VERSION ""

NS_ :

BS_:

BU_: MXC CGW

BO_ 3221225472 VECTOR__INDEPENDENT_SIG_MSG: 0 Vector__XXX
 SG_ ESC_Logger17_Byte3 : 0|8@1+ (1,0) [0|0] "" Vector__XXX
 SG_ ESC_Logger17_Byte4 : 0|8@1+ (1,0) [0|0] "" Vector__XXX
 SG_ ESC_Logger17_Byte5 : 0|8@1+ (1,0) [0|0] "" Vector__XXX
 SG_ ESC_Logger17_Byte6 : 0|8@1+ (1,0) [0|0] "" Vector__XXX
 SG_ ESC_Logger17_Byte7 : 0|8@1+ (1,0) [0|0] "" Vector__XXX
 SG_ ESC_Logger17_Byte1 : 0|8@1+ (1,0) [0|0] "" Vector__XXX
 SG_ ESC_Logger18_Byte0 : 0|8@1+ (1,0) [0|0] "" Vector__XXX
 SG_ ESC_Logger18_Byte2 : 0|8@1+ (1,0) [0|0] "" Vector__XXX
 SG_ ESC_Logger18_Byte3 : 0|8@1+ (1,0) [0|0] "" Vector__XXX
 SG_ ESC_Logger18_Byte4 : 0|8@1+ (1,0) [0|0] "" Vector__XXX
 SG_ ESC_Logger18_Byte5 : 0|8@1+ (1,0) [0|0] "" Vector__XXX
 SG_ ESC_Logger18_Byte6 : 0|8@1+ (1,0) [0|0] "" Vector__XXX
 SG_ ESC_Logger18_Byte7 : 0|8@1+ (1,0) [0|0] "" Vector__XXX
 SG_ ESC_Logger18_Byte1 : 0|8@1+ (1,0) [0|0] "" Vector__XXX
 SG_ ESC_Logger19_Byte0 : 0|8@1+ (1,0) [0|0] "" Vector__XXX
 SG_ ESC_Logger19_Byte2 : 0|8@1+ (1,0) [0|0] "" Vector__XXX
 SG_ ESC_Logger19_Byte3 : 0|8@1+ (1,0) [0|0] "" Vector__XXX
 SG_ ESC_Logger19_Byte4 : 0|8@1+ (1,0) [0|0] "" Vector__XXX
 SG_ ESC_Logger19_Byte5 : 0|8@1+ (1,0) [0|0] "" Vector__XXX
 SG_ ESC_Logger19_Byte6 : 0|8@1+ (1,0) [0|0] "" Vector__XXX
 SG_ ESC_Logger19_Byte7 : 0|8@1+ (1,0) [0|0] "" Vector__XXX
 SG_ ESC_Logger19_Byte1 : 0|8@1+ (1,0) [0|0] "" Vector__XXX
 SG_ WAKEUP_Crc1Val : 0|8@1+ (1,0) [0|0] "" Vector__XXX
 SG_ WakeUp_DoorLock_DrvDrUnLkSta : 0|2@1+ (1,0) [0|0] "" Vector__XXX
 SG_ WAKEUP_AlvCnt1Val : 0|4@1+ (1,0) [0|0] "" Vector__XXX
 SG_ WakeUp_BCM_Ign1InSta : 0|2@1+ (1,0) [0|0] "" Vector__XXX
 SG_ WakeUp_RKE_BtnReq : 0|4@1+ (1,0) [0|0] "" Vector__XXX
 SG_ WakeUp_Lamp_SmrtWlcmLtOnReq : 0|2@1+ (1,0) [0|0] "" Vector__XXX
 SG_ WakeUp_DoorLock_AsstDrUnLkSta : 0|2@1+ (1,0) [0|0] "" Vector__XXX
 SG_ WakeUp_DoorLock_RrLftDrUnLkSta : 0|2@1+ (1,0) [0|0] "" Vector__XXX
 SG_ WakeUp_DoorLock_RrRtDrUnLkSta : 0|2@1+ (1,0) [0|0] "" Vector__XXX
 SG_ WakeUp_Warn_AsstDrSwSta : 0|2@1+ (1,0) [0|0] "" Vector__XXX
 SG_ WakeUp_Warn_RrLftDrSwSta : 0|2@1+ (1,0) [0|0] "" Vector__XXX
 SG_ WakeUp_Warn_RrRtDrSwSta : 0|2@1+ (1,0) [0|0] "" Vector__XXX
 SG_ WakeUp_Trunk_TrnkTlgtSwSta : 0|2@1+ (1,0) [0|0] "" Vector__XXX
 SG_ WakeUp_Warn_DrvDrSwSta : 0|2@1+ (1,0) [0|0] "" Vector__XXX
 SG_ ODS_Crc1Val : 0|16@1+ (1,0) [0|0] "" Vector__XXX
 SG_ ODS_AlvCnt1Val : 0|8@1+ (1,0) [0|0] "" Vector__XXX
 SG_ ODS_IdVal : 0|8@1+ (1,0) [0|0] "" Vector__XXX
 SG_ ODS_OccClassSta : 0|8@1+ (1,0) [0|0] "" Vector__XXX
 SG_ ODS_DiagSta : 0|8@1+ (1,0) [0|0] "" Vector__XXX
 SG_ ODS_SBRClassSta : 0|8@1+ (1,0) [0|0] "" Vector__XXX
 SG_ ICU_Crc11Val : 0|8@1+ (1,0) [0|0] "" Vector__XXX
 SG_ Bat_dischrg : 0|2@1+ (1,0) [0|0] "" Vector__XXX
 SG_ ICU_AlvCnt11Val : 0|4@1+ (1,0) [0|0] "" Vector__XXX
 SG_ Batt_SoCWarningValue : 0|8@1+ (1,0) [0|0] "%" Vector__XXX
 SG_ Batt_SoCAlertValue : 0|8@1+ (1,0) [0|0] "%" Vector__XXX
 SG_ C_StrgWhlHeatingOpt : 0|2@1+ (1,0) [0|0] "" Vector__XXX
 SG_ BCM_Crc2Val : 0|8@1+ (1,0) [0|0] "" Vector__XXX
 SG_ BCM_AlvCnt2Val : 0|4@1+ (1,0) [0|0] "" Vector__XXX
 SG_ BAlarm_BglrAlrmCurrentSta : 0|4@1+ (1,0) [0|0] "" Vector__XXX
 SG_ BAlarm_BglrAlrmSta : 0|2@1+ (1,0) [0|0] "" Vector__XXX
 SG_ BAlarm_PncAlrmSta : 0|2@1+ (1,0) [0|0] "" Vector__XXX
 SG_ BAlarm_BrglrHrnRlySta : 0|2@1+ (1,0) [0|0] "" Vector__XXX
 SG_ BCM_AccInSta : 0|2@1+ (1,0) [0|0] "" Vector__XXX
 SG_ BCM_Ign1InSta : 0|2@1+ (1,0) [0|0] "" Vector__XXX
 SG_ BCM_Ign2InSta : 0|2@1+ (1,0) [0|0] "" Vector__XXX
 SG_ BCM_IgnSwSta : 0|3@1+ (1,0) [0|0] "" Vector__XXX
 SG_ CCP_MDPS_RESP1_Byte0 : 0|8@1+ (1,0) [0|0] "" Vector__XXX
 SG_ CCP_MDPS_RESP1_Byte2 : 0|8@1+ (1,0) [0|0] "" Vector__XXX
 SG_ CCP_MDPS_RESP1_Byte3 : 0|8@1+ (1,0) [0|0] "" Vector__XXX
 SG_ CCP_MDPS_RESP1_Byte4 : 0|8@1+ (1,0) [0|0] "" Vector__XXX
 SG_ CCP_MDPS_RESP1_Byte5 : 0|8@1+ (1,0) [0|0] "" Vector__XXX
 SG_ CCP_MDPS_RESP1_Byte6 : 0|8@1+ (1,0) [0|0] "" Vector__XXX
 SG_ CCP_MDPS_RESP1_Byte7 : 0|8@1+ (1,0) [0|0] "" Vector__XXX
 SG_ CCP_MDPS_RESP1_Byte1 : 0|8@1+ (1,0) [0|0] "" Vector__XXX
 SG_ CCP_MDPS_REQ5_Byte0 : 0|8@1+ (1,0) [0|0] "" Vector__XXX
 SG_ CCP_MDPS_REQ5_Byte2 : 0|8@1+ (1,0) [0|0] "" Vector__XXX
 SG_ CCP_MDPS_REQ5_Byte3 : 0|8@1+ (1,0) [0|0] "" Vector__XXX
 SG_ CCP_MDPS_REQ5_Byte4 : 0|8@1+ (1,0) [0|0] "" Vector__XXX
 SG_ CCP_MDPS_REQ5_Byte5 : 0|8@1+ (1,0) [0|0] "" Vector__XXX
 SG_ CCP_MDPS_REQ5_Byte6 : 0|8@1+ (1,0) [0|0] "" Vector__XXX
 SG_ CCP_MDPS_REQ5_Byte7 : 0|8@1+ (1,0) [0|0] "" Vector__XXX
 SG_ CCP_MDPS_REQ5_Byte1 : 0|8@1+ (1,0) [0|0] "" Vector__XXX
 SG_ CCP_MDPS_RESP3_Byte0 : 0|8@1+ (1,0) [0|0] "" Vector__XXX
 SG_ CCP_MDPS_RESP3_Byte2 : 0|8@1+ (1,0) [0|0] "" Vector__XXX
 SG_ CCP_MDPS_RESP3_Byte3 : 0|8@1+ (1,0) [0|0] "" Vector__XXX
 SG_ CCP_MDPS_RESP3_Byte4 : 0|8@1+ (1,0) [0|0] "" Vector__XXX
 SG_ CCP_MDPS_RESP3_Byte5 : 0|8@1+ (1,0) [0|0] "" Vector__XXX
 SG_ CCP_MDPS_RESP3_Byte6 : 0|8@1+ (1,0) [0|0] "" Vector__XXX
 SG_ CCP_MDPS_RESP3_Byte7 : 0|8@1+ (1,0) [0|0] "" Vector__XXX
 SG_ CCP_MDPS_RESP3_Byte1 : 0|8@1+ (1,0) [0|0] "" Vector__XXX
 SG_ CCP_MDPS_RESP2_Byte0 : 0|8@1+ (1,0) [0|0] "" Vector__XXX
 SG_ CCP_MDPS_RESP2_Byte2 : 0|8@1+ (1,0) [0|0] "" Vector__XXX
 SG_ CCP_MDPS_RESP2_Byte3 : 0|8@1+ (1,0) [0|0] "" Vector__XXX
 SG_ CCP_MDPS_RESP2_Byte4 : 0|8@1+ (1,0) [0|0] "" Vector__XXX
 SG_ CCP_MDPS_RESP2_Byte5 : 0|8@1+ (1,0) [0|0] "" Vector__XXX
 SG_ CCP_MDPS_RESP2_Byte6 : 0|8@1+ (1,0) [0|0] "" Vector__XXX
 SG_ CCP_MDPS_RESP2_Byte7 : 0|8@1+ (1,0) [0|0] "" Vector__XXX
 SG_ CCP_MDPS_RESP2_Byte1 : 0|8@1+ (1,0) [0|0] "" Vector__XXX
 SG_ CCP_MDPS_REQ2_Byte0 : 0|8@1+ (1,0) [0|0] "" Vector__XXX
 SG_ CCP_MDPS_REQ2_Byte2 : 0|8@1+ (1,0) [0|0] "" Vector__XXX
 SG_ CCP_MDPS_REQ2_Byte3 : 0|8@1+ (1,0) [0|0] "" Vector__XXX
 SG_ CCP_MDPS_REQ2_Byte4 : 0|8@1+ (1,0) [0|0] "" Vector__XXX
 SG_ CCP_MDPS_REQ2_Byte5 : 0|8@1+ (1,0) [0|0] "" Vector__XXX
 SG_ CCP_MDPS_REQ2_Byte6 : 0|8@1+ (1,0) [0|0] "" Vector__XXX
 SG_ CCP_MDPS_REQ2_Byte7 : 0|8@1+ (1,0) [0|0] "" Vector__XXX
 SG_ CCP_MDPS_REQ2_Byte1 : 0|8@1+ (1,0) [0|0] "" Vector__XXX
 SG_ CCP_MDPS_REQ1_Byte0 : 0|8@1+ (1,0) [0|0] "" Vector__XXX
 SG_ CCP_MDPS_REQ1_Byte2 : 0|8@1+ (1,0) [0|0] "" Vector__XXX
 SG_ CCP_MDPS_REQ1_Byte3 : 0|8@1+ (1,0) [0|0] "" Vector__XXX
 SG_ CCP_MDPS_REQ1_Byte4 : 0|8@1+ (1,0) [0|0] "" Vector__XXX
 SG_ CCP_MDPS_REQ1_Byte5 : 0|8@1+ (1,0) [0|0] "" Vector__XXX
 SG_ CCP_MDPS_REQ1_Byte6 : 0|8@1+ (1,0) [0|0] "" Vector__XXX
 SG_ CCP_MDPS_REQ1_Byte7 : 0|8@1+ (1,0) [0|0] "" Vector__XXX
 SG_ CCP_MDPS_REQ1_Byte1 : 0|8@1+ (1,0) [0|0] "" Vector__XXX
 SG_ CCP_MDPS_REQ4_Byte0 : 0|8@1+ (1,0) [0|0] "" Vector__XXX
 SG_ CCP_MDPS_REQ4_Byte2 : 0|8@1+ (1,0) [0|0] "" Vector__XXX
 SG_ CCP_MDPS_REQ4_Byte3 : 0|8@1+ (1,0) [0|0] "" Vector__XXX
 SG_ CCP_MDPS_REQ4_Byte4 : 0|8@1+ (1,0) [0|0] "" Vector__XXX
 SG_ CCP_MDPS_REQ4_Byte5 : 0|8@1+ (1,0) [0|0] "" Vector__XXX
 SG_ CCP_MDPS_REQ4_Byte6 : 0|8@1+ (1,0) [0|0] "" Vector__XXX
 SG_ CCP_MDPS_REQ4_Byte7 : 0|8@1+ (1,0) [0|0] "" Vector__XXX
 SG_ CCP_MDPS_REQ4_Byte1 : 0|8@1+ (1,0) [0|0] "" Vector__XXX
 SG_ CCP_MDPS_REQ3_Byte0 : 0|8@1+ (1,0) [0|0] "" Vector__XXX
 SG_ CCP_MDPS_REQ3_Byte2 : 0|8@1+ (1,0) [0|0] "" Vector__XXX
 SG_ CCP_MDPS_REQ3_Byte3 : 0|8@1+ (1,0) [0|0] "" Vector__XXX
 SG_ CCP_MDPS_REQ3_Byte4 : 0|8@1+ (1,0) [0|0] "" Vector__XXX
 SG_ CCP_MDPS_REQ3_Byte5 : 0|8@1+ (1,0) [0|0] "" Vector__XXX
 SG_ CCP_MDPS_REQ3_Byte6 : 0|8@1+ (1,0) [0|0] "" Vector__XXX
 SG_ CCP_MDPS_REQ3_Byte7 : 0|8@1+ (1,0) [0|0] "" Vector__XXX
 SG_ CCP_MDPS_REQ3_Byte1 : 0|8@1+ (1,0) [0|0] "" Vector__XXX
 SG_ CF_AVN_CluWelcomeSnd : 0|2@1+ (1,0) [0|0] "" Vector__XXX
 SG_ CF_AVN_CluTransmissionDisp : 0|2@1+ (1,0) [0|0] "" Vector__XXX
 SG_ CF_AVN_CluWiperLight : 0|2@1+ (1,0) [0|0] "" Vector__XXX
 SG_ CF_AVN_CluRoadInfoGuide : 0|2@1+ (1,0) [0|0] "" Vector__XXX
 SG_ CF_AVN_CluUserSettingPeriod : 0|7@1+ (1,0) [0|0] "" Vector__XXX
 SG_ CF_AVN_CluAutoInitFuelEconomy : 0|3@1+ (1,0) [0|0] "" Vector__XXX
 SG_ CF_AVN_CluSubspeedOdometerDisp : 0|2@1+ (1,0) [0|0] "" Vector__XXX
 SG_ CF_AVN_CluFuelEconUnit_mi : 0|2@1+ (1,0) [0|0] "" Vector__XXX
 SG_ CF_AVN_CluFuelEconUnit_km : 0|2@1+ (1,0) [0|0] "" Vector__XXX
 SG_ CF_AVN_CluUserSettingDistance : 0|17@1+ (1,0) [0|0] "" Vector__XXX
 SG_ CF_AVN_CluVoiceVolume : 0|3@1+ (1,0) [0|0] "" Vector__XXX
 SG_ CF_AVN_EVReset : 0|2@1+ (1,0) [0|0] "" Vector__XXX
 SG_ CF_AVN_UnitReset : 0|2@1+ (1,0) [0|0] "" Vector__XXX
 SG_ CF_AVN_IcyRoadWarn : 0|2@1+ (1,0) [0|0] "" Vector__XXX
 SG_ CF_AVN_CluServiceReminderReset : 0|2@1+ (1,0) [0|0] "" Vector__XXX
 SG_ CF_AVN_CluUSMReset : 0|2@1+ (1,0) [0|0] "" Vector__XXX
 SG_ CF_AVN_CluServiceReminderSet : 0|2@1+ (1,0) [0|0] "" Vector__XXX
 SG_ EPB_Crc1Val : 0|16@1+ (1,0) [0|0] "" Vector__XXX
 SG_ EPB_AlvCnt1Val : 0|8@1+ (1,0) [0|0] "" Vector__XXX
 SG_ EPB_LmpStaDis : 0|4@1+ (1,0) [0|0] "" Vector__XXX
 SG_ EPB_FlrLmpStaDis : 0|4@1+ (1,0) [0|0] "" Vector__XXX
 SG_ EPB_OutDataDis : 0|8@1+ (1,0) [0|0] "" Vector__XXX
 SG_ EPB_AlrmReq : 0|2@1+ (1,0) [0|0] "" Vector__XXX
 SG_ EPB_SwPosSta : 0|2@1+ (1,0) [0|0] "" Vector__XXX
 SG_ EPB_RrBrkLtActvReq : 0|2@1+ (1,0) [0|0] "" Vector__XXX
 SG_ EPB_FrcErrSta : 0|2@1+ (1,0) [0|0] "" Vector__XXX
 SG_ EPB_DynmBrkFrcReqSigSta : 0|2@1+ (1,0) [0|0] "" Vector__XXX
 SG_ EPB_FrcSta : 0|3@1+ (1,0) [0|0] "" Vector__XXX
 SG_ EPB_FlSta : 0|3@1+ (1,0) [0|0] "" Vector__XXX
 SG_ EPB_EscReqAckSta : 0|2@1+ (1,0) [0|0] "" Vector__XXX
 SG_ EPB_DynmBrkFrcReq : 0|2@1+ (1,0) [0|0] "" Vector__XXX
 SG_ EPB_ActlFrcVal : 0|12@1+ (1,-1000) [0|0] "" Vector__XXX
 SG_ EPB_DynmBrkFrcDclReq : 0|8@1+ (0.01,0) [0|0] "g" Vector__XXX
 SG_ CCP_MDPS_RESP5_Byte0 : 0|8@1+ (1,0) [0|0] "" Vector__XXX
 SG_ CCP_MDPS_RESP5_Byte2 : 0|8@1+ (1,0) [0|0] "" Vector__XXX
 SG_ CCP_MDPS_RESP5_Byte3 : 0|8@1+ (1,0) [0|0] "" Vector__XXX
 SG_ CCP_MDPS_RESP5_Byte4 : 0|8@1+ (1,0) [0|0] "" Vector__XXX
 SG_ CCP_MDPS_RESP5_Byte5 : 0|8@1+ (1,0) [0|0] "" Vector__XXX
 SG_ CCP_MDPS_RESP5_Byte6 : 0|8@1+ (1,0) [0|0] "" Vector__XXX
 SG_ CCP_MDPS_RESP5_Byte7 : 0|8@1+ (1,0) [0|0] "" Vector__XXX
 SG_ CCP_MDPS_RESP5_Byte1 : 0|8@1+ (1,0) [0|0] "" Vector__XXX
 SG_ CCP_MDPS_RESP4_Byte0 : 0|8@1+ (1,0) [0|0] "" Vector__XXX
 SG_ CCP_MDPS_RESP4_Byte2 : 0|8@1+ (1,0) [0|0] "" Vector__XXX
 SG_ CCP_MDPS_RESP4_Byte3 : 0|8@1+ (1,0) [0|0] "" Vector__XXX
 SG_ CCP_MDPS_RESP4_Byte4 : 0|8@1+ (1,0) [0|0] "" Vector__XXX
 SG_ CCP_MDPS_RESP4_Byte5 : 0|8@1+ (1,0) [0|0] "" Vector__XXX
 SG_ CCP_MDPS_RESP4_Byte6 : 0|8@1+ (1,0) [0|0] "" Vector__XXX
 SG_ CCP_MDPS_RESP4_Byte7 : 0|8@1+ (1,0) [0|0] "" Vector__XXX
 SG_ CCP_MDPS_RESP4_Byte1 : 0|8@1+ (1,0) [0|0] "" Vector__XXX
 SG_ ICU_Crc1Val : 0|8@1+ (1,0) [0|0] "" Vector__XXX
 SG_ ICU_AlvCnt1Val : 0|4@1+ (1,0) [0|0] "" Vector__XXX
 SG_ DoorLock_DrvrDrUnLkPsvAcsReq : 0|2@1+ (1,0) [0|0] "" Vector__XXX
 SG_ DoorLock_RmtKeyDrvrDrUnLkReq : 0|2@1+ (1,0) [0|0] "" Vector__XXX
 SG_ SEG_V2_Offset : 0|13@1+ (1,0) [0|0] "m" Vector__XXX
 SG_ SEG_V2_PathIndex : 0|6@1+ (1,0) [0|0] "" Vector__XXX
 SG_ SEG_V2_CyclicCounter : 0|2@1+ (1,0) [0|0] "" Vector__XXX
 SG_ SEG_V2_Retransmission : 0|1@1+ (1,0) [0|0] "" Vector__XXX
 SG_ SEG_V2_CalculatedRoute : 0|2@1+ (1,0) [0|0] "" Vector__XXX
 SG_ SEG_V2_FuncRoadClass : 0|3@1+ (1,0) [0|0] "" Vector__XXX
 SG_ SEG_V2_SpeedLimit : 0|5@1+ (1,0) [0|0] "" Vector__XXX
 SG_ SEG_V2_FormOfWay : 0|4@1+ (1,0) [0|0] "" Vector__XXX
 SG_ SEG_V2_DirectionLanes : 0|4@1+ (1,0) [0|0] "" Vector__XXX
 SG_ SEG_V2_SpeedLimitUnder5 : 0|3@1+ (1,0) [0|0] "" Vector__XXX
 SG_ RR_C_RDR_Crc1Val : 0|16@1+ (1,0) [0|0] "" Vector__XXX
 SG_ FR_C_RDR_RR_C_RDR_FCA_Plus_Sta : 0|2@1+ (1,0) [0|0] "" Vector__XXX
 SG_ RR_C_RDR_AlvCnt1Val : 0|8@1+ (1,0) [0|0] "" Vector__XXX
 SG_ RCCW_Sta : 0|4@1+ (1,0) [0|0] "" Vector__XXX
 SG_ RCCW_OnOffEquipSt : 0|2@1+ (1,0) [0|0] "" Vector__XXX
 SG_ RCCW_LftIndSta : 0|2@1+ (1,0) [0|0] "" Vector__XXX
 SG_ RCCW_RtIndSta : 0|2@1+ (1,0) [0|0] "" Vector__XXX
 SG_ RCCW_LftSndWrngSta : 0|2@1+ (1,0) [0|0] "" Vector__XXX
 SG_ RCCW_RtSndWrngSta : 0|2@1+ (1,0) [0|0] "" Vector__XXX
 SG_ RCCW_LftWrngIndBriLvlVal : 0|8@1+ (1,0) [0|0] "" Vector__XXX
 SG_ RCCW_RtWrngIndBriLvlVal : 0|8@1+ (1,0) [0|0] "" Vector__XXX
 SG_ RCCA_Deccel_Req : 0|4@1+ (0.04,0) [0|0] "g" Vector__XXX
 SG_ RCCA_BrkCmdSta : 0|2@1+ (1,0) [0|0] "" Vector__XXX
 SG_ RCCA_LftWrngSta : 0|2@1+ (1,0) [0|0] "" Vector__XXX
 SG_ RCCA_RtWrngSta : 0|2@1+ (1,0) [0|0] "" Vector__XXX
 SG_ RCCA_FuncStat : 0|2@1+ (1,0) [0|0] "" Vector__XXX
 SG_ RCCA_Sta : 0|4@1+ (1,0) [0|0] "" Vector__XXX
 SG_ RCCA_OnOffEquipSt : 0|2@1+ (1,0) [0|0] "" Vector__XXX
 SG_ SEA_Sta : 0|4@1+ (1,0) [0|0] "" Vector__XXX
 SG_ SEA_OnOffEquipSta : 0|2@1+ (1,0) [0|0] "" Vector__XXX
 SG_ SEA_LftWrngSta : 0|2@1+ (1,0) [0|0] "" Vector__XXX
 SG_ SEA_RtWrngSta : 0|2@1+ (1,0) [0|0] "" Vector__XXX
 SG_ MFSW_Crc2Val : 0|8@1+ (1,0) [0|0] "" Vector__XXX
 SG_ MFSW_AlvCnt2Val : 0|4@1+ (1,0) [0|0] "" Vector__XXX
 SG_ Wiper_FrWiperSwSta : 0|3@1+ (1,0) [0|0] "" Vector__XXX
 SG_ Wiper_IntStepSta : 0|3@1+ (1,0) [0|0] "" Vector__XXX
 SG_ Wiper_MstSwSta : 0|2@1+ (1,0) [0|0] "" Vector__XXX
 SG_ Wiper_FrWiperWshSwSta : 0|2@1+ (1,0) [0|0] "" Vector__XXX
 SG_ MFSW_Info : 0|2@1+ (1,0) [0|0] "" Vector__XXX
 SG_ PROLONG_V2_Value : 0|32@1+ (1,0) [0|0] "" Vector__XXX
 SG_ PROLONG_V2_Offset : 0|13@1+ (1,0) [0|0] "m" Vector__XXX
 SG_ PROLONG_V2_CyclicCounter : 0|2@1+ (1,0) [0|0] "" Vector__XXX
 SG_ PROLONG_V2_Update : 0|1@1+ (1,0) [0|0] "" Vector__XXX
 SG_ PROLONG_V2_PathIndex : 0|6@1+ (1,0) [0|0] "" Vector__XXX
 SG_ PROLONG_V2_ProfileType : 0|5@1+ (1,0) [0|0] "" Vector__XXX
 SG_ VCU_Crc2Val : 0|16@1+ (1,0) [0|0] "" Vector__XXX
 SG_ VCU_MaxRgnWhlTqRearVal : 0|16@1+ (1,0) [0|65535] "Nm" Vector__XXX
 SG_ VCU_CrpWhlTqFrntVal : 0|16@1- (1,0) [-32768|32767] "Nm" Vector__XXX
 SG_ VCU_CrpWhlTqRearVal : 0|16@1- (1,0) [-32768|32767] "Nm" Vector__XXX
 SG_ VCU_AlvCnt2Val : 0|8@1+ (1,0) [0|0] "" Vector__XXX
 SG_ VCU_RegenBrkWhlTqFrntVal : 0|16@1+ (1,0) [0|65535] "Nm" Vector__XXX
 SG_ VCU_RegenBrkWhlTqRearVal : 0|16@1+ (1,0) [0|65535] "Nm" Vector__XXX
 SG_ VCU_RspaOpSta : 0|4@1+ (1,0) [0|8] "" Vector__XXX
 SG_ VCU_RspaCanFailSta : 0|2@1+ (1,0) [0|3] "" Vector__XXX
 SG_ VCU_BrkLampOnReq : 0|2@1+ (1,0) [0|0] "" Vector__XXX
 SG_ VCU_StdMotTqFrntVal : 0|8@1+ (5,0) [0|1275] "Nm" Vector__XXX
 SG_ VCU_StdMotTqRearVal : 0|8@1+ (5,0) [0|1275] "Nm" Vector__XXX
 SG_ VCU_MotTqCmdBInvFrntPcVal : 0|12@1- (0.048828125,0) [-100|99.95] "%" Vector__XXX
 SG_ VCU_MotTqCmdBInvRearPcVal : 0|12@1- (0.048828125,0) [-100|99.95] "%" Vector__XXX
 SG_ VCU_MotTqCmdFrntPcVal : 0|12@1- (0.048828125,0) [-100|99.95] "%" Vector__XXX
 SG_ VCU_MotTqCmdRearPcVal : 0|12@1- (0.048828125,0) [-100|99.95] "%" Vector__XXX
 SG_ VCU_RegenEnaFrntSta : 0|2@1+ (1,0) [0|3] "" Vector__XXX
 SG_ VCU_RegenEnaRearSta : 0|2@1+ (1,0) [0|3] "" Vector__XXX
 SG_ VCU_4wdModSta : 0|2@1+ (1,0) [0|3] "" Vector__XXX
 SG_ VCU_EpbEngageReq : 0|2@1+ (1,0) [0|3] "" Vector__XXX
 SG_ VCU_MaxRgnWhlTqFrntVal : 0|16@1+ (1,0) [0|65535] "Nm" Vector__XXX
 SG_ RSC_TqIntrvntnVal_Frnt : 0|8@1+ (0.390625,0) [0|0] "%" Vector__XXX
 SG_ RSC_TqIntrvntnVal_Rear : 0|8@1+ (0.390625,0) [0|0] "%" Vector__XXX

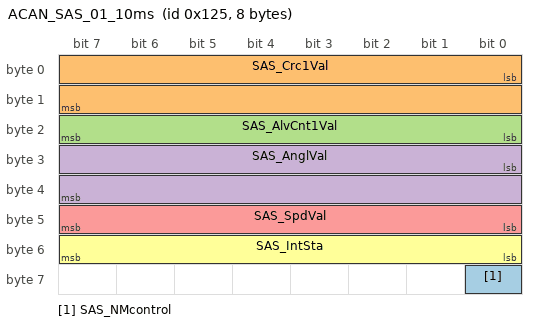
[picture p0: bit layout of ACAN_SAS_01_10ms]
BO_ 293 ACAN_SAS_01_10ms: 8 MXC
 SG_ SAS_NMcontrol : 56|1@1+ (1,0) [0|1] "" Vector__XXX
 SG_ SAS_Crc1Val : 0|16@1+ (1,0) [0|0] ""  CGW
 SG_ SAS_AlvCnt1Val : 16|8@1+ (1,0) [0|0] ""  CGW
 SG_ SAS_AnglVal : 24|16@1- (0.1,0) [-3276.8|3276.7] "Deg"  CGW
 SG_ SAS_SpdVal : 40|8@1+ (4,0) [0|0] "Deg/s"  CGW
 SG_ SAS_IntSta : 48|8@1+ (1,0) [0|0] ""  CGW

BO_ 101 ACAN_IEB_01_10ms: 24 MXC
 SG_ IEB_AccPedDepVal : 176|8@1+ (1,0) [0|100] "%" Vector__XXX
 SG_ IEB_Crc1Val : 0|16@1+ (1,0) [0|0] ""  CGW
 SG_ IEB_StrkDpthPcVal : 104|8@1+ (1,0) [0|100] "%"  CGW
 SG_ IEB_EstDpthPcVal : 112|8@1+ (0.390625,0) [0|0] "%"  CGW
 SG_ IEB_AbsNGearReq : 120|2@1+ (1,0) [0|0] ""  CGW
 SG_ IEB_EstBrkPdlValVldSta : 122|2@1+ (1,0) [0|0] ""  CGW
 SG_ IEB_InhbtTrnstnTo4wd_Req : 124|2@1+ (1,0) [0|0] "" Vector__XXX
 SG_ IEB_RegenTqLimitNmVal_Rear : 128|16@1+ (1,0) [0|0] "Nm" Vector__XXX
 SG_ IEB_TCS_Req : 152|2@1+ (1,0) [0|0] "" Vector__XXX
 SG_ IEB_RSC_Req : 154|2@1+ (1,0) [0|0] "" Vector__XXX
 SG_ TCS_TqFlag_Frnt : 156|1@1+ (1,0) [0|0] "" Vector__XXX
 SG_ TCS_TqFlag_Rear : 157|1@1+ (1,0) [0|0] "" Vector__XXX
 SG_ RSC_TqFlag_Frnt : 158|1@1+ (1,0) [0|0] "" Vector__XXX
 SG_ RSC_TqFlag_Rear : 159|1@1+ (1,0) [0|0] "" Vector__XXX
 SG_ IEB_AlvCnt1Val : 16|8@1+ (1,0) [0|0] ""  CGW
 SG_ TCS_TqIntrvntnVal_Frnt : 160|8@1+ (0.390625,0) [0|0] "%" Vector__XXX
 SG_ TCS_TqIntrvntnVal_Rear : 168|8@1+ (0.390625,0) [0|0] "%" Vector__XXX
 SG_ IEB_SrvLmpDis : 24|2@1+ (1,0) [0|0] ""  CGW
 SG_ IEB_DfctvSta : 26|2@1+ (1,0) [0|0] ""  CGW
 SG_ IEB_ActvSta : 28|2@1+ (1,0) [0|0] ""  CGW
 SG_ IEB_DiagSta : 30|2@1+ (1,0) [0|0] ""  CGW
 SG_ IEB_WrngLmpDis : 32|2@1+ (1,0) [0|0] ""  CGW
 SG_ IEB_MILReq : 34|2@1+ (1,0) [0|0] "" Vector__XXX
 SG_ IEB_StrkDpthmmVal : 40|16@1- (0.1,0) [0|0] "mm"  CGW
 SG_ IEB_BrkActvSta : 56|2@1+ (1,0) [0|0] ""  CGW
 SG_ IEB_PdlTrvlSnsrFailSta : 58|2@1+ (1,0) [0|0] ""  CGW
 SG_ IEB_PdlCalibSta : 60|2@1+ (1,0) [0|0] ""  CGW
 SG_ IEB_BzrSta : 62|2@1+ (1,0) [0|0] ""  CGW
 SG_ IEB_Sta : 64|2@1+ (1,0) [0|0] ""  CGW
 SG_ IEB_SnsrFailSta : 66|2@1+ (1,0) [0|0] ""  CGW
 SG_ IEB_RbsWrngLmpSta : 68|2@1+ (1,0) [0|0] ""  CGW
 SG_ IEB_VacSysDfctvSta : 70|2@1+ (1,0) [0|0] ""  CGW
 SG_ IEB_RegenTqLimitNmVal_Frnt : 72|16@1+ (1,0) [0|0] "Nm"  CGW
 SG_ IEB_EstTtlBrkFrcNmVal : 88|16@1+ (1,0) [0|0] "Nm"  CGW

BO_ 418 ACAN_CLU_01_10ms: 16 CGW
 SG_ CLU_NMcontrol : 24|1@1+ (1,0) [0|1] ""  MXC
 SG_ CLU_EngineRPM : 80|17@1+ (0.1,0) [0|9000] ""  MXC
 SG_ CLU_Crc1Val : 0|16@1+ (1,0) [0|0] ""  MXC
 SG_ CLU_AlvCnt1Val : 16|8@1+ (1,0) [0|0] ""  MXC
 SG_ CLU_DtntOutSta : 28|2@1+ (1,0) [0|0] ""  MXC
 SG_ CLU_SpdUnitTyp : 30|2@1+ (1,0) [0|0] ""  MXC
 SG_ CLU_DisSpdDcmlVal : 32|2@1+ (0.125,0) [0|0] ""  MXC
 SG_ CLU_RhstaLvlSta : 43|5@1+ (1,0) [0|0] ""  MXC
 SG_ CLU_DisSpdVal : 48|10@1+ (0.5,0) [0|0] "km/h or MPH"  MXC
 SG_ CLU_DisTyp : 58|2@1+ (1,0) [0|0] ""  MXC
 SG_ CLU_DisSpdVal_KPH : 64|9@1+ (1,0) [0|0] "km/h"  MXC

CM_ SG_ 3221225472 WAKEUP_Crc1Val "WAKEUP_CyclicRedundancyCheck1Value";
CM_ SG_ 3221225472 WakeUp_DoorLock_DrvDrUnLkSta "For Wakeup : DoorLock_DriverDoorUnLockStatus ##2G## -  - C_DrvUnlockState,CF_Gway_DrvUnlockState";
CM_ SG_ 3221225472 WAKEUP_AlvCnt1Val "WAKEUP_AliveCounter1Value";
CM_ SG_ 3221225472 WakeUp_BCM_Ign1InSta "For Wakeup : BCM_Ignition1InputStatus ##2G##BCM - BCMmsg17 - C_Ign1";
CM_ SG_ 3221225472 WakeUp_RKE_BtnReq "For Wakeup : RemoteKey_ButtonRequest ##2G##BCM - BCMmsg01 - C_RKECmd";
CM_ SG_ 3221225472 WakeUp_Lamp_SmrtWlcmLtOnReq "For Wakeup : Lamp_SmartWelcomeLightOnRequest ##2G##SMK - SMKmsg17 - C_WlightOn";
CM_ SG_ 3221225472 WakeUp_DoorLock_AsstDrUnLkSta "For Wakeup : DoorLock_AssistDoorUnLockStatus ##2G## -  - C_AstUnlockState,DoorLock_AsstDrUnLkSta";
CM_ SG_ 3221225472 WakeUp_DoorLock_RrLftDrUnLkSta "For Wakeup : DoorLock_RearLeftDoorUnLockStatus ##2G## -  - C_RLUnlockState,DoorLock_RrLftDrUnLkSta";
CM_ SG_ 3221225472 WakeUp_DoorLock_RrRtDrUnLkSta "For Wakeup : DoorLock_RearRightDoorUnLockStatus ##2G## -  - C_RRUnlockState,DoorLock_RrRtDrUnLkSta";
CM_ SG_ 3221225472 WakeUp_Warn_AsstDrSwSta "For Wakeup : Warn_AssistDoorSwitchStatus ##2G## -  - C_AstDrSw,CF_Gway_AstDrSw,Warn_AsstDrSwSta";
CM_ SG_ 3221225472 WakeUp_Warn_RrLftDrSwSta "For Wakeup : Warn_RearLeftDoorSwitchStatus ##2G## -  - C_RLDrSw,CF_Gway_RLDrSw,Warn_RrLftDrSwSta";
CM_ SG_ 3221225472 WakeUp_Warn_RrRtDrSwSta "For Wakeup : Warn_RearRightDoorSwitchStatus ##2G## -  - C_RRDrSw,CF_Gway_RRDrSw,Warn_RrRtDrSwSta";
CM_ SG_ 3221225472 WakeUp_Trunk_TrnkTlgtSwSta "For Wakeup : Trunk_TrunkTailgateSwitchStatus ##2G## -  - C_TrunkTgSw,CF_Gway_TrunkTgSw,Trunk_TrnkTlgtSwSta";
CM_ SG_ 3221225472 WakeUp_Warn_DrvDrSwSta "For Wakeup : DoorLock_DriverDoorSwitchStatus ##2G## -  - C_DrvDrSw,CF_Gway_DrvDrSw,Warn_DrvDrSwSta";
CM_ SG_ 3221225472 ODS_Crc1Val "ODS_CyclicRedundancyCheck1Value";
CM_ SG_ 3221225472 ODS_AlvCnt1Val "ODS_AliveCounter1Value";
CM_ SG_ 3221225472 ODS_IdVal "ODS_IdValue ##2G##ODS - ODS13 - CR_Ods_ID";
CM_ SG_ 3221225472 ODS_OccClassSta "ODS_OccupantClassificationStatus ##2G##ODS - ODS11 - CR_Wcs_ClassStat";
CM_ SG_ 3221225472 ODS_DiagSta "ODS_SelfDiagnosticStatus ##2G##ODS - ODS11 - CR_Wcs_ErrStat";
CM_ SG_ 3221225472 ODS_SBRClassSta "ODS_SBRClassSta";
CM_ SG_ 3221225472 ICU_Crc11Val "ICU_CyclicRedundancyCheck11Value";
CM_ SG_ 3221225472 Bat_dischrg "Battery discharge notification flag #2G# Bat_dischrg";
CM_ SG_ 3221225472 ICU_AlvCnt11Val "ICU_AliveCounter11Value";
CM_ SG_ 3221225472 Batt_SoCWarningValue "Value of SoC warning level. ##2G## -  - Batt_SoCWarningValue";
CM_ SG_ 3221225472 Batt_SoCAlertValue "Value of SoC alert level ##2G## -  - Batt_SoCAlertValue";
CM_ SG_ 3221225472 BCM_Crc2Val "BCM_CyclicRedundancyCheck2Value";
CM_ SG_ 3221225472 BCM_AlvCnt2Val "BCM_AliveCounter2Value";
CM_ SG_ 3221225472 BAlarm_BglrAlrmCurrentSta "BAlarm_BuglarAlarmCurrentStatus ##2G##BCM - BCMmsg17 - C_BAlarmState";
CM_ SG_ 3221225472 BAlarm_BglrAlrmSta "BAlarm_BuglarAlarmStatus ##2G##BCM - BCMmsg17 - C_BAState";
CM_ SG_ 3221225472 BAlarm_PncAlrmSta "BAlarm_PanicAlarmStatus ##2G##BCM - BCMmsg17 - C_PanicState";
CM_ SG_ 3221225472 BAlarm_BrglrHrnRlySta "BAlarm_BurglarHornRelayStatus ##2G##BCM - BCMmsg19 - C_BurglarHornRly";
CM_ SG_ 3221225472 BCM_AccInSta "BCM_AccInputStatus ##2G##BCM - BCMmsg17 - C_Acc";
CM_ SG_ 3221225472 BCM_Ign1InSta "BCM_Ignition1InputStatus ##2G##BCM - BCMmsg17 - C_Ign1";
CM_ SG_ 3221225472 BCM_Ign2InSta "BCM_Ignition1InputStatus ##2G##BCM - BCMmsg17 - C_Ign2";
CM_ SG_ 3221225472 BCM_IgnSwSta "BCM_IgnitionSwitchStatus ##2G##BCM - BCMmsg17 - C_IGNSw";
CM_ SG_ 3221225472 CF_AVN_CluWelcomeSnd "Request to set CLU welcome soun";
CM_ SG_ 3221225472 CF_AVN_CluTransmissionDisp "Request to set CLU transmission display";
CM_ SG_ 3221225472 CF_AVN_CluWiperLight "Request to set CLU wiper & light mode";
CM_ SG_ 3221225472 CF_AVN_CluRoadInfoGuide "Request to set CLU road info guidance";
CM_ SG_ 3221225472 CF_AVN_CluUserSettingPeriod "Request to set CLU sservice period set by user";
CM_ SG_ 3221225472 CF_AVN_CluAutoInitFuelEconomy "Request to set CLU auto initailizing fuel economy";
CM_ SG_ 3221225472 CF_AVN_CluSubspeedOdometerDisp "Request to set CLU Subscale Odometer";
CM_ SG_ 3221225472 CF_AVN_CluFuelEconUnit_mi "Cluster setting status for cluster Fuel Economy Unit (mile)";
CM_ SG_ 3221225472 CF_AVN_CluFuelEconUnit_km "Cluster setting status for cluster Fuel Economy unit (km)";
CM_ SG_ 3221225472 CF_AVN_CluUserSettingDistance "Request to set CLU service distance set by user";
CM_ SG_ 3221225472 CF_AVN_CluVoiceVolume "Request to set CLU Volume level";
CM_ SG_ 3221225472 CF_AVN_EVReset "Request to reset EV Service (0x1 : EV USM Reset)";
CM_ SG_ 3221225472 CF_AVN_UnitReset "Request to reset Unit setting";
CM_ SG_ 3221225472 CF_AVN_IcyRoadWarn "Request to set CLU icy road warning";
CM_ SG_ 3221225472 CF_AVN_CluServiceReminderReset "Request to reset CLU service reminder";
CM_ SG_ 3221225472 CF_AVN_CluUSMReset "Request to reset all USM service";
CM_ SG_ 3221225472 CF_AVN_CluServiceReminderSet "Request to set CLU service notification";
CM_ SG_ 3221225472 EPB_Crc1Val "EPB_CyclicRedundancyCheck1Value";
CM_ SG_ 3221225472 EPB_AlvCnt1Val "EPB_AliveCounter1Value";
CM_ SG_ 3221225472 EPB_LmpStaDis "EPB_LampStateDisplay ##2G##EPB - EPB11 - EPB_I_LAMP";
CM_ SG_ 3221225472 EPB_FlrLmpStaDis "EPB_FailureLampStateDisplay ##2G##EPB - EPB11 - EPB_F_LAMP";
CM_ SG_ 3221225472 EPB_OutDataDis "EPB_OutputDataDisplay ##2G##EPB - EPB11 - EPB_CLU";
CM_ SG_ 3221225472 EPB_AlrmReq "EPB_AlarmRequest ##2G##EPB - EPB11 - EPB_ALARM";
CM_ SG_ 3221225472 EPB_SwPosSta "EPB_SwitchPositionStatus ##2G##EPB - EPB11 - EPB_SWITCH";
CM_ SG_ 3221225472 EPB_RrBrkLtActvReq "EPB_RearBrakeLightActivationRequest ##2G##EPB - EPB11 - EPB_RBL";
CM_ SG_ 3221225472 EPB_FrcErrSta "EPB_ForceErrorStatus ##2G##EPB - EPB11 - EPB_FRC_ERR";
CM_ SG_ 3221225472 EPB_DynmBrkFrcReqSigSta "EPB_DynamicBrakingForceRequestSignalStatus ##2G##EPB - EPB11 - EPB_DBF_STAT";
CM_ SG_ 3221225472 EPB_FrcSta "EPB_ForceStatus ##2G##EPB - EPB11 - EPB_STATUS";
CM_ SG_ 3221225472 EPB_FlSta "EPB_FailStatus ##2G##EPB - EPB11 - EPB_FAIL";
CM_ SG_ 3221225472 EPB_EscReqAckSta "EPB_EscRequestAcknowledgeStatus ##2G##EPB - EPB11 - ESP_ACK";
CM_ SG_ 3221225472 EPB_DynmBrkFrcReq "EPB_DynamicBrakingForceRequest ##2G##EPB - EPB11 - EPB_DBF_REQ";
CM_ SG_ 3221225472 EPB_ActlFrcVal "EPB_ActualForceValue ##2G##EPB - EPB11 - EPB_FORCE";
CM_ SG_ 3221225472 EPB_DynmBrkFrcDclReq "EPB_DynamicBrakingForceDecelerationRequest ##2G##EPB - EPB11 - EPB_DBF_DECEL";
CM_ SG_ 3221225472 ICU_Crc1Val "ICU_CyclicRedundancyCheck1Value";
CM_ SG_ 3221225472 ICU_AlvCnt1Val "ICU_AliveCounter1Value";
CM_ SG_ 3221225472 DoorLock_DrvrDrUnLkPsvAcsReq "DoorLock_DriverDoorUnLockPassiveAccessRequest ##2G## -  - C_PassiveDRVUnlockCmd";
CM_ SG_ 3221225472 DoorLock_RmtKeyDrvrDrUnLkReq "DoorLock_RkeDriverDoorUnLockRequest ##2G## -  - C_RKEDRVUnlockCmd";
CM_ SG_ 3221225472 SEG_V2_Offset "Information for Offset of this Segment from current position";
CM_ SG_ 3221225472 SEG_V2_PathIndex "Information for Index of path of which this segment is part";
CM_ SG_ 3221225472 SEG_V2_CyclicCounter "Information for Cyclic counter of this message type: Reconstructor can use this value to detect missing messages";
CM_ SG_ 3221225472 SEG_V2_Retransmission "Information for Retransmission Flag: If true, this message was sent already at least once before.";
CM_ SG_ 3221225472 SEG_V2_CalculatedRoute "Information for Calculated Route: MPP/On Route/Off Route(Recalculating Route)
-MPP: Predicted Route(Not the Link from Searched Route). Used if users don��t set Destination. Used with Current Link Information.
-On Route: Link from Searched Route. Used with Current Link Information.
-Off Route: Used when trying to enter the Rest Area. 'SEG_CalculatedRoute', 'SEG_FormOfWay' and 'SEG_FunctionalRoadClass' are used together. But if it is impossible to decide values of 'SEG_FormOfWay' and 'SEG_FunctionalRoadClass', transmitt Unknown Value. If additional Information happens in forward unit distance, retransmitt it by Event.";
CM_ SG_ 3221225472 SEG_V2_FuncRoadClass "Information for Functional Road Class indicates relative importance of the road in the routing network and lower values indicate higher priority";
CM_ SG_ 3221225472 SEG_V2_SpeedLimit "Information for Current Link Speed Limit expressed as km/h or mph according to META_SpeedUnit";
CM_ SG_ 3221225472 SEG_V2_FormOfWay "Information for Link Class Value of Segment";
CM_ SG_ 3221225472 SEG_V2_DirectionLanes "Information for the Number of lanes in driving direction";
CM_ SG_ 3221225472 SEG_V2_SpeedLimitUnder5 "Current Link Speed Limit of less than 5 kph or mph according to META_SpeedUnit";
CM_ SG_ 3221225472 RR_C_RDR_Crc1Val "RR_C_RDR_CyclicRedundancyCheck1Value";
CM_ SG_ 3221225472 FR_C_RDR_RR_C_RDR_FCA_Plus_Sta "������ ���̴�/������ ���̴� ǻ�� Ʈ���� �̿��Ͽ� FCA-Car/Ped/Cyc+�ý��ۿ� �����ϴ� ���� ����/���� ���� ȸ�� �Ұ��� ���� �Ǵ�";
CM_ SG_ 3221225472 RR_C_RDR_AlvCnt1Val "RR_C_RDR_AliveCounter1Value";
CM_ SG_ 3221225472 RCCW_Sta "RCCW_Status ##2G##BCW - BCW11 - CF_RCCW_Stat";
CM_ SG_ 3221225472 RCCW_OnOffEquipSt "RCCW_OnOffEquipmentStatus ##2G##BCW - BCW12 - CF_RCCW_USM";
CM_ SG_ 3221225472 RCCW_LftIndSta "RCCW_LeftIndicatorStatus ##2G##BCW - BCW11 - CF_RCCW_IndLeft";
CM_ SG_ 3221225472 RCCW_RtIndSta "RCCW_RightIndicatorStatus ##2G##BCW - BCW11 - CF_RCCW_IndRight";
CM_ SG_ 3221225472 RCCW_LftSndWrngSta "RCCW_LeftSoundWarningStatus ##2G##BCW - BCW11 - CF_RL_SndWan";
CM_ SG_ 3221225472 RCCW_RtSndWrngSta "RCCW_RightSoundWarningStatus ##2G##BCW - BCW11 - CF_RR_SndWan";
CM_ SG_ 3221225472 RCCW_LftWrngIndBriLvlVal "RCCW_LeftWarningIndicatorBrightnessLevelValue ##2G##BCW - BCW11 - CF_RCCW_IndBriLeft";
CM_ SG_ 3221225472 RCCW_RtWrngIndBriLvlVal "RCCW_RightWarningIndicatorBrightnessLevelValue ##2G##BCW - BCW11 - CF_RCCW_IndBriRight";
CM_ SG_ 3221225472 RCCA_Deccel_Req "RCCA_Deccel_Requirement ##2G##BCW - BCA11 - CF_RCCA_Decel_Req";
CM_ SG_ 3221225472 RCCA_BrkCmdSta "RCCA_BrakeCommandStatus ##2G##BCW - BCA11 - RCCA_Brake_Command";
CM_ SG_ 3221225472 RCCA_LftWrngSta "RCCA_LeftWarningStatus ##2G##BCW - BCA11 - CF_RCCA_WarnLh";
CM_ SG_ 3221225472 RCCA_RtWrngSta "RCCA_RightWarningStatus ##2G##BCW - BCA11 - CF_RCCA_WarnRh";
CM_ SG_ 3221225472 RCCA_FuncStat "RCCA_FunctionStatus ##2G##BCW - BCA11 - CF_RCCA_FuncState";
CM_ SG_ 3221225472 RCCA_Sta "RCCA_Status";
CM_ SG_ 3221225472 RCCA_OnOffEquipSt "RCCA_OnOffEquipmentStatus ##2G##BCW - BCW12 - CF_RCCA_USM";
CM_ SG_ 3221225472 SEA_Sta "SEA_Status";
CM_ SG_ 3221225472 SEA_OnOffEquipSta "SEA_OnOffEquipmentStatus ##2G##BCW - BCW12 - CF_SEA_USM";
CM_ SG_ 3221225472 SEA_LftWrngSta "SEA_LeftWarningStatus ##2G##BCW - BCA11 - CF_SEA_Warn_Lh";
CM_ SG_ 3221225472 SEA_RtWrngSta "SEA_RightWarningStatus ##2G##BCW - BCA11 - CF_SEA_Warn_Rh";
CM_ SG_ 3221225472 MFSW_Crc2Val "MFSW_CyclicRedundancyCheck2Value";
CM_ SG_ 3221225472 MFSW_AlvCnt2Val "MFSW_AliveCounter2Value";
CM_ SG_ 3221225472 Wiper_FrWiperSwSta "Wiper_FrontWiperSwitchStatus";
CM_ SG_ 3221225472 Wiper_IntStepSta "Wiper_IntermittentStepStatus";
CM_ SG_ 3221225472 Wiper_MstSwSta "Wiper_MistSwitchStatus";
CM_ SG_ 3221225472 Wiper_FrWiperWshSwSta "Wiper_FrontWiperWasherSwitchStatus";
CM_ SG_ 3221225472 MFSW_Info "MFSW_Information_Type";
CM_ SG_ 3221225472 PROLONG_V2_Value "Information for Profile Long value at Offset";
CM_ SG_ 3221225472 PROLONG_V2_Offset "Information for Offset of position of the first profile spot from currnet position";
CM_ SG_ 3221225472 PROLONG_V2_CyclicCounter "Information for Cyclic counter of this message type and profile type: Reconstructor can use this value to detect missing messages
-Applying particularly according to PROLONG_ProfileType
 Ex) ProfileType(CyclicCounter): 0x1(0)  0x1(1)  0x10(0)  0x1(2)  0x10(1) ��";
CM_ SG_ 3221225472 PROLONG_V2_Update "Updated information of already transmitted Profile Long
-If Overspeed Check Camera Information is updated by Wireless Network of TPEG, set 'True' about Updated Field of Profile Long Message and transmitt it. Refer to '5.7.8' in specification for detail";
CM_ SG_ 3221225472 PROLONG_V2_PathIndex "Information for Index of the path where this profile is located";
CM_ SG_ 3221225472 PROLONG_V2_ProfileType "Information for Profile Long Type(0~31)
-Refer to 'Table 19' in specification for detail";
CM_ SG_ 3221225472 VCU_Crc2Val "VCU_CyclicRedundancyCheck2Value";
CM_ SG_ 3221225472 VCU_MaxRgnWhlTqRearVal "VCU_MaximumRegenerativeWheelTorqueRearValue";
CM_ SG_ 3221225472 VCU_CrpWhlTqFrntVal "VCU_CreepWheelTorqueFrontValue";
CM_ SG_ 3221225472 VCU_CrpWhlTqRearVal "VCU_CreepWheelTorqueRearValue ##2G##VCU - VCU2 - CR_Vcu_CrpTq_Nm";
CM_ SG_ 3221225472 VCU_AlvCnt2Val "VCU_AliveCounter2Value";
CM_ SG_ 3221225472 VCU_RegenBrkWhlTqFrntVal "VCU_RegenerativeBrakingWheelTorqueFrontValue";
CM_ SG_ 3221225472 VCU_RegenBrkWhlTqRearVal "VCU_RegenerativeBrakingWheelTorqueRearValue ##2G##VCU - VCU2 - CR_Vcu_RegenBrkTq_Nm";
CM_ SG_ 3221225472 VCU_RspaOpSta "VCU_RspaOperatingStatus";
CM_ SG_ 3221225472 VCU_RspaCanFailSta "VCU_RspaCanFailStatus";
CM_ SG_ 3221225472 VCU_BrkLampOnReq "VCU_BrakeLampOnRequest ##2G##VCU - VCU5 - CF_Vcu_BrkLpReq";
CM_ SG_ 3221225472 VCU_StdMotTqFrntVal "VCU_StandardMotorTorqueFrontValue";
CM_ SG_ 3221225472 VCU_StdMotTqRearVal "VCU_StandardMotorTorqueRearValue ##2G##VCU - VCU1 - CR_Vcu_TqStd_Nm";
CM_ SG_ 3221225472 VCU_MotTqCmdBInvFrntPcVal "VCU_MotorTorqueCommandBeforeInterventionFrontPcValue";
CM_ SG_ 3221225472 VCU_MotTqCmdBInvRearPcVal "VCU_MotorTorqueCommandBeforeInterventionRearPcValue ##2G##VCU - VCU3 - CR_Vcu_MotTqCmdBInv_Pc";
CM_ SG_ 3221225472 VCU_MotTqCmdFrntPcVal "VCU_MotorTorqueCommandFrontPcValue";
CM_ SG_ 3221225472 VCU_MotTqCmdRearPcVal "VCU_MotorTorqueCommandRearPcValue ##2G##VCU - VCU3 - CR_Vcu_MotTqCmd_Pc";
CM_ SG_ 3221225472 VCU_RegenEnaFrntSta "VCU_RegenerativeEnableFrontStatus";
CM_ SG_ 3221225472 VCU_RegenEnaRearSta "VCU_RegenerativeEnableRearStatus ##2G##VCU - VCU2 - CF_Vcu_RegenEna";
CM_ SG_ 3221225472 VCU_4wdModSta "VCU_4wdModeStatus";
CM_ SG_ 3221225472 VCU_EpbEngageReq "VCU_EpbEngageRequest ##2G##VCU - VCU18 - CF_Vcu_EpbRequest";
CM_ SG_ 3221225472 VCU_MaxRgnWhlTqFrntVal "VCU_MaximumRegenerativeWheelTorqueFrontValue";
CM_ SG_ 3221225472 RSC_TqIntrvntnVal_Frnt "RSC_TorqueInterventionValue_Front";
CM_ SG_ 3221225472 RSC_TqIntrvntnVal_Rear "RSC_TorqueInterventionValue_Rear";
CM_ BO_ 293 "[P] Periodic";
CM_ SG_ 293 SAS_Crc1Val "SAS_CyclicRedundancyCheck1Value";
CM_ SG_ 293 SAS_AlvCnt1Val "SAS_AliveCounter1Value";
CM_ SG_ 293 SAS_AnglVal "SAS_AngleValue";
CM_ SG_ 293 SAS_SpdVal "SAS_SpeedValue";
CM_ SG_ 293 SAS_IntSta "SAS_InternalStatus";
CM_ BO_ 101 "[P] Periodic";
CM_ SG_ 101 IEB_Crc1Val "IEB_CyclicRedundancyCheck1Value";
CM_ SG_ 101 IEB_StrkDpthPcVal "IEB_StrokeDepthPcValue ##2G##ESC - EBS2 - CR_Brk_StkDep_Pc";
CM_ SG_ 101 IEB_EstDpthPcVal "IEB_EstimatedPedalDepthValue ##2G##ESC - EBS2 - CR_Brk_Est_StkDep_Pc";
CM_ SG_ 101 IEB_AbsNGearReq "IEB_AbsNGearRequest ##2G##ESC - TCS11 - CF_Brk_AbsNReq";
CM_ SG_ 101 IEB_EstBrkPdlValVldSta "IEB_EstimatedBrakePedalValueValidityStatus ##2G##ESC - EBS2 - CF_Brk_Est_StkValid";
CM_ SG_ 101 IEB_RegenTqLimitNmVal_Rear "IEB_RegenTorqueLimitValue Rear";
CM_ SG_ 101 IEB_TCS_Req "IEB_TCS_Request";
CM_ SG_ 101 IEB_RSC_Req "IEB_RSC_Request";
CM_ SG_ 101 TCS_TqFlag_Frnt "TCS_TorqueFlag_Front";
CM_ SG_ 101 TCS_TqFlag_Rear "TCS_TorqueFlag_Rear";
CM_ SG_ 101 RSC_TqFlag_Frnt "RSC_TorqueFlag_Front";
CM_ SG_ 101 RSC_TqFlag_Rear "RSC_TorqueFlag_Rear";
CM_ SG_ 101 IEB_AlvCnt1Val "IEB_AliveCounter1Value";
CM_ SG_ 101 TCS_TqIntrvntnVal_Frnt "TCS_TorqueInterventionValue_Front";
CM_ SG_ 101 TCS_TqIntrvntnVal_Rear "TCS_TorqueInterventionValue_Rear";
CM_ SG_ 101 IEB_SrvLmpDis "IEB_ServiceLampDisplay ##2G##ESC - AHB1 - CF_Ahb_SLmp";
CM_ SG_ 101 IEB_DfctvSta "IEB_DefectiveStatus ##2G##ESC - AHB1 - CF_Ahb_Def";
CM_ SG_ 101 IEB_ActvSta "IEB_ActiveStatus ##2G##ESC - AHB1 - CF_Ahb_Act";
CM_ SG_ 101 IEB_DiagSta "IEB_DiagnosticStatus ##2G##ESC - AHB1 - CF_Ahb_Diag";
CM_ SG_ 101 IEB_WrngLmpDis "IEB_WarningLampDisplay ##2G##ESC - AHB1 - CF_Ahb_WLmp";
CM_ SG_ 101 IEB_MILReq "MIL Requeset";
CM_ SG_ 101 IEB_StrkDpthmmVal "IEB_StrokeDepthmmValue ##2G##ESC - AHB1 - CR_Ahb_StDep_mm";
CM_ SG_ 101 IEB_BrkActvSta "IEB_BrakeActiveStatus ##2G##ESC - AHB1 - CF_Esc_BrakeAct";
CM_ SG_ 101 IEB_PdlTrvlSnsrFailSta "IEB_PedalTravelSensorFailStatus ##2G##ESC - AHB1 - CF_Ahb_SnsFail";
CM_ SG_ 101 IEB_PdlCalibSta "IEB_PedalCalibrationStatus ##2G##ESC - AHB1 - CF_Ahb_PedalCalStat";
CM_ SG_ 101 IEB_BzrSta "IEB_BuzzerStatus ##2G##ESC - AHB1 - CF_Ahb_Bzzr";
CM_ SG_ 101 IEB_Sta "IEB_Status ##2G##ESC - EBS1 - CF_Brk_EBSStat";
CM_ SG_ 101 IEB_SnsrFailSta "IEB_SensorFailStatus ##2G##ESC - EBS1 - CF_Brk_SnsFail";
CM_ SG_ 101 IEB_RbsWrngLmpSta "IEB_RbsWarningLamp ##2G##ESC - EBS1 - CF_Brk_RBSWLamp";
CM_ SG_ 101 IEB_VacSysDfctvSta "IEB_VacuumSystemDefectiveStatus ##2G##ESC - EBS1 - CF_Brk_VacuumSysDef";
CM_ SG_ 101 IEB_RegenTqLimitNmVal_Frnt "IEB_RegenTorqueLimitValue ##2G##ESC - EBS1 - CR_Brk_RegenTqLimit_Nm";
CM_ SG_ 101 IEB_EstTtlBrkFrcNmVal "IEB_EstimatedTotalBrakeForceValue ##2G##ESC - EBS1 - CR_Brk_EstTot_Nm";
CM_ BO_ 418 "[P] Periodic";
CM_ SG_ 418 CLU_Crc1Val "CLU_CyclicRedundancyCheck1Value";
CM_ SG_ 418 CLU_AlvCnt1Val "CLU_AliveCounter1Value";
CM_ SG_ 418 CLU_DtntOutSta "CLU_DetentOutStatus";
CM_ SG_ 418 CLU_SpdUnitTyp "CLU_SpeedUnitType";
CM_ SG_ 418 CLU_DisSpdDcmlVal "CLU_DisplaySpeedDecimalValue";
CM_ SG_ 418 CLU_RhstaLvlSta "CLU_RheostatLevelStatus";
CM_ SG_ 418 CLU_DisSpdVal "CLU_DisplaySpeedValue";
CM_ SG_ 418 CLU_DisTyp "CLU LCD DisplayType";
CM_ SG_ 418 CLU_DisSpdVal_KPH "CLU_DisplaySpeedValue_KPH";
BA_DEF_ BO_  "GenMsgEVName" STRING ;
BA_DEF_ BO_  "UsrMsgIDSforwardDeviation" INT 0 100;
BA_DEF_ BO_  "UsrMsgIDSbackwardDeviation" INT 50 1000;
BA_DEF_ BO_  "GenMsgCycleTime" INT 0 2000;
BA_DEF_ BO_  "GenMsgStartDelayTime" INT 0 2000;
BA_DEF_ BO_  "GenMsgSendType" ENUM  "Cyclic","NoMsgSendType";
BA_DEF_ BO_  "GenMsgCycleTimeFast" INT 0 500;
BA_DEF_ BO_  "GenMsgDelayTime" INT 0 20;
BA_DEF_ BO_  "GenMsgILSupport" ENUM  "No","Yes";
BA_DEF_ BO_  "GenMsgNrOfRepetition" INT 0 3;
BA_DEF_ BO_  "VFrameFormat" ENUM  "StandardCAN","ExtendedCAN","reserved","reserved","reserved","reserved","reserved","reserved","reserved","reserved","reserved","reserved","reserved","reserved","StandardCAN_FD","ExtendedCAN_FD";
BA_DEF_ SG_  "UserSigValidity" ENUM  "B+","ACC","IG","IG1","IG2","IG3","IG1 or IG2","IG1 or IG3","Undef";
BA_DEF_ SG_  "UsrSigPurpose" ENUM  "Undef","FN","DIAG","DIAG(Req)","DIAG(Res)","DIAG(Phy)","DEV","CCP(Req)","CCP(Res)","NM","TP";
BA_DEF_ SG_  "GenSigStartValue" INT 0 1215752192;
BA_DEF_ SG_  "NetworkRequest" ENUM  "Yes","No";
BA_DEF_ SG_  "NetworkRequestHoldingTime" INT 0 65535;
BA_DEF_ SG_  "Description" STRING ;
BA_DEF_ SG_  "Version" STRING ;
BA_DEF_ SG_  "GenSigEnvVarType" ENUM  "Int","Float","Undef";
BA_DEF_ SG_  "GenSigSendType" ENUM  "Cyclic","OnWrite","OnWriteWithRepetition","OnChange","OnChangeWithRepetition","IfActive","IfActiveWithRepetition","NoSigSendType","OnChangeAndIfActive","OnChangeAndIfActiveWithRepetition";
BA_DEF_ SG_  "GwSigLatencyTime" INT 0 65536;
BA_DEF_ SG_  "GwSigMissingSourceType" ENUM  "Undef","OldValue","DefaultValue","InitialValue";
BA_DEF_ SG_  "NWM-WakeupAllowed" ENUM  "<n.a.>";
BA_DEF_ SG_  "RoutingFactor" INT 1 1215752192;
BA_DEF_REL_ BU_SG_REL_  "GenSigTimeoutTime" INT 0 7000;
BA_DEF_DEF_  "GenMsgEVName" "@Signame";
BA_DEF_DEF_  "UsrMsgIDSforwardDeviation" 10;
BA_DEF_DEF_  "UsrMsgIDSbackwardDeviation" 100;
BA_DEF_DEF_  "GenMsgCycleTime" 200;
BA_DEF_DEF_  "GenMsgStartDelayTime" 0;
BA_DEF_DEF_  "GenMsgSendType" "NoMsgSendType";
BA_DEF_DEF_  "GenMsgCycleTimeFast" 40;
BA_DEF_DEF_  "GenMsgDelayTime" 20;
BA_DEF_DEF_  "GenMsgILSupport" "Yes";
BA_DEF_DEF_  "GenMsgNrOfRepetition" 3;
BA_DEF_DEF_  "VFrameFormat" "StandardCAN";
BA_DEF_DEF_  "UserSigValidity" "IG";
BA_DEF_DEF_  "UsrSigPurpose" "FN";
BA_DEF_DEF_  "GenSigStartValue" 0;
BA_DEF_DEF_  "NetworkRequest" "No";
BA_DEF_DEF_  "NetworkRequestHoldingTime" 0;
BA_DEF_DEF_  "Description" "";
BA_DEF_DEF_  "Version" "";
BA_DEF_DEF_  "GenSigEnvVarType" "Undef";
BA_DEF_DEF_  "GenSigSendType" "NoSigSendType";
BA_DEF_DEF_  "GwSigLatencyTime" 40;
BA_DEF_DEF_  "GwSigMissingSourceType" "Undef";
BA_DEF_DEF_  "NWM-WakeupAllowed" "<n.a.>";
BA_DEF_DEF_  "RoutingFactor" 1;
BA_DEF_DEF_REL_ "GenSigTimeoutTime" 500;
BA_ "GenMsgDelayTime" BO_ 293 0;
BA_ "GenMsgNrOfRepetition" BO_ 293 0;
BA_ "GenMsgCycleTimeFast" BO_ 293 0;
BA_ "GenMsgCycleTime" BO_ 293 10;
BA_ "GenMsgSendType" BO_ 293 0;
BA_ "VFrameFormat" BO_ 293 14;
BA_ "GenMsgDelayTime" BO_ 101 0;
BA_ "GenMsgNrOfRepetition" BO_ 101 0;
BA_ "GenMsgCycleTimeFast" BO_ 101 0;
BA_ "GenMsgCycleTime" BO_ 101 10;
BA_ "GenMsgSendType" BO_ 101 0;
BA_ "VFrameFormat" BO_ 101 14;
BA_ "GenMsgDelayTime" BO_ 418 0;
BA_ "GenMsgNrOfRepetition" BO_ 418 0;
BA_ "GenMsgCycleTimeFast" BO_ 418 0;
BA_ "GenMsgCycleTime" BO_ 418 10;
BA_ "GenMsgSendType" BO_ 418 0;
BA_ "VFrameFormat" BO_ 418 14;
BA_ "Version" SG_ 3221225472 ESC_Logger17_Byte3 "18.08.01";
BA_ "NetworkRequestHoldingTime" SG_ 3221225472 ESC_Logger17_Byte3 5000;
BA_ "NetworkRequest" SG_ 3221225472 ESC_Logger17_Byte3 0;
BA_ "UserSigValidity" SG_ 3221225472 ESC_Logger17_Byte3 0;
BA_ "GenSigSendType" SG_ 3221225472 ESC_Logger17_Byte3 2;
BA_ "UsrSigPurpose" SG_ 3221225472 ESC_Logger17_Byte3 6;
BA_ "Version" SG_ 3221225472 ESC_Logger17_Byte4 "18.08.01";
BA_ "NetworkRequestHoldingTime" SG_ 3221225472 ESC_Logger17_Byte4 5000;
BA_ "NetworkRequest" SG_ 3221225472 ESC_Logger17_Byte4 0;
BA_ "UserSigValidity" SG_ 3221225472 ESC_Logger17_Byte4 0;
BA_ "GenSigSendType" SG_ 3221225472 ESC_Logger17_Byte4 2;
BA_ "UsrSigPurpose" SG_ 3221225472 ESC_Logger17_Byte4 6;
BA_ "Version" SG_ 3221225472 ESC_Logger17_Byte5 "18.08.01";
BA_ "NetworkRequestHoldingTime" SG_ 3221225472 ESC_Logger17_Byte5 5000;
BA_ "NetworkRequest" SG_ 3221225472 ESC_Logger17_Byte5 0;
BA_ "UserSigValidity" SG_ 3221225472 ESC_Logger17_Byte5 0;
BA_ "GenSigSendType" SG_ 3221225472 ESC_Logger17_Byte5 2;
BA_ "UsrSigPurpose" SG_ 3221225472 ESC_Logger17_Byte5 6;
BA_ "Version" SG_ 3221225472 ESC_Logger17_Byte6 "18.08.01";
BA_ "NetworkRequestHoldingTime" SG_ 3221225472 ESC_Logger17_Byte6 5000;
BA_ "NetworkRequest" SG_ 3221225472 ESC_Logger17_Byte6 0;
BA_ "UserSigValidity" SG_ 3221225472 ESC_Logger17_Byte6 0;
BA_ "GenSigSendType" SG_ 3221225472 ESC_Logger17_Byte6 2;
BA_ "UsrSigPurpose" SG_ 3221225472 ESC_Logger17_Byte6 6;
BA_ "Version" SG_ 3221225472 ESC_Logger17_Byte7 "18.08.01";
BA_ "NetworkRequestHoldingTime" SG_ 3221225472 ESC_Logger17_Byte7 5000;
BA_ "NetworkRequest" SG_ 3221225472 ESC_Logger17_Byte7 0;
BA_ "UserSigValidity" SG_ 3221225472 ESC_Logger17_Byte7 0;
BA_ "GenSigSendType" SG_ 3221225472 ESC_Logger17_Byte7 2;
BA_ "UsrSigPurpose" SG_ 3221225472 ESC_Logger17_Byte7 6;
BA_ "Version" SG_ 3221225472 ESC_Logger17_Byte1 "18.08.01";
BA_ "NetworkRequestHoldingTime" SG_ 3221225472 ESC_Logger17_Byte1 5000;
BA_ "NetworkRequest" SG_ 3221225472 ESC_Logger17_Byte1 0;
BA_ "UserSigValidity" SG_ 3221225472 ESC_Logger17_Byte1 0;
BA_ "GenSigSendType" SG_ 3221225472 ESC_Logger17_Byte1 2;
BA_ "UsrSigPurpose" SG_ 3221225472 ESC_Logger17_Byte1 6;
BA_ "Version" SG_ 3221225472 ESC_Logger18_Byte0 "18.08.01";
BA_ "NetworkRequestHoldingTime" SG_ 3221225472 ESC_Logger18_Byte0 5000;
BA_ "NetworkRequest" SG_ 3221225472 ESC_Logger18_Byte0 0;
BA_ "UserSigValidity" SG_ 3221225472 ESC_Logger18_Byte0 0;
BA_ "GenSigSendType" SG_ 3221225472 ESC_Logger18_Byte0 2;
BA_ "UsrSigPurpose" SG_ 3221225472 ESC_Logger18_Byte0 6;
BA_ "Version" SG_ 3221225472 ESC_Logger18_Byte2 "18.08.01";
BA_ "NetworkRequestHoldingTime" SG_ 3221225472 ESC_Logger18_Byte2 5000;
BA_ "NetworkRequest" SG_ 3221225472 ESC_Logger18_Byte2 0;
BA_ "UserSigValidity" SG_ 3221225472 ESC_Logger18_Byte2 0;
BA_ "GenSigSendType" SG_ 3221225472 ESC_Logger18_Byte2 2;
BA_ "UsrSigPurpose" SG_ 3221225472 ESC_Logger18_Byte2 6;
BA_ "Version" SG_ 3221225472 ESC_Logger18_Byte3 "18.08.01";
BA_ "NetworkRequestHoldingTime" SG_ 3221225472 ESC_Logger18_Byte3 5000;
BA_ "NetworkRequest" SG_ 3221225472 ESC_Logger18_Byte3 0;
BA_ "UserSigValidity" SG_ 3221225472 ESC_Logger18_Byte3 0;
BA_ "GenSigSendType" SG_ 3221225472 ESC_Logger18_Byte3 2;
BA_ "UsrSigPurpose" SG_ 3221225472 ESC_Logger18_Byte3 6;
BA_ "Version" SG_ 3221225472 ESC_Logger18_Byte4 "18.08.01";
BA_ "NetworkRequestHoldingTime" SG_ 3221225472 ESC_Logger18_Byte4 5000;
BA_ "NetworkRequest" SG_ 3221225472 ESC_Logger18_Byte4 0;
BA_ "UserSigValidity" SG_ 3221225472 ESC_Logger18_Byte4 0;
BA_ "GenSigSendType" SG_ 3221225472 ESC_Logger18_Byte4 2;
BA_ "UsrSigPurpose" SG_ 3221225472 ESC_Logger18_Byte4 6;
BA_ "Version" SG_ 3221225472 ESC_Logger18_Byte5 "18.08.01";
BA_ "NetworkRequestHoldingTime" SG_ 3221225472 ESC_Logger18_Byte5 5000;
BA_ "NetworkRequest" SG_ 3221225472 ESC_Logger18_Byte5 0;
BA_ "UserSigValidity" SG_ 3221225472 ESC_Logger18_Byte5 0;
BA_ "GenSigSendType" SG_ 3221225472 ESC_Logger18_Byte5 2;
BA_ "UsrSigPurpose" SG_ 3221225472 ESC_Logger18_Byte5 6;
BA_ "Version" SG_ 3221225472 ESC_Logger18_Byte6 "18.08.01";
BA_ "NetworkRequestHoldingTime" SG_ 3221225472 ESC_Logger18_Byte6 5000;
BA_ "NetworkRequest" SG_ 3221225472 ESC_Logger18_Byte6 0;
BA_ "UserSigValidity" SG_ 3221225472 ESC_Logger18_Byte6 0;
BA_ "GenSigSendType" SG_ 3221225472 ESC_Logger18_Byte6 2;
BA_ "UsrSigPurpose" SG_ 3221225472 ESC_Logger18_Byte6 6;
BA_ "Version" SG_ 3221225472 ESC_Logger18_Byte7 "18.08.01";
BA_ "NetworkRequestHoldingTime" SG_ 3221225472 ESC_Logger18_Byte7 5000;
BA_ "NetworkRequest" SG_ 3221225472 ESC_Logger18_Byte7 0;
BA_ "UserSigValidity" SG_ 3221225472 ESC_Logger18_Byte7 0;
BA_ "GenSigSendType" SG_ 3221225472 ESC_Logger18_Byte7 2;
BA_ "UsrSigPurpose" SG_ 3221225472 ESC_Logger18_Byte7 6;
BA_ "Version" SG_ 3221225472 ESC_Logger18_Byte1 "18.08.01";
BA_ "NetworkRequestHoldingTime" SG_ 3221225472 ESC_Logger18_Byte1 5000;
BA_ "NetworkRequest" SG_ 3221225472 ESC_Logger18_Byte1 0;
BA_ "UserSigValidity" SG_ 3221225472 ESC_Logger18_Byte1 0;
BA_ "GenSigSendType" SG_ 3221225472 ESC_Logger18_Byte1 2;
BA_ "UsrSigPurpose" SG_ 3221225472 ESC_Logger18_Byte1 6;
BA_ "Version" SG_ 3221225472 ESC_Logger19_Byte0 "18.08.01";
BA_ "NetworkRequestHoldingTime" SG_ 3221225472 ESC_Logger19_Byte0 5000;
BA_ "NetworkRequest" SG_ 3221225472 ESC_Logger19_Byte0 0;
BA_ "UserSigValidity" SG_ 3221225472 ESC_Logger19_Byte0 0;
BA_ "GenSigSendType" SG_ 3221225472 ESC_Logger19_Byte0 2;
BA_ "UsrSigPurpose" SG_ 3221225472 ESC_Logger19_Byte0 6;
BA_ "Version" SG_ 3221225472 ESC_Logger19_Byte2 "18.08.01";
BA_ "NetworkRequestHoldingTime" SG_ 3221225472 ESC_Logger19_Byte2 5000;
BA_ "NetworkRequest" SG_ 3221225472 ESC_Logger19_Byte2 0;
BA_ "UserSigValidity" SG_ 3221225472 ESC_Logger19_Byte2 0;
BA_ "GenSigSendType" SG_ 3221225472 ESC_Logger19_Byte2 2;
BA_ "UsrSigPurpose" SG_ 3221225472 ESC_Logger19_Byte2 6;
BA_ "Version" SG_ 3221225472 ESC_Logger19_Byte3 "18.08.01";
BA_ "NetworkRequestHoldingTime" SG_ 3221225472 ESC_Logger19_Byte3 5000;
BA_ "NetworkRequest" SG_ 3221225472 ESC_Logger19_Byte3 0;
BA_ "UserSigValidity" SG_ 3221225472 ESC_Logger19_Byte3 0;
BA_ "GenSigSendType" SG_ 3221225472 ESC_Logger19_Byte3 2;
BA_ "UsrSigPurpose" SG_ 3221225472 ESC_Logger19_Byte3 6;
BA_ "Version" SG_ 3221225472 ESC_Logger19_Byte4 "18.08.01";
BA_ "NetworkRequestHoldingTime" SG_ 3221225472 ESC_Logger19_Byte4 5000;
BA_ "NetworkRequest" SG_ 3221225472 ESC_Logger19_Byte4 0;
BA_ "UserSigValidity" SG_ 3221225472 ESC_Logger19_Byte4 0;
BA_ "GenSigSendType" SG_ 3221225472 ESC_Logger19_Byte4 2;
BA_ "UsrSigPurpose" SG_ 3221225472 ESC_Logger19_Byte4 6;
BA_ "Version" SG_ 3221225472 ESC_Logger19_Byte5 "18.08.01";
BA_ "NetworkRequestHoldingTime" SG_ 3221225472 ESC_Logger19_Byte5 5000;
BA_ "NetworkRequest" SG_ 3221225472 ESC_Logger19_Byte5 0;
BA_ "UserSigValidity" SG_ 3221225472 ESC_Logger19_Byte5 0;
BA_ "GenSigSendType" SG_ 3221225472 ESC_Logger19_Byte5 2;
BA_ "UsrSigPurpose" SG_ 3221225472 ESC_Logger19_Byte5 6;
BA_ "Version" SG_ 3221225472 ESC_Logger19_Byte6 "18.08.01";
BA_ "NetworkRequestHoldingTime" SG_ 3221225472 ESC_Logger19_Byte6 5000;
BA_ "NetworkRequest" SG_ 3221225472 ESC_Logger19_Byte6 0;
BA_ "UserSigValidity" SG_ 3221225472 ESC_Logger19_Byte6 0;
BA_ "GenSigSendType" SG_ 3221225472 ESC_Logger19_Byte6 2;
BA_ "UsrSigPurpose" SG_ 3221225472 ESC_Logger19_Byte6 6;
BA_ "Version" SG_ 3221225472 ESC_Logger19_Byte7 "18.08.01";
BA_ "NetworkRequestHoldingTime" SG_ 3221225472 ESC_Logger19_Byte7 5000;
BA_ "NetworkRequest" SG_ 3221225472 ESC_Logger19_Byte7 0;
BA_ "UserSigValidity" SG_ 3221225472 ESC_Logger19_Byte7 0;
BA_ "GenSigSendType" SG_ 3221225472 ESC_Logger19_Byte7 2;
BA_ "UsrSigPurpose" SG_ 3221225472 ESC_Logger19_Byte7 6;
BA_ "Version" SG_ 3221225472 ESC_Logger19_Byte1 "18.08.01";
BA_ "NetworkRequestHoldingTime" SG_ 3221225472 ESC_Logger19_Byte1 5000;
BA_ "NetworkRequest" SG_ 3221225472 ESC_Logger19_Byte1 0;
BA_ "UserSigValidity" SG_ 3221225472 ESC_Logger19_Byte1 0;
BA_ "GenSigSendType" SG_ 3221225472 ESC_Logger19_Byte1 2;
BA_ "UsrSigPurpose" SG_ 3221225472 ESC_Logger19_Byte1 6;
BA_ "Version" SG_ 3221225472 WAKEUP_Crc1Val "19.06.03";
BA_ "NetworkRequestHoldingTime" SG_ 3221225472 WAKEUP_Crc1Val 5000;
BA_ "NetworkRequest" SG_ 3221225472 WAKEUP_Crc1Val 0;
BA_ "UserSigValidity" SG_ 3221225472 WAKEUP_Crc1Val 0;
BA_ "GenSigStartValue" SG_ 3221225472 WAKEUP_Crc1Val 255;
BA_ "GenSigSendType" SG_ 3221225472 WAKEUP_Crc1Val 4;
BA_ "Description" SG_ 3221225472 WAKEUP_Crc1Val "The data area for CRC calculation is based on the data length (DLC) of the message DB.

The CRC shall be calculated over the entire data block (excluding the CRC bytes) including the user data, alive counter and Data ID 

 

- CRC Polynomial (0x1D) , Ini";
BA_ "Version" SG_ 3221225472 WakeUp_DoorLock_DrvDrUnLkSta "19.08.00";
BA_ "NetworkRequestHoldingTime" SG_ 3221225472 WakeUp_DoorLock_DrvDrUnLkSta 5000;
BA_ "NetworkRequest" SG_ 3221225472 WakeUp_DoorLock_DrvDrUnLkSta 0;
BA_ "UserSigValidity" SG_ 3221225472 WakeUp_DoorLock_DrvDrUnLkSta 0;
BA_ "GenSigStartValue" SG_ 3221225472 WakeUp_DoorLock_DrvDrUnLkSta 2;
BA_ "GenSigSendType" SG_ 3221225472 WakeUp_DoorLock_DrvDrUnLkSta 4;
BA_ "Version" SG_ 3221225472 WAKEUP_AlvCnt1Val "19.06.03";
BA_ "NetworkRequestHoldingTime" SG_ 3221225472 WAKEUP_AlvCnt1Val 5000;
BA_ "NetworkRequest" SG_ 3221225472 WAKEUP_AlvCnt1Val 0;
BA_ "UserSigValidity" SG_ 3221225472 WAKEUP_AlvCnt1Val 0;
BA_ "GenSigSendType" SG_ 3221225472 WAKEUP_AlvCnt1Val 4;
BA_ "Description" SG_ 3221225472 WAKEUP_AlvCnt1Val "For the first transmission request for a data element the counter shall be initialized with 0 and shall be incremented by 1

for every subsequent send request. When the counter reaches the maximum value(0xE), then it shall restart with 0 for the next sen";
BA_ "Version" SG_ 3221225472 WakeUp_BCM_Ign1InSta "19.06.03";
BA_ "NetworkRequestHoldingTime" SG_ 3221225472 WakeUp_BCM_Ign1InSta 5000;
BA_ "NetworkRequest" SG_ 3221225472 WakeUp_BCM_Ign1InSta 0;
BA_ "UserSigValidity" SG_ 3221225472 WakeUp_BCM_Ign1InSta 0;
BA_ "GenSigSendType" SG_ 3221225472 WakeUp_BCM_Ign1InSta 4;
BA_ "Version" SG_ 3221225472 WakeUp_RKE_BtnReq "19.06.03";
BA_ "NetworkRequestHoldingTime" SG_ 3221225472 WakeUp_RKE_BtnReq 5000;
BA_ "NetworkRequest" SG_ 3221225472 WakeUp_RKE_BtnReq 0;
BA_ "UserSigValidity" SG_ 3221225472 WakeUp_RKE_BtnReq 0;
BA_ "GenSigSendType" SG_ 3221225472 WakeUp_RKE_BtnReq 4;
BA_ "Description" SG_ 3221225472 WakeUp_RKE_BtnReq "Remote Key Button Request from Folding Key or Smart Key";
BA_ "Version" SG_ 3221225472 WakeUp_Lamp_SmrtWlcmLtOnReq "19.06.03";
BA_ "NetworkRequestHoldingTime" SG_ 3221225472 WakeUp_Lamp_SmrtWlcmLtOnReq 5000;
BA_ "NetworkRequest" SG_ 3221225472 WakeUp_Lamp_SmrtWlcmLtOnReq 0;
BA_ "UserSigValidity" SG_ 3221225472 WakeUp_Lamp_SmrtWlcmLtOnReq 0;
BA_ "GenSigSendType" SG_ 3221225472 WakeUp_Lamp_SmrtWlcmLtOnReq 4;
BA_ "Description" SG_ 3221225472 WakeUp_Lamp_SmrtWlcmLtOnReq "Smart Key welcome light on request.";
BA_ "Version" SG_ 3221225472 WakeUp_DoorLock_AsstDrUnLkSta "19.08.00";
BA_ "NetworkRequestHoldingTime" SG_ 3221225472 WakeUp_DoorLock_AsstDrUnLkSta 5000;
BA_ "NetworkRequest" SG_ 3221225472 WakeUp_DoorLock_AsstDrUnLkSta 0;
BA_ "UserSigValidity" SG_ 3221225472 WakeUp_DoorLock_AsstDrUnLkSta 0;
BA_ "GenSigStartValue" SG_ 3221225472 WakeUp_DoorLock_AsstDrUnLkSta 2;
BA_ "GenSigSendType" SG_ 3221225472 WakeUp_DoorLock_AsstDrUnLkSta 4;
BA_ "Version" SG_ 3221225472 WakeUp_DoorLock_RrLftDrUnLkSta "19.08.00";
BA_ "NetworkRequestHoldingTime" SG_ 3221225472 WakeUp_DoorLock_RrLftDrUnLkSta 5000;
BA_ "NetworkRequest" SG_ 3221225472 WakeUp_DoorLock_RrLftDrUnLkSta 0;
BA_ "UserSigValidity" SG_ 3221225472 WakeUp_DoorLock_RrLftDrUnLkSta 0;
BA_ "GenSigStartValue" SG_ 3221225472 WakeUp_DoorLock_RrLftDrUnLkSta 2;
BA_ "GenSigSendType" SG_ 3221225472 WakeUp_DoorLock_RrLftDrUnLkSta 4;
BA_ "Version" SG_ 3221225472 WakeUp_DoorLock_RrRtDrUnLkSta "19.08.00";
BA_ "NetworkRequestHoldingTime" SG_ 3221225472 WakeUp_DoorLock_RrRtDrUnLkSta 5000;
BA_ "NetworkRequest" SG_ 3221225472 WakeUp_DoorLock_RrRtDrUnLkSta 0;
BA_ "UserSigValidity" SG_ 3221225472 WakeUp_DoorLock_RrRtDrUnLkSta 0;
BA_ "GenSigStartValue" SG_ 3221225472 WakeUp_DoorLock_RrRtDrUnLkSta 2;
BA_ "GenSigSendType" SG_ 3221225472 WakeUp_DoorLock_RrRtDrUnLkSta 4;
BA_ "Version" SG_ 3221225472 WakeUp_Warn_AsstDrSwSta "19.08.00";
BA_ "NetworkRequestHoldingTime" SG_ 3221225472 WakeUp_Warn_AsstDrSwSta 5000;
BA_ "NetworkRequest" SG_ 3221225472 WakeUp_Warn_AsstDrSwSta 0;
BA_ "UserSigValidity" SG_ 3221225472 WakeUp_Warn_AsstDrSwSta 0;
BA_ "GenSigStartValue" SG_ 3221225472 WakeUp_Warn_AsstDrSwSta 2;
BA_ "GenSigSendType" SG_ 3221225472 WakeUp_Warn_AsstDrSwSta 4;
BA_ "Version" SG_ 3221225472 WakeUp_Warn_RrLftDrSwSta "19.08.00";
BA_ "NetworkRequestHoldingTime" SG_ 3221225472 WakeUp_Warn_RrLftDrSwSta 5000;
BA_ "NetworkRequest" SG_ 3221225472 WakeUp_Warn_RrLftDrSwSta 0;
BA_ "UserSigValidity" SG_ 3221225472 WakeUp_Warn_RrLftDrSwSta 0;
BA_ "GenSigStartValue" SG_ 3221225472 WakeUp_Warn_RrLftDrSwSta 2;
BA_ "GenSigSendType" SG_ 3221225472 WakeUp_Warn_RrLftDrSwSta 4;
BA_ "Version" SG_ 3221225472 WakeUp_Warn_RrRtDrSwSta "19.08.00";
BA_ "NetworkRequestHoldingTime" SG_ 3221225472 WakeUp_Warn_RrRtDrSwSta 5000;
BA_ "NetworkRequest" SG_ 3221225472 WakeUp_Warn_RrRtDrSwSta 0;
BA_ "UserSigValidity" SG_ 3221225472 WakeUp_Warn_RrRtDrSwSta 0;
BA_ "GenSigStartValue" SG_ 3221225472 WakeUp_Warn_RrRtDrSwSta 2;
BA_ "GenSigSendType" SG_ 3221225472 WakeUp_Warn_RrRtDrSwSta 4;
BA_ "Version" SG_ 3221225472 WakeUp_Trunk_TrnkTlgtSwSta "19.08.00";
BA_ "NetworkRequestHoldingTime" SG_ 3221225472 WakeUp_Trunk_TrnkTlgtSwSta 5000;
BA_ "NetworkRequest" SG_ 3221225472 WakeUp_Trunk_TrnkTlgtSwSta 0;
BA_ "UserSigValidity" SG_ 3221225472 WakeUp_Trunk_TrnkTlgtSwSta 0;
BA_ "GenSigStartValue" SG_ 3221225472 WakeUp_Trunk_TrnkTlgtSwSta 2;
BA_ "GenSigSendType" SG_ 3221225472 WakeUp_Trunk_TrnkTlgtSwSta 4;
BA_ "Description" SG_ 3221225472 WakeUp_Trunk_TrnkTlgtSwSta "Full Lock SW Status Signal



(TailGate/TrunkLid Tpye all)



1. Luggage or Trunkroom Lamp On/Off



2. TailGate/TrunkLid Open Ind in cluster



3. Normal Open SW



  - SW Off: Full Lock(Full Close state)



  - SW On: ^Full Lock";
BA_ "Version" SG_ 3221225472 WakeUp_Warn_DrvDrSwSta "19.08.00";
BA_ "NetworkRequestHoldingTime" SG_ 3221225472 WakeUp_Warn_DrvDrSwSta 5000;
BA_ "NetworkRequest" SG_ 3221225472 WakeUp_Warn_DrvDrSwSta 0;
BA_ "UserSigValidity" SG_ 3221225472 WakeUp_Warn_DrvDrSwSta 0;
BA_ "GenSigStartValue" SG_ 3221225472 WakeUp_Warn_DrvDrSwSta 2;
BA_ "GenSigSendType" SG_ 3221225472 WakeUp_Warn_DrvDrSwSta 4;
BA_ "Version" SG_ 3221225472 ODS_Crc1Val "18.11.08";
BA_ "UserSigValidity" SG_ 3221225472 ODS_Crc1Val 3;
BA_ "GenSigStartValue" SG_ 3221225472 ODS_Crc1Val 65535;
BA_ "Description" SG_ 3221225472 ODS_Crc1Val "The data area for CRC calculation is based on the data length (DLC) of the message DB.

The CRC shall be calculated over the entire data block (excluding the CRC bytes) including the user data, alive counter and Data ID

 

- CRC Polynomial (0x1021) , In";
BA_ "Version" SG_ 3221225472 ODS_AlvCnt1Val "18.11.08";
BA_ "UserSigValidity" SG_ 3221225472 ODS_AlvCnt1Val 3;
BA_ "Description" SG_ 3221225472 ODS_AlvCnt1Val "For the first transmission request for a data element the counter shall be initialized with 0 and shall be incremented by 1 for every subsequent send request. 

When the counter reaches the maximum value(0xFF), then it shall restart with 0 for the next s";
BA_ "Version" SG_ 3221225472 ODS_IdVal "17.12.02";
BA_ "UserSigValidity" SG_ 3221225472 ODS_IdVal 3;
BA_ "Description" SG_ 3221225472 ODS_IdVal "Information of Vehicle seat ID as defined by customer.



�� Initial Value ��(0x0) ���� (���� �ý��� ��� �� ���Ƿ� 0x0�� ���)

: Initial(Start) Value : Current Value";
BA_ "Version" SG_ 3221225472 ODS_OccClassSta "17.12.02";
BA_ "UserSigValidity" SG_ 3221225472 ODS_OccClassSta 3;
BA_ "GenSigStartValue" SG_ 3221225472 ODS_OccClassSta 4;
BA_ "Description" SG_ 3221225472 ODS_OccClassSta "Signal Value Table : reference with ODS Communiction instruction";
BA_ "Version" SG_ 3221225472 ODS_DiagSta "17.12.02";
BA_ "UserSigValidity" SG_ 3221225472 ODS_DiagSta 3;
BA_ "Description" SG_ 3221225472 ODS_DiagSta "CR_WCS_Errstat signal describes PODS-G & BOSE system error that is diagnosed by itself. Each Type set Diagnostic Status explains 3 kinds of fault.

[PODS-G]

Bit 1 : If ODS Have some errors, ODS set the bit, sends the ALR Defect signal to ACU and notifie";
BA_ "Version" SG_ 3221225472 ODS_SBRClassSta "19.05.02";
BA_ "UserSigValidity" SG_ 3221225472 ODS_SBRClassSta 3;
BA_ "Description" SG_ 3221225472 ODS_SBRClassSta "Refer to Signal Value table";
BA_ "Version" SG_ 3221225472 ICU_Crc11Val "18.11.08";
BA_ "UserSigValidity" SG_ 3221225472 ICU_Crc11Val 0;
BA_ "GenSigStartValue" SG_ 3221225472 ICU_Crc11Val 255;
BA_ "GenSigSendType" SG_ 3221225472 ICU_Crc11Val 4;
BA_ "Description" SG_ 3221225472 ICU_Crc11Val "The data area for CRC calculation is based on the data length (DLC) of the message DB.

The CRC shall be calculated over the entire data block (excluding the CRC bytes) including the user data, alive counter and Data ID 

 

- CRC Polynomial (0x1D) , Ini";
BA_ "Version" SG_ 3221225472 Bat_dischrg "18.03.05";
BA_ "UserSigValidity" SG_ 3221225472 Bat_dischrg 3;
BA_ "GenSigSendType" SG_ 3221225472 Bat_dischrg 4;
BA_ "Description" SG_ 3221225472 Bat_dischrg "Battery discharge notification flag";
BA_ "Version" SG_ 3221225472 ICU_AlvCnt11Val "18.11.08";
BA_ "UserSigValidity" SG_ 3221225472 ICU_AlvCnt11Val 0;
BA_ "GenSigSendType" SG_ 3221225472 ICU_AlvCnt11Val 4;
BA_ "Description" SG_ 3221225472 ICU_AlvCnt11Val "For the first transmission request for a data element the counter shall be initialized with 0 and shall be incremented by 1

for every subsequent send request. When the counter reaches the maximum value(0xE), then it shall restart with 0 for the next sen";
BA_ "Version" SG_ 3221225472 Batt_SoCWarningValue "17.12.00";
BA_ "UserSigValidity" SG_ 3221225472 Batt_SoCWarningValue 0;
BA_ "GenSigStartValue" SG_ 3221225472 Batt_SoCWarningValue 255;
BA_ "GenSigSendType" SG_ 3221225472 Batt_SoCWarningValue 4;
BA_ "Description" SG_ 3221225472 Batt_SoCWarningValue "This signal is Battery SOC from battery sensor.";
BA_ "Version" SG_ 3221225472 Batt_SoCAlertValue "17.12.00";
BA_ "UserSigValidity" SG_ 3221225472 Batt_SoCAlertValue 0;
BA_ "GenSigStartValue" SG_ 3221225472 Batt_SoCAlertValue 255;
BA_ "GenSigSendType" SG_ 3221225472 Batt_SoCAlertValue 4;
BA_ "Description" SG_ 3221225472 Batt_SoCAlertValue "This signal is Battery SOC from battery sensor.";
BA_ "Version" SG_ 3221225472 C_StrgWhlHeatingOpt "18.12.02";
BA_ "UserSigValidity" SG_ 3221225472 C_StrgWhlHeatingOpt 3;
BA_ "GenSigSendType" SG_ 3221225472 C_StrgWhlHeatingOpt 4;
BA_ "Description" SG_ 3221225472 C_StrgWhlHeatingOpt "Steering wheel heating option signal";
BA_ "Version" SG_ 3221225472 BCM_Crc2Val "18.11.08";
BA_ "UserSigValidity" SG_ 3221225472 BCM_Crc2Val 0;
BA_ "GenSigStartValue" SG_ 3221225472 BCM_Crc2Val 255;
BA_ "GenSigSendType" SG_ 3221225472 BCM_Crc2Val 4;
BA_ "Description" SG_ 3221225472 BCM_Crc2Val "The data area for CRC calculation is based on the data length (DLC) of the message DB.

The CRC shall be calculated over the entire data block (excluding the CRC bytes) including the user data, alive counter and Data ID 

 

- CRC Polynomial (0x1D) , Ini";
BA_ "Version" SG_ 3221225472 BCM_AlvCnt2Val "18.11.08";
BA_ "UserSigValidity" SG_ 3221225472 BCM_AlvCnt2Val 0;
BA_ "GenSigSendType" SG_ 3221225472 BCM_AlvCnt2Val 4;
BA_ "Description" SG_ 3221225472 BCM_AlvCnt2Val "For the first transmission request for a data element the counter shall be initialized with 0 and shall be incremented by 1

for every subsequent send request. When the counter reaches the maximum value(0xE), then it shall restart with 0 for the next sen";
BA_ "Version" SG_ 3221225472 BAlarm_BglrAlrmCurrentSta "17.12.00";
BA_ "NetworkRequestHoldingTime" SG_ 3221225472 BAlarm_BglrAlrmCurrentSta 5000;
BA_ "NetworkRequest" SG_ 3221225472 BAlarm_BglrAlrmCurrentSta 0;
BA_ "UserSigValidity" SG_ 3221225472 BAlarm_BglrAlrmCurrentSta 0;
BA_ "GenSigSendType" SG_ 3221225472 BAlarm_BglrAlrmCurrentSta 4;
BA_ "Version" SG_ 3221225472 BAlarm_BglrAlrmSta "17.12.00";
BA_ "NetworkRequestHoldingTime" SG_ 3221225472 BAlarm_BglrAlrmSta 5000;
BA_ "NetworkRequest" SG_ 3221225472 BAlarm_BglrAlrmSta 0;
BA_ "UserSigValidity" SG_ 3221225472 BAlarm_BglrAlrmSta 0;
BA_ "GenSigSendType" SG_ 3221225472 BAlarm_BglrAlrmSta 4;
BA_ "Version" SG_ 3221225472 BAlarm_PncAlrmSta "17.12.00";
BA_ "NetworkRequestHoldingTime" SG_ 3221225472 BAlarm_PncAlrmSta 5000;
BA_ "NetworkRequest" SG_ 3221225472 BAlarm_PncAlrmSta 0;
BA_ "UserSigValidity" SG_ 3221225472 BAlarm_PncAlrmSta 0;
BA_ "GenSigSendType" SG_ 3221225472 BAlarm_PncAlrmSta 4;
BA_ "Description" SG_ 3221225472 BAlarm_PncAlrmSta "-For TeleCranking Panic Function

-This signal send to IBOX";
BA_ "Version" SG_ 3221225472 BAlarm_BrglrHrnRlySta "17.12.00";
BA_ "NetworkRequestHoldingTime" SG_ 3221225472 BAlarm_BrglrHrnRlySta 5000;
BA_ "NetworkRequest" SG_ 3221225472 BAlarm_BrglrHrnRlySta 0;
BA_ "UserSigValidity" SG_ 3221225472 BAlarm_BrglrHrnRlySta 0;
BA_ "GenSigSendType" SG_ 3221225472 BAlarm_BrglrHrnRlySta 4;
BA_ "Version" SG_ 3221225472 BCM_AccInSta "17.12.00";
BA_ "NetworkRequestHoldingTime" SG_ 3221225472 BCM_AccInSta 5000;
BA_ "NetworkRequest" SG_ 3221225472 BCM_AccInSta 0;
BA_ "UserSigValidity" SG_ 3221225472 BCM_AccInSta 0;
BA_ "GenSigSendType" SG_ 3221225472 BCM_AccInSta 4;
BA_ "Version" SG_ 3221225472 BCM_Ign1InSta "17.12.00";
BA_ "NetworkRequestHoldingTime" SG_ 3221225472 BCM_Ign1InSta 5000;
BA_ "NetworkRequest" SG_ 3221225472 BCM_Ign1InSta 0;
BA_ "UserSigValidity" SG_ 3221225472 BCM_Ign1InSta 0;
BA_ "GenSigSendType" SG_ 3221225472 BCM_Ign1InSta 4;
BA_ "Version" SG_ 3221225472 BCM_Ign2InSta "17.12.00";
BA_ "NetworkRequestHoldingTime" SG_ 3221225472 BCM_Ign2InSta 5000;
BA_ "NetworkRequest" SG_ 3221225472 BCM_Ign2InSta 0;
BA_ "UserSigValidity" SG_ 3221225472 BCM_Ign2InSta 0;
BA_ "GenSigSendType" SG_ 3221225472 BCM_Ign2InSta 4;
BA_ "Version" SG_ 3221225472 BCM_IgnSwSta "17.12.00";
BA_ "NetworkRequestHoldingTime" SG_ 3221225472 BCM_IgnSwSta 5000;
BA_ "NetworkRequest" SG_ 3221225472 BCM_IgnSwSta 0;
BA_ "UserSigValidity" SG_ 3221225472 BCM_IgnSwSta 0;
BA_ "GenSigSendType" SG_ 3221225472 BCM_IgnSwSta 4;
BA_ "Version" SG_ 3221225472 CCP_MDPS_RESP1_Byte0 "18.08.01";
BA_ "NetworkRequestHoldingTime" SG_ 3221225472 CCP_MDPS_RESP1_Byte0 5000;
BA_ "NetworkRequest" SG_ 3221225472 CCP_MDPS_RESP1_Byte0 0;
BA_ "UserSigValidity" SG_ 3221225472 CCP_MDPS_RESP1_Byte0 0;
BA_ "GenSigSendType" SG_ 3221225472 CCP_MDPS_RESP1_Byte0 2;
BA_ "UsrSigPurpose" SG_ 3221225472 CCP_MDPS_RESP1_Byte0 6;
BA_ "Version" SG_ 3221225472 CCP_MDPS_RESP1_Byte2 "18.08.01";
BA_ "NetworkRequestHoldingTime" SG_ 3221225472 CCP_MDPS_RESP1_Byte2 5000;
BA_ "NetworkRequest" SG_ 3221225472 CCP_MDPS_RESP1_Byte2 0;
BA_ "UserSigValidity" SG_ 3221225472 CCP_MDPS_RESP1_Byte2 0;
BA_ "GenSigSendType" SG_ 3221225472 CCP_MDPS_RESP1_Byte2 2;
BA_ "UsrSigPurpose" SG_ 3221225472 CCP_MDPS_RESP1_Byte2 6;
BA_ "Version" SG_ 3221225472 CCP_MDPS_RESP1_Byte3 "18.08.01";
BA_ "NetworkRequestHoldingTime" SG_ 3221225472 CCP_MDPS_RESP1_Byte3 5000;
BA_ "NetworkRequest" SG_ 3221225472 CCP_MDPS_RESP1_Byte3 0;
BA_ "UserSigValidity" SG_ 3221225472 CCP_MDPS_RESP1_Byte3 0;
BA_ "GenSigSendType" SG_ 3221225472 CCP_MDPS_RESP1_Byte3 2;
BA_ "UsrSigPurpose" SG_ 3221225472 CCP_MDPS_RESP1_Byte3 6;
BA_ "Version" SG_ 3221225472 CCP_MDPS_RESP1_Byte4 "18.08.01";
BA_ "NetworkRequestHoldingTime" SG_ 3221225472 CCP_MDPS_RESP1_Byte4 5000;
BA_ "NetworkRequest" SG_ 3221225472 CCP_MDPS_RESP1_Byte4 0;
BA_ "UserSigValidity" SG_ 3221225472 CCP_MDPS_RESP1_Byte4 0;
BA_ "GenSigSendType" SG_ 3221225472 CCP_MDPS_RESP1_Byte4 2;
BA_ "UsrSigPurpose" SG_ 3221225472 CCP_MDPS_RESP1_Byte4 6;
BA_ "Version" SG_ 3221225472 CCP_MDPS_RESP1_Byte5 "18.08.01";
BA_ "NetworkRequestHoldingTime" SG_ 3221225472 CCP_MDPS_RESP1_Byte5 5000;
BA_ "NetworkRequest" SG_ 3221225472 CCP_MDPS_RESP1_Byte5 0;
BA_ "UserSigValidity" SG_ 3221225472 CCP_MDPS_RESP1_Byte5 0;
BA_ "GenSigSendType" SG_ 3221225472 CCP_MDPS_RESP1_Byte5 2;
BA_ "UsrSigPurpose" SG_ 3221225472 CCP_MDPS_RESP1_Byte5 6;
BA_ "Version" SG_ 3221225472 CCP_MDPS_RESP1_Byte6 "18.08.01";
BA_ "NetworkRequestHoldingTime" SG_ 3221225472 CCP_MDPS_RESP1_Byte6 5000;
BA_ "NetworkRequest" SG_ 3221225472 CCP_MDPS_RESP1_Byte6 0;
BA_ "UserSigValidity" SG_ 3221225472 CCP_MDPS_RESP1_Byte6 0;
BA_ "GenSigSendType" SG_ 3221225472 CCP_MDPS_RESP1_Byte6 2;
BA_ "UsrSigPurpose" SG_ 3221225472 CCP_MDPS_RESP1_Byte6 6;
BA_ "Version" SG_ 3221225472 CCP_MDPS_RESP1_Byte7 "18.08.01";
BA_ "NetworkRequestHoldingTime" SG_ 3221225472 CCP_MDPS_RESP1_Byte7 5000;
BA_ "NetworkRequest" SG_ 3221225472 CCP_MDPS_RESP1_Byte7 0;
BA_ "UserSigValidity" SG_ 3221225472 CCP_MDPS_RESP1_Byte7 0;
BA_ "GenSigSendType" SG_ 3221225472 CCP_MDPS_RESP1_Byte7 2;
BA_ "UsrSigPurpose" SG_ 3221225472 CCP_MDPS_RESP1_Byte7 6;
BA_ "Version" SG_ 3221225472 CCP_MDPS_RESP1_Byte1 "18.08.01";
BA_ "NetworkRequestHoldingTime" SG_ 3221225472 CCP_MDPS_RESP1_Byte1 5000;
BA_ "NetworkRequest" SG_ 3221225472 CCP_MDPS_RESP1_Byte1 0;
BA_ "UserSigValidity" SG_ 3221225472 CCP_MDPS_RESP1_Byte1 0;
BA_ "GenSigSendType" SG_ 3221225472 CCP_MDPS_RESP1_Byte1 2;
BA_ "UsrSigPurpose" SG_ 3221225472 CCP_MDPS_RESP1_Byte1 6;
BA_ "Version" SG_ 3221225472 CCP_MDPS_REQ5_Byte0 "18.08.01";
BA_ "NetworkRequestHoldingTime" SG_ 3221225472 CCP_MDPS_REQ5_Byte0 5000;
BA_ "NetworkRequest" SG_ 3221225472 CCP_MDPS_REQ5_Byte0 0;
BA_ "UserSigValidity" SG_ 3221225472 CCP_MDPS_REQ5_Byte0 0;
BA_ "GenSigSendType" SG_ 3221225472 CCP_MDPS_REQ5_Byte0 2;
BA_ "UsrSigPurpose" SG_ 3221225472 CCP_MDPS_REQ5_Byte0 6;
BA_ "Version" SG_ 3221225472 CCP_MDPS_REQ5_Byte2 "18.08.01";
BA_ "NetworkRequestHoldingTime" SG_ 3221225472 CCP_MDPS_REQ5_Byte2 5000;
BA_ "NetworkRequest" SG_ 3221225472 CCP_MDPS_REQ5_Byte2 0;
BA_ "UserSigValidity" SG_ 3221225472 CCP_MDPS_REQ5_Byte2 0;
BA_ "GenSigSendType" SG_ 3221225472 CCP_MDPS_REQ5_Byte2 2;
BA_ "UsrSigPurpose" SG_ 3221225472 CCP_MDPS_REQ5_Byte2 6;
BA_ "Version" SG_ 3221225472 CCP_MDPS_REQ5_Byte3 "18.08.01";
BA_ "NetworkRequestHoldingTime" SG_ 3221225472 CCP_MDPS_REQ5_Byte3 5000;
BA_ "NetworkRequest" SG_ 3221225472 CCP_MDPS_REQ5_Byte3 0;
BA_ "UserSigValidity" SG_ 3221225472 CCP_MDPS_REQ5_Byte3 0;
BA_ "GenSigSendType" SG_ 3221225472 CCP_MDPS_REQ5_Byte3 2;
BA_ "UsrSigPurpose" SG_ 3221225472 CCP_MDPS_REQ5_Byte3 6;
BA_ "Version" SG_ 3221225472 CCP_MDPS_REQ5_Byte4 "18.08.01";
BA_ "NetworkRequestHoldingTime" SG_ 3221225472 CCP_MDPS_REQ5_Byte4 5000;
BA_ "NetworkRequest" SG_ 3221225472 CCP_MDPS_REQ5_Byte4 0;
BA_ "UserSigValidity" SG_ 3221225472 CCP_MDPS_REQ5_Byte4 0;
BA_ "GenSigSendType" SG_ 3221225472 CCP_MDPS_REQ5_Byte4 2;
BA_ "UsrSigPurpose" SG_ 3221225472 CCP_MDPS_REQ5_Byte4 6;
BA_ "Version" SG_ 3221225472 CCP_MDPS_REQ5_Byte5 "18.08.01";
BA_ "NetworkRequestHoldingTime" SG_ 3221225472 CCP_MDPS_REQ5_Byte5 5000;
BA_ "NetworkRequest" SG_ 3221225472 CCP_MDPS_REQ5_Byte5 0;
BA_ "UserSigValidity" SG_ 3221225472 CCP_MDPS_REQ5_Byte5 0;
BA_ "GenSigSendType" SG_ 3221225472 CCP_MDPS_REQ5_Byte5 2;
BA_ "UsrSigPurpose" SG_ 3221225472 CCP_MDPS_REQ5_Byte5 6;
BA_ "Version" SG_ 3221225472 CCP_MDPS_REQ5_Byte6 "18.08.01";
BA_ "NetworkRequestHoldingTime" SG_ 3221225472 CCP_MDPS_REQ5_Byte6 5000;
BA_ "NetworkRequest" SG_ 3221225472 CCP_MDPS_REQ5_Byte6 0;
BA_ "UserSigValidity" SG_ 3221225472 CCP_MDPS_REQ5_Byte6 0;
BA_ "GenSigSendType" SG_ 3221225472 CCP_MDPS_REQ5_Byte6 2;
BA_ "UsrSigPurpose" SG_ 3221225472 CCP_MDPS_REQ5_Byte6 6;
BA_ "Version" SG_ 3221225472 CCP_MDPS_REQ5_Byte7 "18.08.01";
BA_ "NetworkRequestHoldingTime" SG_ 3221225472 CCP_MDPS_REQ5_Byte7 5000;
BA_ "NetworkRequest" SG_ 3221225472 CCP_MDPS_REQ5_Byte7 0;
BA_ "UserSigValidity" SG_ 3221225472 CCP_MDPS_REQ5_Byte7 0;
BA_ "GenSigSendType" SG_ 3221225472 CCP_MDPS_REQ5_Byte7 2;
BA_ "UsrSigPurpose" SG_ 3221225472 CCP_MDPS_REQ5_Byte7 6;
BA_ "Version" SG_ 3221225472 CCP_MDPS_REQ5_Byte1 "18.08.01";
BA_ "NetworkRequestHoldingTime" SG_ 3221225472 CCP_MDPS_REQ5_Byte1 5000;
BA_ "NetworkRequest" SG_ 3221225472 CCP_MDPS_REQ5_Byte1 0;
BA_ "UserSigValidity" SG_ 3221225472 CCP_MDPS_REQ5_Byte1 0;
BA_ "GenSigSendType" SG_ 3221225472 CCP_MDPS_REQ5_Byte1 2;
BA_ "UsrSigPurpose" SG_ 3221225472 CCP_MDPS_REQ5_Byte1 6;
BA_ "Version" SG_ 3221225472 CCP_MDPS_RESP3_Byte0 "18.08.01";
BA_ "NetworkRequestHoldingTime" SG_ 3221225472 CCP_MDPS_RESP3_Byte0 5000;
BA_ "NetworkRequest" SG_ 3221225472 CCP_MDPS_RESP3_Byte0 0;
BA_ "UserSigValidity" SG_ 3221225472 CCP_MDPS_RESP3_Byte0 0;
BA_ "GenSigSendType" SG_ 3221225472 CCP_MDPS_RESP3_Byte0 2;
BA_ "UsrSigPurpose" SG_ 3221225472 CCP_MDPS_RESP3_Byte0 6;
BA_ "Version" SG_ 3221225472 CCP_MDPS_RESP3_Byte2 "18.08.01";
BA_ "NetworkRequestHoldingTime" SG_ 3221225472 CCP_MDPS_RESP3_Byte2 5000;
BA_ "NetworkRequest" SG_ 3221225472 CCP_MDPS_RESP3_Byte2 0;
BA_ "UserSigValidity" SG_ 3221225472 CCP_MDPS_RESP3_Byte2 0;
BA_ "GenSigSendType" SG_ 3221225472 CCP_MDPS_RESP3_Byte2 2;
BA_ "UsrSigPurpose" SG_ 3221225472 CCP_MDPS_RESP3_Byte2 6;
BA_ "Version" SG_ 3221225472 CCP_MDPS_RESP3_Byte3 "18.08.01";
BA_ "NetworkRequestHoldingTime" SG_ 3221225472 CCP_MDPS_RESP3_Byte3 5000;
BA_ "NetworkRequest" SG_ 3221225472 CCP_MDPS_RESP3_Byte3 0;
BA_ "UserSigValidity" SG_ 3221225472 CCP_MDPS_RESP3_Byte3 0;
BA_ "GenSigSendType" SG_ 3221225472 CCP_MDPS_RESP3_Byte3 2;
BA_ "UsrSigPurpose" SG_ 3221225472 CCP_MDPS_RESP3_Byte3 6;
BA_ "Version" SG_ 3221225472 CCP_MDPS_RESP3_Byte4 "18.08.01";
BA_ "NetworkRequestHoldingTime" SG_ 3221225472 CCP_MDPS_RESP3_Byte4 5000;
BA_ "NetworkRequest" SG_ 3221225472 CCP_MDPS_RESP3_Byte4 0;
BA_ "UserSigValidity" SG_ 3221225472 CCP_MDPS_RESP3_Byte4 0;
BA_ "GenSigSendType" SG_ 3221225472 CCP_MDPS_RESP3_Byte4 2;
BA_ "UsrSigPurpose" SG_ 3221225472 CCP_MDPS_RESP3_Byte4 6;
BA_ "Version" SG_ 3221225472 CCP_MDPS_RESP3_Byte5 "18.08.01";
BA_ "NetworkRequestHoldingTime" SG_ 3221225472 CCP_MDPS_RESP3_Byte5 5000;
BA_ "NetworkRequest" SG_ 3221225472 CCP_MDPS_RESP3_Byte5 0;
BA_ "UserSigValidity" SG_ 3221225472 CCP_MDPS_RESP3_Byte5 0;
BA_ "GenSigSendType" SG_ 3221225472 CCP_MDPS_RESP3_Byte5 2;
BA_ "UsrSigPurpose" SG_ 3221225472 CCP_MDPS_RESP3_Byte5 6;
BA_ "Version" SG_ 3221225472 CCP_MDPS_RESP3_Byte6 "18.08.01";
BA_ "NetworkRequestHoldingTime" SG_ 3221225472 CCP_MDPS_RESP3_Byte6 5000;
BA_ "NetworkRequest" SG_ 3221225472 CCP_MDPS_RESP3_Byte6 0;
BA_ "UserSigValidity" SG_ 3221225472 CCP_MDPS_RESP3_Byte6 0;
BA_ "GenSigSendType" SG_ 3221225472 CCP_MDPS_RESP3_Byte6 2;
BA_ "UsrSigPurpose" SG_ 3221225472 CCP_MDPS_RESP3_Byte6 6;
BA_ "Version" SG_ 3221225472 CCP_MDPS_RESP3_Byte7 "18.08.01";
BA_ "NetworkRequestHoldingTime" SG_ 3221225472 CCP_MDPS_RESP3_Byte7 5000;
BA_ "NetworkRequest" SG_ 3221225472 CCP_MDPS_RESP3_Byte7 0;
BA_ "UserSigValidity" SG_ 3221225472 CCP_MDPS_RESP3_Byte7 0;
BA_ "GenSigSendType" SG_ 3221225472 CCP_MDPS_RESP3_Byte7 2;
BA_ "UsrSigPurpose" SG_ 3221225472 CCP_MDPS_RESP3_Byte7 6;
BA_ "Version" SG_ 3221225472 CCP_MDPS_RESP3_Byte1 "18.08.01";
BA_ "NetworkRequestHoldingTime" SG_ 3221225472 CCP_MDPS_RESP3_Byte1 5000;
BA_ "NetworkRequest" SG_ 3221225472 CCP_MDPS_RESP3_Byte1 0;
BA_ "UserSigValidity" SG_ 3221225472 CCP_MDPS_RESP3_Byte1 0;
BA_ "GenSigSendType" SG_ 3221225472 CCP_MDPS_RESP3_Byte1 2;
BA_ "UsrSigPurpose" SG_ 3221225472 CCP_MDPS_RESP3_Byte1 6;
BA_ "Version" SG_ 3221225472 CCP_MDPS_RESP2_Byte0 "18.08.01";
BA_ "NetworkRequestHoldingTime" SG_ 3221225472 CCP_MDPS_RESP2_Byte0 5000;
BA_ "NetworkRequest" SG_ 3221225472 CCP_MDPS_RESP2_Byte0 0;
BA_ "UserSigValidity" SG_ 3221225472 CCP_MDPS_RESP2_Byte0 0;
BA_ "GenSigSendType" SG_ 3221225472 CCP_MDPS_RESP2_Byte0 2;
BA_ "UsrSigPurpose" SG_ 3221225472 CCP_MDPS_RESP2_Byte0 6;
BA_ "Version" SG_ 3221225472 CCP_MDPS_RESP2_Byte2 "18.08.01";
BA_ "NetworkRequestHoldingTime" SG_ 3221225472 CCP_MDPS_RESP2_Byte2 5000;
BA_ "NetworkRequest" SG_ 3221225472 CCP_MDPS_RESP2_Byte2 0;
BA_ "UserSigValidity" SG_ 3221225472 CCP_MDPS_RESP2_Byte2 0;
BA_ "GenSigSendType" SG_ 3221225472 CCP_MDPS_RESP2_Byte2 2;
BA_ "UsrSigPurpose" SG_ 3221225472 CCP_MDPS_RESP2_Byte2 6;
BA_ "Version" SG_ 3221225472 CCP_MDPS_RESP2_Byte3 "18.08.01";
BA_ "NetworkRequestHoldingTime" SG_ 3221225472 CCP_MDPS_RESP2_Byte3 5000;
BA_ "NetworkRequest" SG_ 3221225472 CCP_MDPS_RESP2_Byte3 0;
BA_ "UserSigValidity" SG_ 3221225472 CCP_MDPS_RESP2_Byte3 0;
BA_ "GenSigSendType" SG_ 3221225472 CCP_MDPS_RESP2_Byte3 2;
BA_ "UsrSigPurpose" SG_ 3221225472 CCP_MDPS_RESP2_Byte3 6;
BA_ "Version" SG_ 3221225472 CCP_MDPS_RESP2_Byte4 "18.08.01";
BA_ "NetworkRequestHoldingTime" SG_ 3221225472 CCP_MDPS_RESP2_Byte4 5000;
BA_ "NetworkRequest" SG_ 3221225472 CCP_MDPS_RESP2_Byte4 0;
BA_ "UserSigValidity" SG_ 3221225472 CCP_MDPS_RESP2_Byte4 0;
BA_ "GenSigSendType" SG_ 3221225472 CCP_MDPS_RESP2_Byte4 2;
BA_ "UsrSigPurpose" SG_ 3221225472 CCP_MDPS_RESP2_Byte4 6;
BA_ "Version" SG_ 3221225472 CCP_MDPS_RESP2_Byte5 "18.08.01";
BA_ "NetworkRequestHoldingTime" SG_ 3221225472 CCP_MDPS_RESP2_Byte5 5000;
BA_ "NetworkRequest" SG_ 3221225472 CCP_MDPS_RESP2_Byte5 0;
BA_ "UserSigValidity" SG_ 3221225472 CCP_MDPS_RESP2_Byte5 0;
BA_ "GenSigSendType" SG_ 3221225472 CCP_MDPS_RESP2_Byte5 2;
BA_ "UsrSigPurpose" SG_ 3221225472 CCP_MDPS_RESP2_Byte5 6;
BA_ "Version" SG_ 3221225472 CCP_MDPS_RESP2_Byte6 "18.08.01";
BA_ "NetworkRequestHoldingTime" SG_ 3221225472 CCP_MDPS_RESP2_Byte6 5000;
BA_ "NetworkRequest" SG_ 3221225472 CCP_MDPS_RESP2_Byte6 0;
BA_ "UserSigValidity" SG_ 3221225472 CCP_MDPS_RESP2_Byte6 0;
BA_ "GenSigSendType" SG_ 3221225472 CCP_MDPS_RESP2_Byte6 2;
BA_ "UsrSigPurpose" SG_ 3221225472 CCP_MDPS_RESP2_Byte6 6;
BA_ "Version" SG_ 3221225472 CCP_MDPS_RESP2_Byte7 "18.08.01";
BA_ "NetworkRequestHoldingTime" SG_ 3221225472 CCP_MDPS_RESP2_Byte7 5000;
BA_ "NetworkRequest" SG_ 3221225472 CCP_MDPS_RESP2_Byte7 0;
BA_ "UserSigValidity" SG_ 3221225472 CCP_MDPS_RESP2_Byte7 0;
BA_ "GenSigSendType" SG_ 3221225472 CCP_MDPS_RESP2_Byte7 2;
BA_ "UsrSigPurpose" SG_ 3221225472 CCP_MDPS_RESP2_Byte7 6;
BA_ "Version" SG_ 3221225472 CCP_MDPS_RESP2_Byte1 "18.08.01";
BA_ "NetworkRequestHoldingTime" SG_ 3221225472 CCP_MDPS_RESP2_Byte1 5000;
BA_ "NetworkRequest" SG_ 3221225472 CCP_MDPS_RESP2_Byte1 0;
BA_ "UserSigValidity" SG_ 3221225472 CCP_MDPS_RESP2_Byte1 0;
BA_ "GenSigSendType" SG_ 3221225472 CCP_MDPS_RESP2_Byte1 2;
BA_ "UsrSigPurpose" SG_ 3221225472 CCP_MDPS_RESP2_Byte1 6;
BA_ "Version" SG_ 3221225472 CCP_MDPS_REQ2_Byte0 "18.08.01";
BA_ "NetworkRequestHoldingTime" SG_ 3221225472 CCP_MDPS_REQ2_Byte0 5000;
BA_ "NetworkRequest" SG_ 3221225472 CCP_MDPS_REQ2_Byte0 0;
BA_ "UserSigValidity" SG_ 3221225472 CCP_MDPS_REQ2_Byte0 0;
BA_ "GenSigSendType" SG_ 3221225472 CCP_MDPS_REQ2_Byte0 2;
BA_ "UsrSigPurpose" SG_ 3221225472 CCP_MDPS_REQ2_Byte0 6;
BA_ "Version" SG_ 3221225472 CCP_MDPS_REQ2_Byte2 "18.08.01";
BA_ "NetworkRequestHoldingTime" SG_ 3221225472 CCP_MDPS_REQ2_Byte2 5000;
BA_ "NetworkRequest" SG_ 3221225472 CCP_MDPS_REQ2_Byte2 0;
BA_ "UserSigValidity" SG_ 3221225472 CCP_MDPS_REQ2_Byte2 0;
BA_ "GenSigSendType" SG_ 3221225472 CCP_MDPS_REQ2_Byte2 2;
BA_ "UsrSigPurpose" SG_ 3221225472 CCP_MDPS_REQ2_Byte2 6;
BA_ "Version" SG_ 3221225472 CCP_MDPS_REQ2_Byte3 "18.08.01";
BA_ "NetworkRequestHoldingTime" SG_ 3221225472 CCP_MDPS_REQ2_Byte3 5000;
BA_ "NetworkRequest" SG_ 3221225472 CCP_MDPS_REQ2_Byte3 0;
BA_ "UserSigValidity" SG_ 3221225472 CCP_MDPS_REQ2_Byte3 0;
BA_ "GenSigSendType" SG_ 3221225472 CCP_MDPS_REQ2_Byte3 2;
BA_ "UsrSigPurpose" SG_ 3221225472 CCP_MDPS_REQ2_Byte3 6;
BA_ "Version" SG_ 3221225472 CCP_MDPS_REQ2_Byte4 "18.08.01";
BA_ "NetworkRequestHoldingTime" SG_ 3221225472 CCP_MDPS_REQ2_Byte4 5000;
BA_ "NetworkRequest" SG_ 3221225472 CCP_MDPS_REQ2_Byte4 0;
BA_ "UserSigValidity" SG_ 3221225472 CCP_MDPS_REQ2_Byte4 0;
BA_ "GenSigSendType" SG_ 3221225472 CCP_MDPS_REQ2_Byte4 2;
BA_ "UsrSigPurpose" SG_ 3221225472 CCP_MDPS_REQ2_Byte4 6;
BA_ "Version" SG_ 3221225472 CCP_MDPS_REQ2_Byte5 "18.08.01";
BA_ "NetworkRequestHoldingTime" SG_ 3221225472 CCP_MDPS_REQ2_Byte5 5000;
BA_ "NetworkRequest" SG_ 3221225472 CCP_MDPS_REQ2_Byte5 0;
BA_ "UserSigValidity" SG_ 3221225472 CCP_MDPS_REQ2_Byte5 0;
BA_ "GenSigSendType" SG_ 3221225472 CCP_MDPS_REQ2_Byte5 2;
BA_ "UsrSigPurpose" SG_ 3221225472 CCP_MDPS_REQ2_Byte5 6;
BA_ "Version" SG_ 3221225472 CCP_MDPS_REQ2_Byte6 "18.08.01";
BA_ "NetworkRequestHoldingTime" SG_ 3221225472 CCP_MDPS_REQ2_Byte6 5000;
BA_ "NetworkRequest" SG_ 3221225472 CCP_MDPS_REQ2_Byte6 0;
BA_ "UserSigValidity" SG_ 3221225472 CCP_MDPS_REQ2_Byte6 0;
BA_ "GenSigSendType" SG_ 3221225472 CCP_MDPS_REQ2_Byte6 2;
BA_ "UsrSigPurpose" SG_ 3221225472 CCP_MDPS_REQ2_Byte6 6;
BA_ "Version" SG_ 3221225472 CCP_MDPS_REQ2_Byte7 "18.08.01";
BA_ "NetworkRequestHoldingTime" SG_ 3221225472 CCP_MDPS_REQ2_Byte7 5000;
BA_ "NetworkRequest" SG_ 3221225472 CCP_MDPS_REQ2_Byte7 0;
BA_ "UserSigValidity" SG_ 3221225472 CCP_MDPS_REQ2_Byte7 0;
BA_ "GenSigSendType" SG_ 3221225472 CCP_MDPS_REQ2_Byte7 2;
BA_ "UsrSigPurpose" SG_ 3221225472 CCP_MDPS_REQ2_Byte7 6;
BA_ "Version" SG_ 3221225472 CCP_MDPS_REQ2_Byte1 "18.08.01";
BA_ "NetworkRequestHoldingTime" SG_ 3221225472 CCP_MDPS_REQ2_Byte1 5000;
BA_ "NetworkRequest" SG_ 3221225472 CCP_MDPS_REQ2_Byte1 0;
BA_ "UserSigValidity" SG_ 3221225472 CCP_MDPS_REQ2_Byte1 0;
BA_ "GenSigSendType" SG_ 3221225472 CCP_MDPS_REQ2_Byte1 2;
BA_ "UsrSigPurpose" SG_ 3221225472 CCP_MDPS_REQ2_Byte1 6;
BA_ "Version" SG_ 3221225472 CCP_MDPS_REQ1_Byte0 "18.08.01";
BA_ "NetworkRequestHoldingTime" SG_ 3221225472 CCP_MDPS_REQ1_Byte0 5000;
BA_ "NetworkRequest" SG_ 3221225472 CCP_MDPS_REQ1_Byte0 0;
BA_ "UserSigValidity" SG_ 3221225472 CCP_MDPS_REQ1_Byte0 0;
BA_ "GenSigSendType" SG_ 3221225472 CCP_MDPS_REQ1_Byte0 2;
BA_ "UsrSigPurpose" SG_ 3221225472 CCP_MDPS_REQ1_Byte0 6;
BA_ "Version" SG_ 3221225472 CCP_MDPS_REQ1_Byte2 "18.08.01";
BA_ "NetworkRequestHoldingTime" SG_ 3221225472 CCP_MDPS_REQ1_Byte2 5000;
BA_ "NetworkRequest" SG_ 3221225472 CCP_MDPS_REQ1_Byte2 0;
BA_ "UserSigValidity" SG_ 3221225472 CCP_MDPS_REQ1_Byte2 0;
BA_ "GenSigSendType" SG_ 3221225472 CCP_MDPS_REQ1_Byte2 2;
BA_ "UsrSigPurpose" SG_ 3221225472 CCP_MDPS_REQ1_Byte2 6;
BA_ "Version" SG_ 3221225472 CCP_MDPS_REQ1_Byte3 "18.08.01";
BA_ "NetworkRequestHoldingTime" SG_ 3221225472 CCP_MDPS_REQ1_Byte3 5000;
BA_ "NetworkRequest" SG_ 3221225472 CCP_MDPS_REQ1_Byte3 0;
BA_ "UserSigValidity" SG_ 3221225472 CCP_MDPS_REQ1_Byte3 0;
BA_ "GenSigSendType" SG_ 3221225472 CCP_MDPS_REQ1_Byte3 2;
BA_ "UsrSigPurpose" SG_ 3221225472 CCP_MDPS_REQ1_Byte3 6;
BA_ "Version" SG_ 3221225472 CCP_MDPS_REQ1_Byte4 "18.08.01";
BA_ "NetworkRequestHoldingTime" SG_ 3221225472 CCP_MDPS_REQ1_Byte4 5000;
BA_ "NetworkRequest" SG_ 3221225472 CCP_MDPS_REQ1_Byte4 0;
BA_ "UserSigValidity" SG_ 3221225472 CCP_MDPS_REQ1_Byte4 0;
BA_ "GenSigSendType" SG_ 3221225472 CCP_MDPS_REQ1_Byte4 2;
BA_ "UsrSigPurpose" SG_ 3221225472 CCP_MDPS_REQ1_Byte4 6;
BA_ "Version" SG_ 3221225472 CCP_MDPS_REQ1_Byte5 "18.08.01";
BA_ "NetworkRequestHoldingTime" SG_ 3221225472 CCP_MDPS_REQ1_Byte5 5000;
BA_ "NetworkRequest" SG_ 3221225472 CCP_MDPS_REQ1_Byte5 0;
BA_ "UserSigValidity" SG_ 3221225472 CCP_MDPS_REQ1_Byte5 0;
BA_ "GenSigSendType" SG_ 3221225472 CCP_MDPS_REQ1_Byte5 2;
BA_ "UsrSigPurpose" SG_ 3221225472 CCP_MDPS_REQ1_Byte5 6;
BA_ "Version" SG_ 3221225472 CCP_MDPS_REQ1_Byte6 "18.08.01";
BA_ "NetworkRequestHoldingTime" SG_ 3221225472 CCP_MDPS_REQ1_Byte6 5000;
BA_ "NetworkRequest" SG_ 3221225472 CCP_MDPS_REQ1_Byte6 0;
BA_ "UserSigValidity" SG_ 3221225472 CCP_MDPS_REQ1_Byte6 0;
BA_ "GenSigSendType" SG_ 3221225472 CCP_MDPS_REQ1_Byte6 2;
BA_ "UsrSigPurpose" SG_ 3221225472 CCP_MDPS_REQ1_Byte6 6;
BA_ "Version" SG_ 3221225472 CCP_MDPS_REQ1_Byte7 "18.08.01";
BA_ "NetworkRequestHoldingTime" SG_ 3221225472 CCP_MDPS_REQ1_Byte7 5000;
BA_ "NetworkRequest" SG_ 3221225472 CCP_MDPS_REQ1_Byte7 0;
BA_ "UserSigValidity" SG_ 3221225472 CCP_MDPS_REQ1_Byte7 0;
BA_ "GenSigSendType" SG_ 3221225472 CCP_MDPS_REQ1_Byte7 2;
BA_ "UsrSigPurpose" SG_ 3221225472 CCP_MDPS_REQ1_Byte7 6;
BA_ "Version" SG_ 3221225472 CCP_MDPS_REQ1_Byte1 "18.08.01";
BA_ "NetworkRequestHoldingTime" SG_ 3221225472 CCP_MDPS_REQ1_Byte1 5000;
BA_ "NetworkRequest" SG_ 3221225472 CCP_MDPS_REQ1_Byte1 0;
BA_ "UserSigValidity" SG_ 3221225472 CCP_MDPS_REQ1_Byte1 0;
BA_ "GenSigSendType" SG_ 3221225472 CCP_MDPS_REQ1_Byte1 2;
BA_ "UsrSigPurpose" SG_ 3221225472 CCP_MDPS_REQ1_Byte1 6;
BA_ "Version" SG_ 3221225472 CCP_MDPS_REQ4_Byte0 "18.08.01";
BA_ "NetworkRequestHoldingTime" SG_ 3221225472 CCP_MDPS_REQ4_Byte0 5000;
BA_ "NetworkRequest" SG_ 3221225472 CCP_MDPS_REQ4_Byte0 0;
BA_ "UserSigValidity" SG_ 3221225472 CCP_MDPS_REQ4_Byte0 0;
BA_ "GenSigSendType" SG_ 3221225472 CCP_MDPS_REQ4_Byte0 2;
BA_ "UsrSigPurpose" SG_ 3221225472 CCP_MDPS_REQ4_Byte0 6;
BA_ "Version" SG_ 3221225472 CCP_MDPS_REQ4_Byte2 "18.08.01";
BA_ "NetworkRequestHoldingTime" SG_ 3221225472 CCP_MDPS_REQ4_Byte2 5000;
BA_ "NetworkRequest" SG_ 3221225472 CCP_MDPS_REQ4_Byte2 0;
BA_ "UserSigValidity" SG_ 3221225472 CCP_MDPS_REQ4_Byte2 0;
BA_ "GenSigSendType" SG_ 3221225472 CCP_MDPS_REQ4_Byte2 2;
BA_ "UsrSigPurpose" SG_ 3221225472 CCP_MDPS_REQ4_Byte2 6;
BA_ "Version" SG_ 3221225472 CCP_MDPS_REQ4_Byte3 "18.08.01";
BA_ "NetworkRequestHoldingTime" SG_ 3221225472 CCP_MDPS_REQ4_Byte3 5000;
BA_ "NetworkRequest" SG_ 3221225472 CCP_MDPS_REQ4_Byte3 0;
BA_ "UserSigValidity" SG_ 3221225472 CCP_MDPS_REQ4_Byte3 0;
BA_ "GenSigSendType" SG_ 3221225472 CCP_MDPS_REQ4_Byte3 2;
BA_ "UsrSigPurpose" SG_ 3221225472 CCP_MDPS_REQ4_Byte3 6;
BA_ "Version" SG_ 3221225472 CCP_MDPS_REQ4_Byte4 "18.08.01";
BA_ "NetworkRequestHoldingTime" SG_ 3221225472 CCP_MDPS_REQ4_Byte4 5000;
BA_ "NetworkRequest" SG_ 3221225472 CCP_MDPS_REQ4_Byte4 0;
BA_ "UserSigValidity" SG_ 3221225472 CCP_MDPS_REQ4_Byte4 0;
BA_ "GenSigSendType" SG_ 3221225472 CCP_MDPS_REQ4_Byte4 2;
BA_ "UsrSigPurpose" SG_ 3221225472 CCP_MDPS_REQ4_Byte4 6;
BA_ "Version" SG_ 3221225472 CCP_MDPS_REQ4_Byte5 "18.08.01";
BA_ "NetworkRequestHoldingTime" SG_ 3221225472 CCP_MDPS_REQ4_Byte5 5000;
BA_ "NetworkRequest" SG_ 3221225472 CCP_MDPS_REQ4_Byte5 0;
BA_ "UserSigValidity" SG_ 3221225472 CCP_MDPS_REQ4_Byte5 0;
BA_ "GenSigSendType" SG_ 3221225472 CCP_MDPS_REQ4_Byte5 2;
BA_ "UsrSigPurpose" SG_ 3221225472 CCP_MDPS_REQ4_Byte5 6;
BA_ "Version" SG_ 3221225472 CCP_MDPS_REQ4_Byte6 "18.08.01";
BA_ "NetworkRequestHoldingTime" SG_ 3221225472 CCP_MDPS_REQ4_Byte6 5000;
BA_ "NetworkRequest" SG_ 3221225472 CCP_MDPS_REQ4_Byte6 0;
BA_ "UserSigValidity" SG_ 3221225472 CCP_MDPS_REQ4_Byte6 0;
BA_ "GenSigSendType" SG_ 3221225472 CCP_MDPS_REQ4_Byte6 2;
BA_ "UsrSigPurpose" SG_ 3221225472 CCP_MDPS_REQ4_Byte6 6;
BA_ "Version" SG_ 3221225472 CCP_MDPS_REQ4_Byte7 "18.08.01";
BA_ "NetworkRequestHoldingTime" SG_ 3221225472 CCP_MDPS_REQ4_Byte7 5000;
BA_ "NetworkRequest" SG_ 3221225472 CCP_MDPS_REQ4_Byte7 0;
BA_ "UserSigValidity" SG_ 3221225472 CCP_MDPS_REQ4_Byte7 0;
BA_ "GenSigSendType" SG_ 3221225472 CCP_MDPS_REQ4_Byte7 2;
BA_ "UsrSigPurpose" SG_ 3221225472 CCP_MDPS_REQ4_Byte7 6;
BA_ "Version" SG_ 3221225472 CCP_MDPS_REQ4_Byte1 "18.08.01";
BA_ "NetworkRequestHoldingTime" SG_ 3221225472 CCP_MDPS_REQ4_Byte1 5000;
BA_ "NetworkRequest" SG_ 3221225472 CCP_MDPS_REQ4_Byte1 0;
BA_ "UserSigValidity" SG_ 3221225472 CCP_MDPS_REQ4_Byte1 0;
BA_ "GenSigSendType" SG_ 3221225472 CCP_MDPS_REQ4_Byte1 2;
BA_ "UsrSigPurpose" SG_ 3221225472 CCP_MDPS_REQ4_Byte1 6;
BA_ "Version" SG_ 3221225472 CCP_MDPS_REQ3_Byte0 "18.08.01";
BA_ "NetworkRequestHoldingTime" SG_ 3221225472 CCP_MDPS_REQ3_Byte0 5000;
BA_ "NetworkRequest" SG_ 3221225472 CCP_MDPS_REQ3_Byte0 0;
BA_ "UserSigValidity" SG_ 3221225472 CCP_MDPS_REQ3_Byte0 0;
BA_ "GenSigSendType" SG_ 3221225472 CCP_MDPS_REQ3_Byte0 2;
BA_ "UsrSigPurpose" SG_ 3221225472 CCP_MDPS_REQ3_Byte0 6;
BA_ "Version" SG_ 3221225472 CCP_MDPS_REQ3_Byte2 "18.08.01";
BA_ "NetworkRequestHoldingTime" SG_ 3221225472 CCP_MDPS_REQ3_Byte2 5000;
BA_ "NetworkRequest" SG_ 3221225472 CCP_MDPS_REQ3_Byte2 0;
BA_ "UserSigValidity" SG_ 3221225472 CCP_MDPS_REQ3_Byte2 0;
BA_ "GenSigSendType" SG_ 3221225472 CCP_MDPS_REQ3_Byte2 2;
BA_ "UsrSigPurpose" SG_ 3221225472 CCP_MDPS_REQ3_Byte2 6;
BA_ "Version" SG_ 3221225472 CCP_MDPS_REQ3_Byte3 "18.08.01";
BA_ "NetworkRequestHoldingTime" SG_ 3221225472 CCP_MDPS_REQ3_Byte3 5000;
BA_ "NetworkRequest" SG_ 3221225472 CCP_MDPS_REQ3_Byte3 0;
BA_ "UserSigValidity" SG_ 3221225472 CCP_MDPS_REQ3_Byte3 0;
BA_ "GenSigSendType" SG_ 3221225472 CCP_MDPS_REQ3_Byte3 2;
BA_ "UsrSigPurpose" SG_ 3221225472 CCP_MDPS_REQ3_Byte3 6;
BA_ "Version" SG_ 3221225472 CCP_MDPS_REQ3_Byte4 "18.08.01";
BA_ "NetworkRequestHoldingTime" SG_ 3221225472 CCP_MDPS_REQ3_Byte4 5000;
BA_ "NetworkRequest" SG_ 3221225472 CCP_MDPS_REQ3_Byte4 0;
BA_ "UserSigValidity" SG_ 3221225472 CCP_MDPS_REQ3_Byte4 0;
BA_ "GenSigSendType" SG_ 3221225472 CCP_MDPS_REQ3_Byte4 2;
BA_ "UsrSigPurpose" SG_ 3221225472 CCP_MDPS_REQ3_Byte4 6;
BA_ "Version" SG_ 3221225472 CCP_MDPS_REQ3_Byte5 "18.08.01";
BA_ "NetworkRequestHoldingTime" SG_ 3221225472 CCP_MDPS_REQ3_Byte5 5000;
BA_ "NetworkRequest" SG_ 3221225472 CCP_MDPS_REQ3_Byte5 0;
BA_ "UserSigValidity" SG_ 3221225472 CCP_MDPS_REQ3_Byte5 0;
BA_ "GenSigSendType" SG_ 3221225472 CCP_MDPS_REQ3_Byte5 2;
BA_ "UsrSigPurpose" SG_ 3221225472 CCP_MDPS_REQ3_Byte5 6;
BA_ "Version" SG_ 3221225472 CCP_MDPS_REQ3_Byte6 "18.08.01";
BA_ "NetworkRequestHoldingTime" SG_ 3221225472 CCP_MDPS_REQ3_Byte6 5000;
BA_ "NetworkRequest" SG_ 3221225472 CCP_MDPS_REQ3_Byte6 0;
BA_ "UserSigValidity" SG_ 3221225472 CCP_MDPS_REQ3_Byte6 0;
BA_ "GenSigSendType" SG_ 3221225472 CCP_MDPS_REQ3_Byte6 2;
BA_ "UsrSigPurpose" SG_ 3221225472 CCP_MDPS_REQ3_Byte6 6;
BA_ "Version" SG_ 3221225472 CCP_MDPS_REQ3_Byte7 "18.08.01";
BA_ "NetworkRequestHoldingTime" SG_ 3221225472 CCP_MDPS_REQ3_Byte7 5000;
BA_ "NetworkRequest" SG_ 3221225472 CCP_MDPS_REQ3_Byte7 0;
BA_ "UserSigValidity" SG_ 3221225472 CCP_MDPS_REQ3_Byte7 0;
BA_ "GenSigSendType" SG_ 3221225472 CCP_MDPS_REQ3_Byte7 2;
BA_ "UsrSigPurpose" SG_ 3221225472 CCP_MDPS_REQ3_Byte7 6;
BA_ "Version" SG_ 3221225472 CCP_MDPS_REQ3_Byte1 "18.08.01";
BA_ "NetworkRequestHoldingTime" SG_ 3221225472 CCP_MDPS_REQ3_Byte1 5000;
BA_ "NetworkRequest" SG_ 3221225472 CCP_MDPS_REQ3_Byte1 0;
BA_ "UserSigValidity" SG_ 3221225472 CCP_MDPS_REQ3_Byte1 0;
BA_ "GenSigSendType" SG_ 3221225472 CCP_MDPS_REQ3_Byte1 2;
BA_ "UsrSigPurpose" SG_ 3221225472 CCP_MDPS_REQ3_Byte1 6;
BA_ "Version" SG_ 3221225472 CF_AVN_CluWelcomeSnd "18.04.02";
BA_ "UserSigValidity" SG_ 3221225472 CF_AVN_CluWelcomeSnd 3;
BA_ "GenSigSendType" SG_ 3221225472 CF_AVN_CluWelcomeSnd 4;
BA_ "Version" SG_ 3221225472 CF_AVN_CluTransmissionDisp "18.04.02";
BA_ "UserSigValidity" SG_ 3221225472 CF_AVN_CluTransmissionDisp 3;
BA_ "GenSigSendType" SG_ 3221225472 CF_AVN_CluTransmissionDisp 4;
BA_ "Version" SG_ 3221225472 CF_AVN_CluWiperLight "18.04.02";
BA_ "UserSigValidity" SG_ 3221225472 CF_AVN_CluWiperLight 3;
BA_ "GenSigSendType" SG_ 3221225472 CF_AVN_CluWiperLight 4;
BA_ "Version" SG_ 3221225472 CF_AVN_CluRoadInfoGuide "18.04.02";
BA_ "UserSigValidity" SG_ 3221225472 CF_AVN_CluRoadInfoGuide 3;
BA_ "GenSigSendType" SG_ 3221225472 CF_AVN_CluRoadInfoGuide 4;
BA_ "Version" SG_ 3221225472 CF_AVN_CluUserSettingPeriod "19.01.10";
BA_ "UserSigValidity" SG_ 3221225472 CF_AVN_CluUserSettingPeriod 3;
BA_ "GenSigStartValue" SG_ 3221225472 CF_AVN_CluUserSettingPeriod 127;
BA_ "GenSigSendType" SG_ 3221225472 CF_AVN_CluUserSettingPeriod 4;
BA_ "Version" SG_ 3221225472 CF_AVN_CluAutoInitFuelEconomy "18.04.02";
BA_ "UserSigValidity" SG_ 3221225472 CF_AVN_CluAutoInitFuelEconomy 3;
BA_ "GenSigSendType" SG_ 3221225472 CF_AVN_CluAutoInitFuelEconomy 4;
BA_ "Version" SG_ 3221225472 CF_AVN_CluSubspeedOdometerDisp "18.09.04";
BA_ "UserSigValidity" SG_ 3221225472 CF_AVN_CluSubspeedOdometerDisp 3;
BA_ "GenSigSendType" SG_ 3221225472 CF_AVN_CluSubspeedOdometerDisp 4;
BA_ "Version" SG_ 3221225472 CF_AVN_CluFuelEconUnit_mi "18.09.04";
BA_ "UserSigValidity" SG_ 3221225472 CF_AVN_CluFuelEconUnit_mi 3;
BA_ "GenSigSendType" SG_ 3221225472 CF_AVN_CluFuelEconUnit_mi 4;
BA_ "Version" SG_ 3221225472 CF_AVN_CluFuelEconUnit_km "18.09.04";
BA_ "UserSigValidity" SG_ 3221225472 CF_AVN_CluFuelEconUnit_km 3;
BA_ "GenSigSendType" SG_ 3221225472 CF_AVN_CluFuelEconUnit_km 4;
BA_ "Version" SG_ 3221225472 CF_AVN_CluUserSettingDistance "19.01.10";
BA_ "UserSigValidity" SG_ 3221225472 CF_AVN_CluUserSettingDistance 3;
BA_ "GenSigStartValue" SG_ 3221225472 CF_AVN_CluUserSettingDistance 131071;
BA_ "GenSigSendType" SG_ 3221225472 CF_AVN_CluUserSettingDistance 4;
BA_ "Version" SG_ 3221225472 CF_AVN_CluVoiceVolume "18.04.02";
BA_ "UserSigValidity" SG_ 3221225472 CF_AVN_CluVoiceVolume 3;
BA_ "GenSigSendType" SG_ 3221225472 CF_AVN_CluVoiceVolume 4;
BA_ "Version" SG_ 3221225472 CF_AVN_EVReset "18.09.04";
BA_ "UserSigValidity" SG_ 3221225472 CF_AVN_EVReset 7;
BA_ "GenSigSendType" SG_ 3221225472 CF_AVN_EVReset 4;
BA_ "Version" SG_ 3221225472 CF_AVN_UnitReset "18.09.04";
BA_ "UserSigValidity" SG_ 3221225472 CF_AVN_UnitReset 3;
BA_ "GenSigSendType" SG_ 3221225472 CF_AVN_UnitReset 4;
BA_ "Version" SG_ 3221225472 CF_AVN_IcyRoadWarn "18.04.02";
BA_ "UserSigValidity" SG_ 3221225472 CF_AVN_IcyRoadWarn 3;
BA_ "GenSigSendType" SG_ 3221225472 CF_AVN_IcyRoadWarn 4;
BA_ "Version" SG_ 3221225472 CF_AVN_CluServiceReminderReset "18.04.02";
BA_ "UserSigValidity" SG_ 3221225472 CF_AVN_CluServiceReminderReset 3;
BA_ "GenSigSendType" SG_ 3221225472 CF_AVN_CluServiceReminderReset 4;
BA_ "Version" SG_ 3221225472 CF_AVN_CluUSMReset "17.11.00";
BA_ "UserSigValidity" SG_ 3221225472 CF_AVN_CluUSMReset 3;
BA_ "GenSigSendType" SG_ 3221225472 CF_AVN_CluUSMReset 4;
BA_ "Version" SG_ 3221225472 CF_AVN_CluServiceReminderSet "18.04.02";
BA_ "UserSigValidity" SG_ 3221225472 CF_AVN_CluServiceReminderSet 3;
BA_ "GenSigSendType" SG_ 3221225472 CF_AVN_CluServiceReminderSet 4;
BA_ "Version" SG_ 3221225472 EPB_Crc1Val "18.11.08";
BA_ "RoutingFactor" SG_ 3221225472 EPB_Crc1Val 3;
BA_ "UserSigValidity" SG_ 3221225472 EPB_Crc1Val 3;
BA_ "GenSigStartValue" SG_ 3221225472 EPB_Crc1Val 65535;
BA_ "Description" SG_ 3221225472 EPB_Crc1Val "The data area for CRC calculation is based on the data length (DLC) of the message DB.

The CRC shall be calculated over the entire data block (excluding the CRC bytes) including the user data, alive counter and Data ID

 

- CRC Polynomial (0x1021) , In";
BA_ "Version" SG_ 3221225472 EPB_AlvCnt1Val "18.11.08";
BA_ "RoutingFactor" SG_ 3221225472 EPB_AlvCnt1Val 3;
BA_ "UserSigValidity" SG_ 3221225472 EPB_AlvCnt1Val 3;
BA_ "Description" SG_ 3221225472 EPB_AlvCnt1Val "For the first transmission request for a data element the counter shall be initialized with 0 and shall be incremented by 1 for every subsequent send request. 

When the counter reaches the maximum value(0xFF), then it shall restart with 0 for the next s";
BA_ "Version" SG_ 3221225472 EPB_LmpStaDis "17.12.00";
BA_ "RoutingFactor" SG_ 3221225472 EPB_LmpStaDis 3;
BA_ "UserSigValidity" SG_ 3221225472 EPB_LmpStaDis 3;
BA_ "Description" SG_ 3221225472 EPB_LmpStaDis "This signal indicates status lamp request from EPB to lamp control unit.

- The lamp shall be turned on during initialization. The initialization lasts for 3 seconds after IG-key on.

- If a lamp control unit can not get this signal via CAN due to any er";
BA_ "Version" SG_ 3221225472 EPB_FlrLmpStaDis "17.12.00";
BA_ "RoutingFactor" SG_ 3221225472 EPB_FlrLmpStaDis 3;
BA_ "UserSigValidity" SG_ 3221225472 EPB_FlrLmpStaDis 3;
BA_ "Description" SG_ 3221225472 EPB_FlrLmpStaDis "Information about the failure lamp request from EPB to lamp control unit.



EPB_F_LAMP(0H) - Yellow failure lamp status(Off)

EPB_F_LAMP(1H) - Yellow failure lamp status(On)

EPB_F_LAMP(2H) - Yellow failure lamp status(Blinking at 1 Hz)";
BA_ "Version" SG_ 3221225472 EPB_OutDataDis "19.06.03";
BA_ "RoutingFactor" SG_ 3221225472 EPB_OutDataDis 3;
BA_ "UserSigValidity" SG_ 3221225472 EPB_OutDataDis 3;
BA_ "Description" SG_ 3221225472 EPB_OutDataDis "An EPB can show its information message to driver on a cluster or a display module with this signal. �� 0x4 is for China";
BA_ "Version" SG_ 3221225472 EPB_AlrmReq "17.12.00";
BA_ "RoutingFactor" SG_ 3221225472 EPB_AlrmReq 3;
BA_ "UserSigValidity" SG_ 3221225472 EPB_AlrmReq 3;
BA_ "Description" SG_ 3221225472 EPB_AlrmReq "This signal indicates that an EPB requests cluster or tone controller to ring the alarm according to the status of an EPB.



Conversion [Condition]

0H : Normal operation

1H : EPB_CLU = 2 or 3

(send signals three time in a row & 1st signal should be s";
BA_ "Version" SG_ 3221225472 EPB_SwPosSta "17.12.00";
BA_ "RoutingFactor" SG_ 3221225472 EPB_SwPosSta 3;
BA_ "UserSigValidity" SG_ 3221225472 EPB_SwPosSta 3;
BA_ "Description" SG_ 3221225472 EPB_SwPosSta "Information about the EPB control switch state";
BA_ "Version" SG_ 3221225472 EPB_RrBrkLtActvReq "17.12.00";
BA_ "RoutingFactor" SG_ 3221225472 EPB_RrBrkLtActvReq 3;
BA_ "UserSigValidity" SG_ 3221225472 EPB_RrBrkLtActvReq 3;
BA_ "Description" SG_ 3221225472 EPB_RrBrkLtActvReq "If an EPB acts braking and the vehicle speed is higher than pre-defined condition then rear brake lamp shall be turned on. This signal requests ESC or brake lamp controller to turn on rear brake lamp.";
BA_ "Version" SG_ 3221225472 EPB_FrcErrSta "17.12.00";
BA_ "RoutingFactor" SG_ 3221225472 EPB_FrcErrSta 3;
BA_ "UserSigValidity" SG_ 3221225472 EPB_FrcErrSta 3;
BA_ "Description" SG_ 3221225472 EPB_FrcErrSta "Detail descriptions of error status of EPB force if EPB_FrcErrSta = 00H";
BA_ "Version" SG_ 3221225472 EPB_DynmBrkFrcReqSigSta "17.12.00";
BA_ "RoutingFactor" SG_ 3221225472 EPB_DynmBrkFrcReqSigSta 3;
BA_ "UserSigValidity" SG_ 3221225472 EPB_DynmBrkFrcReqSigSta 3;
BA_ "GenSigStartValue" SG_ 3221225472 EPB_DynmBrkFrcReqSigSta 1;
BA_ "Description" SG_ 3221225472 EPB_DynmBrkFrcReqSigSta "This signal indicates the validity of EPB_DynmBrkFrcReqSigSta (EPB request for ESP to activate Dynamic Brake Function) signal.";
BA_ "Version" SG_ 3221225472 EPB_FrcSta "17.12.00";
BA_ "RoutingFactor" SG_ 3221225472 EPB_FrcSta 3;
BA_ "UserSigValidity" SG_ 3221225472 EPB_FrcSta 3;
BA_ "Description" SG_ 3221225472 EPB_FrcSta "Information about the force status of the EPB";
BA_ "Version" SG_ 3221225472 EPB_FlSta "17.12.00";
BA_ "RoutingFactor" SG_ 3221225472 EPB_FlSta 3;
BA_ "UserSigValidity" SG_ 3221225472 EPB_FlSta 3;
BA_ "GenSigStartValue" SG_ 3221225472 EPB_FlSta 2;
BA_ "Description" SG_ 3221225472 EPB_FlSta "Information about availability of EPB. If this bit is set (EPB is not available), EPB motor control is not possible, e.g. by external AVH request.";
BA_ "Version" SG_ 3221225472 EPB_EscReqAckSta "17.12.00";
BA_ "RoutingFactor" SG_ 3221225472 EPB_EscReqAckSta 3;
BA_ "UserSigValidity" SG_ 3221225472 EPB_EscReqAckSta 3;
BA_ "Description" SG_ 3221225472 EPB_EscReqAckSta "Acknowledge signal for ESC request (e.g. AVH).



ESC sends request to release (1) or clamping (2) via signal REQ_EPB_ACT. The EPB acknowledges this request with EPB_EscReqAckSta = 1 within the time tESP_REQ_OK (value tbd) and performs according to the r";
BA_ "Version" SG_ 3221225472 EPB_DynmBrkFrcReq "17.12.00";
BA_ "RoutingFactor" SG_ 3221225472 EPB_DynmBrkFrcReq 3;
BA_ "UserSigValidity" SG_ 3221225472 EPB_DynmBrkFrcReq 3;
BA_ "Description" SG_ 3221225472 EPB_DynmBrkFrcReq "EPB dynamic Braking Request";
BA_ "Version" SG_ 3221225472 EPB_ActlFrcVal "17.12.00";
BA_ "RoutingFactor" SG_ 3221225472 EPB_ActlFrcVal 3;
BA_ "UserSigValidity" SG_ 3221225472 EPB_ActlFrcVal 3;
BA_ "GenSigStartValue" SG_ 3221225472 EPB_ActlFrcVal 1000;
BA_ "Description" SG_ 3221225472 EPB_ActlFrcVal "Actual braking force measured by EPB force sensor.";
BA_ "Version" SG_ 3221225472 EPB_DynmBrkFrcDclReq "17.12.00";
BA_ "RoutingFactor" SG_ 3221225472 EPB_DynmBrkFrcDclReq 3;
BA_ "UserSigValidity" SG_ 3221225472 EPB_DynmBrkFrcDclReq 3;
BA_ "Description" SG_ 3221225472 EPB_DynmBrkFrcDclReq "Requested deceleration for DBF. The ESC must consider this value if EPB_DynmBrkFrcReq is equal to 1.";
BA_ "Version" SG_ 3221225472 CCP_MDPS_RESP5_Byte0 "18.08.01";
BA_ "NetworkRequestHoldingTime" SG_ 3221225472 CCP_MDPS_RESP5_Byte0 5000;
BA_ "NetworkRequest" SG_ 3221225472 CCP_MDPS_RESP5_Byte0 0;
BA_ "UserSigValidity" SG_ 3221225472 CCP_MDPS_RESP5_Byte0 0;
BA_ "GenSigSendType" SG_ 3221225472 CCP_MDPS_RESP5_Byte0 2;
BA_ "UsrSigPurpose" SG_ 3221225472 CCP_MDPS_RESP5_Byte0 6;
BA_ "Version" SG_ 3221225472 CCP_MDPS_RESP5_Byte2 "18.08.01";
BA_ "NetworkRequestHoldingTime" SG_ 3221225472 CCP_MDPS_RESP5_Byte2 5000;
BA_ "NetworkRequest" SG_ 3221225472 CCP_MDPS_RESP5_Byte2 0;
BA_ "UserSigValidity" SG_ 3221225472 CCP_MDPS_RESP5_Byte2 0;
BA_ "GenSigSendType" SG_ 3221225472 CCP_MDPS_RESP5_Byte2 2;
BA_ "UsrSigPurpose" SG_ 3221225472 CCP_MDPS_RESP5_Byte2 6;
BA_ "Version" SG_ 3221225472 CCP_MDPS_RESP5_Byte3 "18.08.01";
BA_ "NetworkRequestHoldingTime" SG_ 3221225472 CCP_MDPS_RESP5_Byte3 5000;
BA_ "NetworkRequest" SG_ 3221225472 CCP_MDPS_RESP5_Byte3 0;
BA_ "UserSigValidity" SG_ 3221225472 CCP_MDPS_RESP5_Byte3 0;
BA_ "GenSigSendType" SG_ 3221225472 CCP_MDPS_RESP5_Byte3 2;
BA_ "UsrSigPurpose" SG_ 3221225472 CCP_MDPS_RESP5_Byte3 6;
BA_ "Version" SG_ 3221225472 CCP_MDPS_RESP5_Byte4 "18.08.01";
BA_ "NetworkRequestHoldingTime" SG_ 3221225472 CCP_MDPS_RESP5_Byte4 5000;
BA_ "NetworkRequest" SG_ 3221225472 CCP_MDPS_RESP5_Byte4 0;
BA_ "UserSigValidity" SG_ 3221225472 CCP_MDPS_RESP5_Byte4 0;
BA_ "GenSigSendType" SG_ 3221225472 CCP_MDPS_RESP5_Byte4 2;
BA_ "UsrSigPurpose" SG_ 3221225472 CCP_MDPS_RESP5_Byte4 6;
BA_ "Version" SG_ 3221225472 CCP_MDPS_RESP5_Byte5 "18.08.01";
BA_ "NetworkRequestHoldingTime" SG_ 3221225472 CCP_MDPS_RESP5_Byte5 5000;
BA_ "NetworkRequest" SG_ 3221225472 CCP_MDPS_RESP5_Byte5 0;
BA_ "UserSigValidity" SG_ 3221225472 CCP_MDPS_RESP5_Byte5 0;
BA_ "GenSigSendType" SG_ 3221225472 CCP_MDPS_RESP5_Byte5 2;
BA_ "UsrSigPurpose" SG_ 3221225472 CCP_MDPS_RESP5_Byte5 6;
BA_ "Version" SG_ 3221225472 CCP_MDPS_RESP5_Byte6 "18.08.01";
BA_ "NetworkRequestHoldingTime" SG_ 3221225472 CCP_MDPS_RESP5_Byte6 5000;
BA_ "NetworkRequest" SG_ 3221225472 CCP_MDPS_RESP5_Byte6 0;
BA_ "UserSigValidity" SG_ 3221225472 CCP_MDPS_RESP5_Byte6 0;
BA_ "GenSigSendType" SG_ 3221225472 CCP_MDPS_RESP5_Byte6 2;
BA_ "UsrSigPurpose" SG_ 3221225472 CCP_MDPS_RESP5_Byte6 6;
BA_ "Version" SG_ 3221225472 CCP_MDPS_RESP5_Byte7 "18.08.01";
BA_ "NetworkRequestHoldingTime" SG_ 3221225472 CCP_MDPS_RESP5_Byte7 5000;
BA_ "NetworkRequest" SG_ 3221225472 CCP_MDPS_RESP5_Byte7 0;
BA_ "UserSigValidity" SG_ 3221225472 CCP_MDPS_RESP5_Byte7 0;
BA_ "GenSigSendType" SG_ 3221225472 CCP_MDPS_RESP5_Byte7 2;
BA_ "UsrSigPurpose" SG_ 3221225472 CCP_MDPS_RESP5_Byte7 6;
BA_ "Version" SG_ 3221225472 CCP_MDPS_RESP5_Byte1 "18.08.01";
BA_ "NetworkRequestHoldingTime" SG_ 3221225472 CCP_MDPS_RESP5_Byte1 5000;
BA_ "NetworkRequest" SG_ 3221225472 CCP_MDPS_RESP5_Byte1 0;
BA_ "UserSigValidity" SG_ 3221225472 CCP_MDPS_RESP5_Byte1 0;
BA_ "GenSigSendType" SG_ 3221225472 CCP_MDPS_RESP5_Byte1 2;
BA_ "UsrSigPurpose" SG_ 3221225472 CCP_MDPS_RESP5_Byte1 6;
BA_ "Version" SG_ 3221225472 CCP_MDPS_RESP4_Byte0 "18.08.01";
BA_ "NetworkRequestHoldingTime" SG_ 3221225472 CCP_MDPS_RESP4_Byte0 5000;
BA_ "NetworkRequest" SG_ 3221225472 CCP_MDPS_RESP4_Byte0 0;
BA_ "UserSigValidity" SG_ 3221225472 CCP_MDPS_RESP4_Byte0 0;
BA_ "GenSigSendType" SG_ 3221225472 CCP_MDPS_RESP4_Byte0 2;
BA_ "UsrSigPurpose" SG_ 3221225472 CCP_MDPS_RESP4_Byte0 6;
BA_ "Version" SG_ 3221225472 CCP_MDPS_RESP4_Byte2 "18.08.01";
BA_ "NetworkRequestHoldingTime" SG_ 3221225472 CCP_MDPS_RESP4_Byte2 5000;
BA_ "NetworkRequest" SG_ 3221225472 CCP_MDPS_RESP4_Byte2 0;
BA_ "UserSigValidity" SG_ 3221225472 CCP_MDPS_RESP4_Byte2 0;
BA_ "GenSigSendType" SG_ 3221225472 CCP_MDPS_RESP4_Byte2 2;
BA_ "UsrSigPurpose" SG_ 3221225472 CCP_MDPS_RESP4_Byte2 6;
BA_ "Version" SG_ 3221225472 CCP_MDPS_RESP4_Byte3 "18.08.01";
BA_ "NetworkRequestHoldingTime" SG_ 3221225472 CCP_MDPS_RESP4_Byte3 5000;
BA_ "NetworkRequest" SG_ 3221225472 CCP_MDPS_RESP4_Byte3 0;
BA_ "UserSigValidity" SG_ 3221225472 CCP_MDPS_RESP4_Byte3 0;
BA_ "GenSigSendType" SG_ 3221225472 CCP_MDPS_RESP4_Byte3 2;
BA_ "UsrSigPurpose" SG_ 3221225472 CCP_MDPS_RESP4_Byte3 6;
BA_ "Version" SG_ 3221225472 CCP_MDPS_RESP4_Byte4 "18.08.01";
BA_ "NetworkRequestHoldingTime" SG_ 3221225472 CCP_MDPS_RESP4_Byte4 5000;
BA_ "NetworkRequest" SG_ 3221225472 CCP_MDPS_RESP4_Byte4 0;
BA_ "UserSigValidity" SG_ 3221225472 CCP_MDPS_RESP4_Byte4 0;
BA_ "GenSigSendType" SG_ 3221225472 CCP_MDPS_RESP4_Byte4 2;
BA_ "UsrSigPurpose" SG_ 3221225472 CCP_MDPS_RESP4_Byte4 6;
BA_ "Version" SG_ 3221225472 CCP_MDPS_RESP4_Byte5 "18.08.01";
BA_ "NetworkRequestHoldingTime" SG_ 3221225472 CCP_MDPS_RESP4_Byte5 5000;
BA_ "NetworkRequest" SG_ 3221225472 CCP_MDPS_RESP4_Byte5 0;
BA_ "UserSigValidity" SG_ 3221225472 CCP_MDPS_RESP4_Byte5 0;
BA_ "GenSigSendType" SG_ 3221225472 CCP_MDPS_RESP4_Byte5 2;
BA_ "UsrSigPurpose" SG_ 3221225472 CCP_MDPS_RESP4_Byte5 6;
BA_ "Version" SG_ 3221225472 CCP_MDPS_RESP4_Byte6 "18.08.01";
BA_ "NetworkRequestHoldingTime" SG_ 3221225472 CCP_MDPS_RESP4_Byte6 5000;
BA_ "NetworkRequest" SG_ 3221225472 CCP_MDPS_RESP4_Byte6 0;
BA_ "UserSigValidity" SG_ 3221225472 CCP_MDPS_RESP4_Byte6 0;
BA_ "GenSigSendType" SG_ 3221225472 CCP_MDPS_RESP4_Byte6 2;
BA_ "UsrSigPurpose" SG_ 3221225472 CCP_MDPS_RESP4_Byte6 6;
BA_ "Version" SG_ 3221225472 CCP_MDPS_RESP4_Byte7 "18.08.01";
BA_ "NetworkRequestHoldingTime" SG_ 3221225472 CCP_MDPS_RESP4_Byte7 5000;
BA_ "NetworkRequest" SG_ 3221225472 CCP_MDPS_RESP4_Byte7 0;
BA_ "UserSigValidity" SG_ 3221225472 CCP_MDPS_RESP4_Byte7 0;
BA_ "GenSigSendType" SG_ 3221225472 CCP_MDPS_RESP4_Byte7 2;
BA_ "UsrSigPurpose" SG_ 3221225472 CCP_MDPS_RESP4_Byte7 6;
BA_ "Version" SG_ 3221225472 CCP_MDPS_RESP4_Byte1 "18.08.01";
BA_ "NetworkRequestHoldingTime" SG_ 3221225472 CCP_MDPS_RESP4_Byte1 5000;
BA_ "NetworkRequest" SG_ 3221225472 CCP_MDPS_RESP4_Byte1 0;
BA_ "UserSigValidity" SG_ 3221225472 CCP_MDPS_RESP4_Byte1 0;
BA_ "GenSigSendType" SG_ 3221225472 CCP_MDPS_RESP4_Byte1 2;
BA_ "UsrSigPurpose" SG_ 3221225472 CCP_MDPS_RESP4_Byte1 6;
BA_ "Version" SG_ 3221225472 ICU_Crc1Val "18.11.08";
BA_ "UserSigValidity" SG_ 3221225472 ICU_Crc1Val 0;
BA_ "GenSigStartValue" SG_ 3221225472 ICU_Crc1Val 255;
BA_ "GenSigSendType" SG_ 3221225472 ICU_Crc1Val 4;
BA_ "Description" SG_ 3221225472 ICU_Crc1Val "The data area for CRC calculation is based on the data length (DLC) of the message DB.

The CRC shall be calculated over the entire data block (excluding the CRC bytes) including the user data, alive counter and Data ID 

 

- CRC Polynomial (0x1D) , Ini";
BA_ "Version" SG_ 3221225472 ICU_AlvCnt1Val "18.11.08";
BA_ "UserSigValidity" SG_ 3221225472 ICU_AlvCnt1Val 0;
BA_ "GenSigSendType" SG_ 3221225472 ICU_AlvCnt1Val 4;
BA_ "Description" SG_ 3221225472 ICU_AlvCnt1Val "For the first transmission request for a data element the counter shall be initialized with 0 and shall be incremented by 1

for every subsequent send request. When the counter reaches the maximum value(0xE), then it shall restart with 0 for the next sen";
BA_ "Version" SG_ 3221225472 DoorLock_DrvrDrUnLkPsvAcsReq "17.12.00";
BA_ "NetworkRequestHoldingTime" SG_ 3221225472 DoorLock_DrvrDrUnLkPsvAcsReq 5000;
BA_ "NetworkRequest" SG_ 3221225472 DoorLock_DrvrDrUnLkPsvAcsReq 0;
BA_ "UserSigValidity" SG_ 3221225472 DoorLock_DrvrDrUnLkPsvAcsReq 0;
BA_ "GenSigSendType" SG_ 3221225472 DoorLock_DrvrDrUnLkPsvAcsReq 4;
BA_ "Description" SG_ 3221225472 DoorLock_DrvrDrUnLkPsvAcsReq "Unlock only driver door by passive access (two turn unlock option)";
BA_ "Version" SG_ 3221225472 DoorLock_RmtKeyDrvrDrUnLkReq "17.12.00";
BA_ "NetworkRequestHoldingTime" SG_ 3221225472 DoorLock_RmtKeyDrvrDrUnLkReq 5000;
BA_ "NetworkRequest" SG_ 3221225472 DoorLock_RmtKeyDrvrDrUnLkReq 0;
BA_ "UserSigValidity" SG_ 3221225472 DoorLock_RmtKeyDrvrDrUnLkReq 0;
BA_ "GenSigSendType" SG_ 3221225472 DoorLock_RmtKeyDrvrDrUnLkReq 4;
BA_ "Description" SG_ 3221225472 DoorLock_RmtKeyDrvrDrUnLkReq "Unlock only driver door by RKE (two turn unlock option)";
BA_ "Version" SG_ 3221225472 SEG_V2_Offset "18.01.04";
BA_ "NetworkRequest" SG_ 3221225472 SEG_V2_Offset 0;
BA_ "UserSigValidity" SG_ 3221225472 SEG_V2_Offset 3;
BA_ "GenSigStartValue" SG_ 3221225472 SEG_V2_Offset 8191;
BA_ "GenSigSendType" SG_ 3221225472 SEG_V2_Offset 4;
BA_ "Description" SG_ 3221225472 SEG_V2_Offset "[Default Value]

0x1FFF";
BA_ "Version" SG_ 3221225472 SEG_V2_PathIndex "18.01.04";
BA_ "NetworkRequest" SG_ 3221225472 SEG_V2_PathIndex 0;
BA_ "UserSigValidity" SG_ 3221225472 SEG_V2_PathIndex 3;
BA_ "GenSigSendType" SG_ 3221225472 SEG_V2_PathIndex 4;
BA_ "Description" SG_ 3221225472 SEG_V2_PathIndex "[Default Value]

0x0";
BA_ "Version" SG_ 3221225472 SEG_V2_CyclicCounter "18.01.04";
BA_ "NetworkRequest" SG_ 3221225472 SEG_V2_CyclicCounter 0;
BA_ "UserSigValidity" SG_ 3221225472 SEG_V2_CyclicCounter 3;
BA_ "GenSigSendType" SG_ 3221225472 SEG_V2_CyclicCounter 4;
BA_ "Description" SG_ 3221225472 SEG_V2_CyclicCounter "[Default Value]

0x0";
BA_ "Version" SG_ 3221225472 SEG_V2_Retransmission "18.01.04";
BA_ "NetworkRequest" SG_ 3221225472 SEG_V2_Retransmission 0;
BA_ "UserSigValidity" SG_ 3221225472 SEG_V2_Retransmission 3;
BA_ "GenSigSendType" SG_ 3221225472 SEG_V2_Retransmission 4;
BA_ "Description" SG_ 3221225472 SEG_V2_Retransmission "[Default Value]

0x0";
BA_ "Version" SG_ 3221225472 SEG_V2_CalculatedRoute "18.01.04";
BA_ "NetworkRequest" SG_ 3221225472 SEG_V2_CalculatedRoute 0;
BA_ "UserSigValidity" SG_ 3221225472 SEG_V2_CalculatedRoute 3;
BA_ "GenSigStartValue" SG_ 3221225472 SEG_V2_CalculatedRoute 3;
BA_ "GenSigSendType" SG_ 3221225472 SEG_V2_CalculatedRoute 4;
BA_ "Description" SG_ 3221225472 SEG_V2_CalculatedRoute "[Default Value]

0x3";
BA_ "Version" SG_ 3221225472 SEG_V2_FuncRoadClass "18.01.04";
BA_ "NetworkRequest" SG_ 3221225472 SEG_V2_FuncRoadClass 0;
BA_ "UserSigValidity" SG_ 3221225472 SEG_V2_FuncRoadClass 3;
BA_ "GenSigStartValue" SG_ 3221225472 SEG_V2_FuncRoadClass 7;
BA_ "GenSigSendType" SG_ 3221225472 SEG_V2_FuncRoadClass 4;
BA_ "Description" SG_ 3221225472 SEG_V2_FuncRoadClass "[Default Vaule]

0x0";
BA_ "Version" SG_ 3221225472 SEG_V2_SpeedLimit "19.03.04";
BA_ "UserSigValidity" SG_ 3221225472 SEG_V2_SpeedLimit 3;
BA_ "GenSigStartValue" SG_ 3221225472 SEG_V2_SpeedLimit 31;
BA_ "GenSigSendType" SG_ 3221225472 SEG_V2_SpeedLimit 4;
BA_ "Version" SG_ 3221225472 SEG_V2_FormOfWay "18.01.04";
BA_ "NetworkRequest" SG_ 3221225472 SEG_V2_FormOfWay 0;
BA_ "UserSigValidity" SG_ 3221225472 SEG_V2_FormOfWay 3;
BA_ "GenSigStartValue" SG_ 3221225472 SEG_V2_FormOfWay 15;
BA_ "GenSigSendType" SG_ 3221225472 SEG_V2_FormOfWay 4;
BA_ "Description" SG_ 3221225472 SEG_V2_FormOfWay "[Default Value]

0x0";
BA_ "Version" SG_ 3221225472 SEG_V2_DirectionLanes "18.01.04";
BA_ "NetworkRequest" SG_ 3221225472 SEG_V2_DirectionLanes 0;
BA_ "UserSigValidity" SG_ 3221225472 SEG_V2_DirectionLanes 3;
BA_ "GenSigStartValue" SG_ 3221225472 SEG_V2_DirectionLanes 15;
BA_ "GenSigSendType" SG_ 3221225472 SEG_V2_DirectionLanes 4;
BA_ "Description" SG_ 3221225472 SEG_V2_DirectionLanes "[Default Value]

0x0";
BA_ "Version" SG_ 3221225472 SEG_V2_SpeedLimitUnder5 "18.01.04";
BA_ "NetworkRequest" SG_ 3221225472 SEG_V2_SpeedLimitUnder5 0;
BA_ "UserSigValidity" SG_ 3221225472 SEG_V2_SpeedLimitUnder5 3;
BA_ "GenSigStartValue" SG_ 3221225472 SEG_V2_SpeedLimitUnder5 7;
BA_ "GenSigSendType" SG_ 3221225472 SEG_V2_SpeedLimitUnder5 4;
BA_ "Description" SG_ 3221225472 SEG_V2_SpeedLimitUnder5 "[Default Value]



0x0";
BA_ "Version" SG_ 3221225472 RR_C_RDR_Crc1Val "18.11.08";
BA_ "RoutingFactor" SG_ 3221225472 RR_C_RDR_Crc1Val 3;
BA_ "UserSigValidity" SG_ 3221225472 RR_C_RDR_Crc1Val 3;
BA_ "GenSigStartValue" SG_ 3221225472 RR_C_RDR_Crc1Val 65535;
BA_ "Description" SG_ 3221225472 RR_C_RDR_Crc1Val "The data area for CRC calculation is based on the data length (DLC) of the message DB.

The CRC shall be calculated over the entire data block (excluding the CRC bytes) including the user data, alive counter and Data ID

 

- CRC Polynomial (0x1021) , In";
BA_ "Version" SG_ 3221225472 FR_C_RDR_RR_C_RDR_FCA_Plus_Sta "18.08.06";
BA_ "RoutingFactor" SG_ 3221225472 FR_C_RDR_RR_C_RDR_FCA_Plus_Sta 3;
BA_ "UserSigValidity" SG_ 3221225472 FR_C_RDR_RR_C_RDR_FCA_Plus_Sta 3;
BA_ "Description" SG_ 3221225472 FR_C_RDR_RR_C_RDR_FCA_Plus_Sta "�����淹�̴�/ �����淹�̴� ǻ��Ʈ���� �̿��Ͽ� FCA-Car/Ped/Cyc+ �ý��ۿ� �����ϴ� ���� ����/���� ���� ȸ�� �Ұ��� ���θ� �Ǵ���";
BA_ "Version" SG_ 3221225472 RR_C_RDR_AlvCnt1Val "18.11.08";
BA_ "RoutingFactor" SG_ 3221225472 RR_C_RDR_AlvCnt1Val 3;
BA_ "UserSigValidity" SG_ 3221225472 RR_C_RDR_AlvCnt1Val 3;
BA_ "Description" SG_ 3221225472 RR_C_RDR_AlvCnt1Val "For the first transmission request for a data element the counter shall be initialized with 0 and shall be incremented by 1 for every subsequent send request. 

When the counter reaches the maximum value(0xFF), then it shall restart with 0 for the next s";
BA_ "Version" SG_ 3221225472 RCCW_Sta "17.12.00";
BA_ "RoutingFactor" SG_ 3221225472 RCCW_Sta 3;
BA_ "UserSigValidity" SG_ 3221225472 RCCW_Sta 3;
BA_ "Description" SG_ 3221225472 RCCW_Sta "This signal indicates the Status of RCCW";
BA_ "Version" SG_ 3221225472 RCCW_OnOffEquipSt "17.12.00";
BA_ "RoutingFactor" SG_ 3221225472 RCCW_OnOffEquipSt 3;
BA_ "UserSigValidity" SG_ 3221225472 RCCW_OnOffEquipSt 3;
BA_ "Description" SG_ 3221225472 RCCW_OnOffEquipSt "This signal indicates the on/off status of RCCW";
BA_ "Version" SG_ 3221225472 RCCW_LftIndSta "18.10.09";
BA_ "RoutingFactor" SG_ 3221225472 RCCW_LftIndSta 3;
BA_ "UserSigValidity" SG_ 3221225472 RCCW_LftIndSta 3;
BA_ "Description" SG_ 3221225472 RCCW_LftIndSta "This signal Indicates RCCW Warning Indicator mode for Left side";
BA_ "Version" SG_ 3221225472 RCCW_RtIndSta "18.10.09";
BA_ "RoutingFactor" SG_ 3221225472 RCCW_RtIndSta 3;
BA_ "UserSigValidity" SG_ 3221225472 RCCW_RtIndSta 3;
BA_ "Description" SG_ 3221225472 RCCW_RtIndSta "This signal Indicates RCCW Warning Indicator mode for Right side";
BA_ "Version" SG_ 3221225472 RCCW_LftSndWrngSta "17.12.00";
BA_ "RoutingFactor" SG_ 3221225472 RCCW_LftSndWrngSta 3;
BA_ "UserSigValidity" SG_ 3221225472 RCCW_LftSndWrngSta 3;
BA_ "Description" SG_ 3221225472 RCCW_LftSndWrngSta "This signal indicates RCCW Sound Warning for Rear Left Speaker";
BA_ "Version" SG_ 3221225472 RCCW_RtSndWrngSta "17.12.00";
BA_ "RoutingFactor" SG_ 3221225472 RCCW_RtSndWrngSta 3;
BA_ "UserSigValidity" SG_ 3221225472 RCCW_RtSndWrngSta 3;
BA_ "Description" SG_ 3221225472 RCCW_RtSndWrngSta "This signal indicates RCCW Sound Warning for Rear Right Speaker";
BA_ "Version" SG_ 3221225472 RCCW_LftWrngIndBriLvlVal "17.12.00";
BA_ "RoutingFactor" SG_ 3221225472 RCCW_LftWrngIndBriLvlVal 3;
BA_ "UserSigValidity" SG_ 3221225472 RCCW_LftWrngIndBriLvlVal 3;
BA_ "Description" SG_ 3221225472 RCCW_LftWrngIndBriLvlVal "0x00~FF : Indicator Brightness level of RCCW";
BA_ "Version" SG_ 3221225472 RCCW_RtWrngIndBriLvlVal "17.12.00";
BA_ "RoutingFactor" SG_ 3221225472 RCCW_RtWrngIndBriLvlVal 3;
BA_ "UserSigValidity" SG_ 3221225472 RCCW_RtWrngIndBriLvlVal 3;
BA_ "Description" SG_ 3221225472 RCCW_RtWrngIndBriLvlVal "0x00~FF : Indicator Brightness level of RCCW";
BA_ "Version" SG_ 3221225472 RCCA_Deccel_Req "18.06.00";
BA_ "RoutingFactor" SG_ 3221225472 RCCA_Deccel_Req 3;
BA_ "UserSigValidity" SG_ 3221225472 RCCA_Deccel_Req 3;
BA_ "Description" SG_ 3221225472 RCCA_Deccel_Req "This value is defined the time to stop the vehicle.





(PH) = 0.04 * (Hex)g";
BA_ "Version" SG_ 3221225472 RCCA_BrkCmdSta "17.12.00";
BA_ "RoutingFactor" SG_ 3221225472 RCCA_BrkCmdSta 3;
BA_ "UserSigValidity" SG_ 3221225472 RCCA_BrkCmdSta 3;
BA_ "Description" SG_ 3221225472 RCCA_BrkCmdSta "RCCA Function Brake Command";
BA_ "Version" SG_ 3221225472 RCCA_LftWrngSta "18.12.06";
BA_ "RoutingFactor" SG_ 3221225472 RCCA_LftWrngSta 3;
BA_ "UserSigValidity" SG_ 3221225472 RCCA_LftWrngSta 3;
BA_ "Description" SG_ 3221225472 RCCA_LftWrngSta "This signal Indicates RCCA Warning state for HMI(Cluster)";
BA_ "Version" SG_ 3221225472 RCCA_RtWrngSta "18.12.06";
BA_ "RoutingFactor" SG_ 3221225472 RCCA_RtWrngSta 3;
BA_ "UserSigValidity" SG_ 3221225472 RCCA_RtWrngSta 3;
BA_ "Description" SG_ 3221225472 RCCA_RtWrngSta "This signal Indicates RCCA Warning state for HMI";
BA_ "Version" SG_ 3221225472 RCCA_FuncStat "17.12.00";
BA_ "RoutingFactor" SG_ 3221225472 RCCA_FuncStat 3;
BA_ "UserSigValidity" SG_ 3221225472 RCCA_FuncStat 3;
BA_ "Description" SG_ 3221225472 RCCA_FuncStat "ESC state";
BA_ "Version" SG_ 3221225472 RCCA_Sta "17.11.00";
BA_ "RoutingFactor" SG_ 3221225472 RCCA_Sta 3;
BA_ "UserSigValidity" SG_ 3221225472 RCCA_Sta 3;
BA_ "Description" SG_ 3221225472 RCCA_Sta "This signal indicates the Status of RCCA";
BA_ "Version" SG_ 3221225472 RCCA_OnOffEquipSt "19.02.05";
BA_ "RoutingFactor" SG_ 3221225472 RCCA_OnOffEquipSt 3;
BA_ "UserSigValidity" SG_ 3221225472 RCCA_OnOffEquipSt 3;
BA_ "Description" SG_ 3221225472 RCCA_OnOffEquipSt "This signal indicates the on/off status of RCCA";
BA_ "Version" SG_ 3221225472 SEA_Sta "17.11.00";
BA_ "RoutingFactor" SG_ 3221225472 SEA_Sta 3;
BA_ "UserSigValidity" SG_ 3221225472 SEA_Sta 0;
BA_ "Description" SG_ 3221225472 SEA_Sta "SEA tells Body control unit to operate Child door lock to lock";
BA_ "Version" SG_ 3221225472 SEA_OnOffEquipSta "17.12.00";
BA_ "RoutingFactor" SG_ 3221225472 SEA_OnOffEquipSta 3;
BA_ "UserSigValidity" SG_ 3221225472 SEA_OnOffEquipSta 0;
BA_ "Description" SG_ 3221225472 SEA_OnOffEquipSta "This signal indicates the on/off status of SEA";
BA_ "Version" SG_ 3221225472 SEA_LftWrngSta "17.12.00";
BA_ "RoutingFactor" SG_ 3221225472 SEA_LftWrngSta 3;
BA_ "UserSigValidity" SG_ 3221225472 SEA_LftWrngSta 0;
BA_ "Description" SG_ 3221225472 SEA_LftWrngSta "This signal carries the information which message shall be displayed to the driver when the system must activate SEA";
BA_ "Version" SG_ 3221225472 SEA_RtWrngSta "17.12.00";
BA_ "RoutingFactor" SG_ 3221225472 SEA_RtWrngSta 3;
BA_ "UserSigValidity" SG_ 3221225472 SEA_RtWrngSta 0;
BA_ "Description" SG_ 3221225472 SEA_RtWrngSta "This signal carries the information which message shall be displayed to the driver when the system must activate SEA";
BA_ "Version" SG_ 3221225472 MFSW_Crc2Val "18.11.08";
BA_ "UserSigValidity" SG_ 3221225472 MFSW_Crc2Val 0;
BA_ "GenSigStartValue" SG_ 3221225472 MFSW_Crc2Val 255;
BA_ "GenSigSendType" SG_ 3221225472 MFSW_Crc2Val 4;
BA_ "Description" SG_ 3221225472 MFSW_Crc2Val "The data area for CRC calculation is based on the data length (DLC) of the message DB.

The CRC shall be calculated over the entire data block (excluding the CRC bytes) including the user data, alive counter and Data ID 

 

- CRC Polynomial (0x1D) , Ini";
BA_ "Version" SG_ 3221225472 MFSW_AlvCnt2Val "18.11.08";
BA_ "UserSigValidity" SG_ 3221225472 MFSW_AlvCnt2Val 0;
BA_ "GenSigSendType" SG_ 3221225472 MFSW_AlvCnt2Val 4;
BA_ "Description" SG_ 3221225472 MFSW_AlvCnt2Val "For the first transmission request for a data element the counter shall be initialized with 0 and shall be incremented by 1

for every subsequent send request. When the counter reaches the maximum value(0xE), then it shall restart with 0 for the next sen";
BA_ "Version" SG_ 3221225472 Wiper_FrWiperSwSta "17.12.08";
BA_ "NetworkRequestHoldingTime" SG_ 3221225472 Wiper_FrWiperSwSta 5000;
BA_ "NetworkRequest" SG_ 3221225472 Wiper_FrWiperSwSta 0;
BA_ "UserSigValidity" SG_ 3221225472 Wiper_FrWiperSwSta 0;
BA_ "GenSigSendType" SG_ 3221225472 Wiper_FrWiperSwSta 4;
BA_ "Description" SG_ 3221225472 Wiper_FrWiperSwSta "Multifuction Front Wiper Switch Status



The value '0x1' means 'Int Sw On' or 'Auto Sw on' and its status determined by 'C_RainSnsOption' signal



0x1 : Wiper Int Sw on (C_RainSnsOption = 0x0)



0x1 : Wiper Auto Sw on (C_RainSnsOption = 0x1)";
BA_ "Version" SG_ 3221225472 Wiper_IntStepSta "17.12.08";
BA_ "NetworkRequestHoldingTime" SG_ 3221225472 Wiper_IntStepSta 5000;
BA_ "NetworkRequest" SG_ 3221225472 Wiper_IntStepSta 0;
BA_ "UserSigValidity" SG_ 3221225472 Wiper_IntStepSta 0;
BA_ "GenSigSendType" SG_ 3221225472 Wiper_IntStepSta 4;
BA_ "Version" SG_ 3221225472 Wiper_MstSwSta "17.12.08";
BA_ "NetworkRequestHoldingTime" SG_ 3221225472 Wiper_MstSwSta 5000;
BA_ "NetworkRequest" SG_ 3221225472 Wiper_MstSwSta 0;
BA_ "UserSigValidity" SG_ 3221225472 Wiper_MstSwSta 0;
BA_ "GenSigSendType" SG_ 3221225472 Wiper_MstSwSta 4;
BA_ "Version" SG_ 3221225472 Wiper_FrWiperWshSwSta "17.12.08";
BA_ "NetworkRequestHoldingTime" SG_ 3221225472 Wiper_FrWiperWshSwSta 5000;
BA_ "NetworkRequest" SG_ 3221225472 Wiper_FrWiperWshSwSta 0;
BA_ "UserSigValidity" SG_ 3221225472 Wiper_FrWiperWshSwSta 0;
BA_ "GenSigSendType" SG_ 3221225472 Wiper_FrWiperWshSwSta 4;
BA_ "Description" SG_ 3221225472 Wiper_FrWiperWshSwSta "Multifunction Front Wiper Washer Switch Status";
BA_ "Version" SG_ 3221225472 MFSW_Info "17.12.08";
BA_ "NetworkRequestHoldingTime" SG_ 3221225472 MFSW_Info 5000;
BA_ "NetworkRequest" SG_ 3221225472 MFSW_Info 0;
BA_ "UserSigValidity" SG_ 3221225472 MFSW_Info 0;
BA_ "GenSigSendType" SG_ 3221225472 MFSW_Info 4;
BA_ "Description" SG_ 3221225472 MFSW_Info "Mulitfunction switch information 

This signal is used to determine 'CAN type Multifunction switch' is applied or not in this vehicle.



0x0 : CAN type MFSW is Not Applied

0x1 : CAN type MFSW Applied



G/WAY Signal from MFSW (C_MFSW_Info)

- Follow to";
BA_ "Version" SG_ 3221225472 PROLONG_V2_Value "18.01.07";
BA_ "NetworkRequest" SG_ 3221225472 PROLONG_V2_Value 0;
BA_ "UserSigValidity" SG_ 3221225472 PROLONG_V2_Value 3;
BA_ "GenSigSendType" SG_ 3221225472 PROLONG_V2_Value 4;
BA_ "Description" SG_ 3221225472 PROLONG_V2_Value "[Default Value]



0xFFFFFFFF";
BA_ "Version" SG_ 3221225472 PROLONG_V2_Offset "18.01.07";
BA_ "NetworkRequest" SG_ 3221225472 PROLONG_V2_Offset 0;
BA_ "UserSigValidity" SG_ 3221225472 PROLONG_V2_Offset 3;
BA_ "GenSigStartValue" SG_ 3221225472 PROLONG_V2_Offset 8191;
BA_ "GenSigSendType" SG_ 3221225472 PROLONG_V2_Offset 4;
BA_ "Description" SG_ 3221225472 PROLONG_V2_Offset "[Default Value]

0x1FFF";
BA_ "Version" SG_ 3221225472 PROLONG_V2_CyclicCounter "18.01.07";
BA_ "NetworkRequest" SG_ 3221225472 PROLONG_V2_CyclicCounter 0;
BA_ "UserSigValidity" SG_ 3221225472 PROLONG_V2_CyclicCounter 3;
BA_ "GenSigSendType" SG_ 3221225472 PROLONG_V2_CyclicCounter 4;
BA_ "Description" SG_ 3221225472 PROLONG_V2_CyclicCounter "[Default Value]

0x0";
BA_ "Version" SG_ 3221225472 PROLONG_V2_Update "18.01.07";
BA_ "NetworkRequest" SG_ 3221225472 PROLONG_V2_Update 0;
BA_ "UserSigValidity" SG_ 3221225472 PROLONG_V2_Update 3;
BA_ "GenSigSendType" SG_ 3221225472 PROLONG_V2_Update 4;
BA_ "Description" SG_ 3221225472 PROLONG_V2_Update "[Default Value]

0x0";
BA_ "Version" SG_ 3221225472 PROLONG_V2_PathIndex "18.01.07";
BA_ "NetworkRequest" SG_ 3221225472 PROLONG_V2_PathIndex 0;
BA_ "UserSigValidity" SG_ 3221225472 PROLONG_V2_PathIndex 3;
BA_ "GenSigSendType" SG_ 3221225472 PROLONG_V2_PathIndex 4;
BA_ "Description" SG_ 3221225472 PROLONG_V2_PathIndex "[Default Value]

0x0";
BA_ "Version" SG_ 3221225472 PROLONG_V2_ProfileType "18.01.07";
BA_ "NetworkRequest" SG_ 3221225472 PROLONG_V2_ProfileType 0;
BA_ "UserSigValidity" SG_ 3221225472 PROLONG_V2_ProfileType 3;
BA_ "GenSigSendType" SG_ 3221225472 PROLONG_V2_ProfileType 4;
BA_ "Description" SG_ 3221225472 PROLONG_V2_ProfileType "[Default Value]

0x0";
BA_ "Version" SG_ 3221225472 VCU_Crc2Val "19.03.03";
BA_ "RoutingFactor" SG_ 3221225472 VCU_Crc2Val 5;
BA_ "UserSigValidity" SG_ 3221225472 VCU_Crc2Val 7;
BA_ "GenSigStartValue" SG_ 3221225472 VCU_Crc2Val 65535;
BA_ "Description" SG_ 3221225472 VCU_Crc2Val "The CRC checking process calculates the CRC over the entire data block, including the CRC result.

- CRC Polynomial (0x1021) , Initial Value : 0xFFFF, XOR value : 0x0000

- The mathematical expression to 16 bit CRC polynomial is given here. G(x) = x16 + ";
BA_ "Version" SG_ 3221225472 VCU_MaxRgnWhlTqRearVal "19.03.03";
BA_ "RoutingFactor" SG_ 3221225472 VCU_MaxRgnWhlTqRearVal 5;
BA_ "UserSigValidity" SG_ 3221225472 VCU_MaxRgnWhlTqRearVal 7;
BA_ "Version" SG_ 3221225472 VCU_CrpWhlTqFrntVal "19.03.03";
BA_ "RoutingFactor" SG_ 3221225472 VCU_CrpWhlTqFrntVal 5;
BA_ "UserSigValidity" SG_ 3221225472 VCU_CrpWhlTqFrntVal 7;
BA_ "Description" SG_ 3221225472 VCU_CrpWhlTqFrntVal "Creep Torque at Front Wheel";
BA_ "Version" SG_ 3221225472 VCU_CrpWhlTqRearVal "19.03.03";
BA_ "RoutingFactor" SG_ 3221225472 VCU_CrpWhlTqRearVal 5;
BA_ "UserSigValidity" SG_ 3221225472 VCU_CrpWhlTqRearVal 7;
BA_ "Description" SG_ 3221225472 VCU_CrpWhlTqRearVal "Creep Torque at Rear Wheel";
BA_ "Version" SG_ 3221225472 VCU_AlvCnt2Val "19.03.03";
BA_ "RoutingFactor" SG_ 3221225472 VCU_AlvCnt2Val 5;
BA_ "UserSigValidity" SG_ 3221225472 VCU_AlvCnt2Val 7;
BA_ "Description" SG_ 3221225472 VCU_AlvCnt2Val "For the first transmission request for a data element the counter shall be initialized with 0 and shall be incremented by 1

for every subsequent send request. When the counter reaches the maximum value(0xFF), then it shall restart with ? for the next se";
BA_ "Version" SG_ 3221225472 VCU_RegenBrkWhlTqFrntVal "19.03.03";
BA_ "RoutingFactor" SG_ 3221225472 VCU_RegenBrkWhlTqFrntVal 5;
BA_ "UserSigValidity" SG_ 3221225472 VCU_RegenBrkWhlTqFrntVal 7;
BA_ "Description" SG_ 3221225472 VCU_RegenBrkWhlTqFrntVal "Regenerative Braking Wheel Torque of Front Motor";
BA_ "Version" SG_ 3221225472 VCU_RegenBrkWhlTqRearVal "19.03.03";
BA_ "RoutingFactor" SG_ 3221225472 VCU_RegenBrkWhlTqRearVal 5;
BA_ "UserSigValidity" SG_ 3221225472 VCU_RegenBrkWhlTqRearVal 7;
BA_ "Description" SG_ 3221225472 VCU_RegenBrkWhlTqRearVal "Regenerative Braking Wheel Torque of Rear Motor";
BA_ "Version" SG_ 3221225472 VCU_RspaOpSta "19.03.03";
BA_ "RoutingFactor" SG_ 3221225472 VCU_RspaOpSta 5;
BA_ "UserSigValidity" SG_ 3221225472 VCU_RspaOpSta 7;
BA_ "GenSigStartValue" SG_ 3221225472 VCU_RspaOpSta 1;
BA_ "Version" SG_ 3221225472 VCU_RspaCanFailSta "19.03.03";
BA_ "RoutingFactor" SG_ 3221225472 VCU_RspaCanFailSta 5;
BA_ "UserSigValidity" SG_ 3221225472 VCU_RspaCanFailSta 7;
BA_ "Version" SG_ 3221225472 VCU_BrkLampOnReq "19.04.00";
BA_ "RoutingFactor" SG_ 3221225472 VCU_BrkLampOnReq 5;
BA_ "UserSigValidity" SG_ 3221225472 VCU_BrkLampOnReq 7;
BA_ "Description" SG_ 3221225472 VCU_BrkLampOnReq "Brake Lamp On Request";
BA_ "Version" SG_ 3221225472 VCU_StdMotTqFrntVal "19.03.03";
BA_ "RoutingFactor" SG_ 3221225472 VCU_StdMotTqFrntVal 5;
BA_ "UserSigValidity" SG_ 3221225472 VCU_StdMotTqFrntVal 7;
BA_ "Description" SG_ 3221225472 VCU_StdMotTqFrntVal "Standard Torque of Front Motor";
BA_ "Version" SG_ 3221225472 VCU_StdMotTqRearVal "19.03.03";
BA_ "RoutingFactor" SG_ 3221225472 VCU_StdMotTqRearVal 5;
BA_ "UserSigValidity" SG_ 3221225472 VCU_StdMotTqRearVal 7;
BA_ "Description" SG_ 3221225472 VCU_StdMotTqRearVal "Standard Torque of Rear Motor";
BA_ "Version" SG_ 3221225472 VCU_MotTqCmdBInvFrntPcVal "19.03.03";
BA_ "RoutingFactor" SG_ 3221225472 VCU_MotTqCmdBInvFrntPcVal 5;
BA_ "UserSigValidity" SG_ 3221225472 VCU_MotTqCmdBInvFrntPcVal 7;
BA_ "Description" SG_ 3221225472 VCU_MotTqCmdBInvFrntPcVal "Raw(Before Intervention) Torque Command for Front Motor";
BA_ "Version" SG_ 3221225472 VCU_MotTqCmdBInvRearPcVal "19.03.03";
BA_ "RoutingFactor" SG_ 3221225472 VCU_MotTqCmdBInvRearPcVal 5;
BA_ "UserSigValidity" SG_ 3221225472 VCU_MotTqCmdBInvRearPcVal 7;
BA_ "Description" SG_ 3221225472 VCU_MotTqCmdBInvRearPcVal "Raw(Before Intervention) Torque Command for Rear Motor";
BA_ "Version" SG_ 3221225472 VCU_MotTqCmdFrntPcVal "19.03.03";
BA_ "RoutingFactor" SG_ 3221225472 VCU_MotTqCmdFrntPcVal 5;
BA_ "UserSigValidity" SG_ 3221225472 VCU_MotTqCmdFrntPcVal 7;
BA_ "Description" SG_ 3221225472 VCU_MotTqCmdFrntPcVal "Torque Command for Front Motor";
BA_ "Version" SG_ 3221225472 VCU_MotTqCmdRearPcVal "19.03.03";
BA_ "RoutingFactor" SG_ 3221225472 VCU_MotTqCmdRearPcVal 5;
BA_ "UserSigValidity" SG_ 3221225472 VCU_MotTqCmdRearPcVal 7;
BA_ "Description" SG_ 3221225472 VCU_MotTqCmdRearPcVal "Torque Command for Rear Motor";
BA_ "Version" SG_ 3221225472 VCU_RegenEnaFrntSta "19.03.03";
BA_ "RoutingFactor" SG_ 3221225472 VCU_RegenEnaFrntSta 5;
BA_ "UserSigValidity" SG_ 3221225472 VCU_RegenEnaFrntSta 7;
BA_ "Description" SG_ 3221225472 VCU_RegenEnaFrntSta "Regen Enable Status for Front Motor";
BA_ "Version" SG_ 3221225472 VCU_RegenEnaRearSta "19.03.03";
BA_ "RoutingFactor" SG_ 3221225472 VCU_RegenEnaRearSta 5;
BA_ "UserSigValidity" SG_ 3221225472 VCU_RegenEnaRearSta 7;
BA_ "Description" SG_ 3221225472 VCU_RegenEnaRearSta "Regen Enable Status for Rear Motor";
BA_ "Version" SG_ 3221225472 VCU_4wdModSta "19.03.03";
BA_ "RoutingFactor" SG_ 3221225472 VCU_4wdModSta 5;
BA_ "UserSigValidity" SG_ 3221225472 VCU_4wdModSta 7;
BA_ "Version" SG_ 3221225472 VCU_EpbEngageReq "19.03.03";
BA_ "RoutingFactor" SG_ 3221225472 VCU_EpbEngageReq 5;
BA_ "UserSigValidity" SG_ 3221225472 VCU_EpbEngageReq 7;
BA_ "Description" SG_ 3221225472 VCU_EpbEngageReq "EPB Request";
BA_ "Version" SG_ 3221225472 VCU_MaxRgnWhlTqFrntVal "19.03.03";
BA_ "RoutingFactor" SG_ 3221225472 VCU_MaxRgnWhlTqFrntVal 5;
BA_ "UserSigValidity" SG_ 3221225472 VCU_MaxRgnWhlTqFrntVal 7;
BA_ "Version" SG_ 3221225472 RSC_TqIntrvntnVal_Frnt "19.05.03";
BA_ "RoutingFactor" SG_ 3221225472 RSC_TqIntrvntnVal_Frnt 5;
BA_ "UserSigValidity" SG_ 3221225472 RSC_TqIntrvntnVal_Frnt 3;
BA_ "Description" SG_ 3221225472 RSC_TqIntrvntnVal_Frnt "RSC ��� ���� ���� ������ũ�� �䱸���� �ǹ�.

��ȣ�� RSC_TqFlag_Frnt ��ȣ�� ����.";
BA_ "Version" SG_ 3221225472 RSC_TqIntrvntnVal_Rear "19.05.03";
BA_ "RoutingFactor" SG_ 3221225472 RSC_TqIntrvntnVal_Rear 5;
BA_ "UserSigValidity" SG_ 3221225472 RSC_TqIntrvntnVal_Rear 3;
BA_ "Description" SG_ 3221225472 RSC_TqIntrvntnVal_Rear "RSC ��� ���� �ķ� ������ũ�� �䱸���� �ǹ�.

��ȣ�� RSC_TqFlag_Rear ��ȣ�� ����.";
BA_ "Version" SG_ 293 SAS_Crc1Val "18.11.08";
BA_ "RoutingFactor" SG_ 293 SAS_Crc1Val 5;
BA_ "UserSigValidity" SG_ 293 SAS_Crc1Val 3;
BA_ "GenSigStartValue" SG_ 293 SAS_Crc1Val 65535;
BA_ "Description" SG_ 293 SAS_Crc1Val "The data area for CRC calculation is based on the data length (DLC) of the message DB.

The CRC shall be calculated over the entire data block (excluding the CRC bytes) including the user data, alive counter and Data ID

 

- CRC Polynomial (0x1021) , In";
BA_ "Version" SG_ 293 SAS_AlvCnt1Val "18.11.08";
BA_ "RoutingFactor" SG_ 293 SAS_AlvCnt1Val 5;
BA_ "UserSigValidity" SG_ 293 SAS_AlvCnt1Val 3;
BA_ "Description" SG_ 293 SAS_AlvCnt1Val "For the first transmission request for a data element the counter shall be initialized with 0 and shall be incremented by 1 for every subsequent send request. 

When the counter reaches the maximum value(0xFF), then it shall restart with 0 for the next s";
BA_ "Version" SG_ 293 SAS_AnglVal "18.12.08";
BA_ "RoutingFactor" SG_ 293 SAS_AnglVal 5;
BA_ "UserSigValidity" SG_ 293 SAS_AnglVal 3;
BA_ "Description" SG_ 293 SAS_AnglVal "Information regarding the steering wheel angle.  (PH) = (HEX) * 0.1 (0 <  HEX < 7FFFH) or (PH) = (HEX - 65536) * 0.1 (HEX > 7FFFH)";
BA_ "Version" SG_ 293 SAS_SpdVal "18.12.08";
BA_ "RoutingFactor" SG_ 293 SAS_SpdVal 5;
BA_ "UserSigValidity" SG_ 293 SAS_SpdVal 3;
BA_ "GenSigStartValue" SG_ 293 SAS_SpdVal 255;
BA_ "Description" SG_ 293 SAS_SpdVal "Information regarding the steering wheel rotation speed 

(PH) = (HEX) * 4 (0 �� HEX < 254)";
BA_ "Version" SG_ 293 SAS_IntSta "17.11.00";
BA_ "RoutingFactor" SG_ 293 SAS_IntSta 5;
BA_ "UserSigValidity" SG_ 293 SAS_IntSta 3;
BA_ "GenSigStartValue" SG_ 293 SAS_IntSta 7;
BA_ "Description" SG_ 293 SAS_IntSta "Information regarding the steering angle sensor��s internal state. If SAS_AnglVal value is O.K., SAS_OK flag is set and otherwise SAS_OK flag is cleared. If steering angle sensor has been calibrated, SAS_CAL flag is set and otherwise cleared.

SF1 - SF5 ";
BA_ "Version" SG_ 101 IEB_Crc1Val "19.05.02";
BA_ "RoutingFactor" SG_ 101 IEB_Crc1Val 5;
BA_ "UserSigValidity" SG_ 101 IEB_Crc1Val 3;
BA_ "GenSigStartValue" SG_ 101 IEB_Crc1Val 65535;
BA_ "Description" SG_ 101 IEB_Crc1Val "The data area for CRC calculation is based on the data length (DLC) of the message DB.

The CRC shall be calculated over the entire data block (excluding the CRC bytes) including the user data, alive counter and Data ID

 

- CRC Polynomial (0x1021) , In";
BA_ "Version" SG_ 101 IEB_StrkDpthPcVal "19.05.02";
BA_ "RoutingFactor" SG_ 101 IEB_StrkDpthPcVal 5;
BA_ "UserSigValidity" SG_ 101 IEB_StrkDpthPcVal 3;
BA_ "Description" SG_ 101 IEB_StrkDpthPcVal "Brake Pedal Stroke Depth";
BA_ "Version" SG_ 101 IEB_EstDpthPcVal "19.05.02";
BA_ "RoutingFactor" SG_ 101 IEB_EstDpthPcVal 5;
BA_ "UserSigValidity" SG_ 101 IEB_EstDpthPcVal 3;
BA_ "Description" SG_ 101 IEB_EstDpthPcVal "Estimated Brake Pedal Depth for SCC";
BA_ "Version" SG_ 101 IEB_AbsNGearReq "19.05.02";
BA_ "RoutingFactor" SG_ 101 IEB_AbsNGearReq 5;
BA_ "UserSigValidity" SG_ 101 IEB_AbsNGearReq 3;
BA_ "Description" SG_ 101 IEB_AbsNGearReq "indigates N gear position request while ABS activation";
BA_ "Version" SG_ 101 IEB_EstBrkPdlValVldSta "19.05.02";
BA_ "RoutingFactor" SG_ 101 IEB_EstBrkPdlValVldSta 5;
BA_ "UserSigValidity" SG_ 101 IEB_EstBrkPdlValVldSta 3;
BA_ "GenSigStartValue" SG_ 101 IEB_EstBrkPdlValVldSta 1;
BA_ "Description" SG_ 101 IEB_EstBrkPdlValVldSta "Estimated Brake pedal value Validity";
BA_ "Version" SG_ 101 IEB_InhbtTrnstnTo4wd_Req "19.05.03";
BA_ "RoutingFactor" SG_ 101 IEB_InhbtTrnstnTo4wd_Req 5;
BA_ "UserSigValidity" SG_ 101 IEB_InhbtTrnstnTo4wd_Req 3;
BA_ "Description" SG_ 101 IEB_InhbtTrnstnTo4wd_Req "�� ��ȣ�� 2WD ��忡�� �����ÿ� 4WD ��ȯ ������ ��û�ϴ� ��ȣ�̴�.";
BA_ "Version" SG_ 101 IEB_RegenTqLimitNmVal_Rear "19.05.03";
BA_ "RoutingFactor" SG_ 101 IEB_RegenTqLimitNmVal_Rear 5;
BA_ "UserSigValidity" SG_ 101 IEB_RegenTqLimitNmVal_Rear 3;
BA_ "Description" SG_ 101 IEB_RegenTqLimitNmVal_Rear "Regen Brake Torque limit at rear wheel";
BA_ "Version" SG_ 101 IEB_TCS_Req "19.05.03";
BA_ "RoutingFactor" SG_ 101 IEB_TCS_Req 5;
BA_ "UserSigValidity" SG_ 101 IEB_TCS_Req 3;
BA_ "Description" SG_ 101 IEB_TCS_Req "�� ��ȣ�� IEB_01_10ms �޽����� TCS ��ũ ��ȣ�� ���� Validity�� �ǹ��Ѵ�.";
BA_ "Version" SG_ 101 IEB_RSC_Req "19.05.03";
BA_ "RoutingFactor" SG_ 101 IEB_RSC_Req 5;
BA_ "UserSigValidity" SG_ 101 IEB_RSC_Req 3;
BA_ "Description" SG_ 101 IEB_RSC_Req "�� ��ȣ�� IEB_01_10ms �޽����� RSC ��ũ ��ȣ�� ���� Validity�� �ǹ��Ѵ�.";
BA_ "Version" SG_ 101 TCS_TqFlag_Frnt "19.05.03";
BA_ "RoutingFactor" SG_ 101 TCS_TqFlag_Frnt 5;
BA_ "UserSigValidity" SG_ 101 TCS_TqFlag_Frnt 3;
BA_ "Description" SG_ 101 TCS_TqFlag_Frnt "�� ��ȣ�� IEB_01_10ms �޽����� TCS ���� ��ũ ��ȣ�� ���� ��ȣ�� �ǹ��Ѵ�.";
BA_ "Version" SG_ 101 TCS_TqFlag_Rear "19.05.03";
BA_ "RoutingFactor" SG_ 101 TCS_TqFlag_Rear 5;
BA_ "UserSigValidity" SG_ 101 TCS_TqFlag_Rear 3;
BA_ "Description" SG_ 101 TCS_TqFlag_Rear "�� ��ȣ�� IEB_01_10ms �޽����� TCS �ķ� ��ũ ��ȣ�� ���� ��ȣ�� �ǹ��Ѵ�.";
BA_ "Version" SG_ 101 RSC_TqFlag_Frnt "19.05.03";
BA_ "RoutingFactor" SG_ 101 RSC_TqFlag_Frnt 5;
BA_ "UserSigValidity" SG_ 101 RSC_TqFlag_Frnt 3;
BA_ "Description" SG_ 101 RSC_TqFlag_Frnt "�� ��ȣ�� IEB_01_10ms �޽����� RSC ���� ��ũ ��ȣ�� ���� ��ȣ�� �ǹ��Ѵ�.";
BA_ "Version" SG_ 101 RSC_TqFlag_Rear "19.05.03";
BA_ "RoutingFactor" SG_ 101 RSC_TqFlag_Rear 5;
BA_ "UserSigValidity" SG_ 101 RSC_TqFlag_Rear 3;
BA_ "Description" SG_ 101 RSC_TqFlag_Rear "�� ��ȣ�� IEB_01_10ms �޽����� RSC �ķ� ��ũ ��ȣ�� ���� ��ȣ�� �ǹ��Ѵ�.";
BA_ "Version" SG_ 101 IEB_AlvCnt1Val "19.05.02";
BA_ "RoutingFactor" SG_ 101 IEB_AlvCnt1Val 5;
BA_ "UserSigValidity" SG_ 101 IEB_AlvCnt1Val 3;
BA_ "Description" SG_ 101 IEB_AlvCnt1Val "For the first transmission request for a data element the counter shall be initialized with 0 and shall be incremented by 1 for every subsequent send request. 

When the counter reaches the maximum value(0xFF), then it shall restart with 0 for the next s";
BA_ "Version" SG_ 101 TCS_TqIntrvntnVal_Frnt "19.05.03";
BA_ "RoutingFactor" SG_ 101 TCS_TqIntrvntnVal_Frnt 5;
BA_ "UserSigValidity" SG_ 101 TCS_TqIntrvntnVal_Frnt 3;
BA_ "Description" SG_ 101 TCS_TqIntrvntnVal_Frnt "TCS ��� ���� ���� ������ũ�� �䱸���� �ǹ�.

��ȣ�� TCS_TqFlag_Frnt ��ȣ�� ����.";
BA_ "Version" SG_ 101 TCS_TqIntrvntnVal_Rear "19.05.03";
BA_ "RoutingFactor" SG_ 101 TCS_TqIntrvntnVal_Rear 5;
BA_ "UserSigValidity" SG_ 101 TCS_TqIntrvntnVal_Rear 3;
BA_ "Description" SG_ 101 TCS_TqIntrvntnVal_Rear "TCS ��� ���� �ķ� ������ũ�� �䱸���� �ǹ�.

��ȣ�� TCS_TqFlag_Rear ��ȣ�� ����.";
BA_ "Version" SG_ 101 IEB_SrvLmpDis "19.05.02";
BA_ "RoutingFactor" SG_ 101 IEB_SrvLmpDis 5;
BA_ "UserSigValidity" SG_ 101 IEB_SrvLmpDis 3;
BA_ "Description" SG_ 101 IEB_SrvLmpDis "The signal indicates the status of the ��AHB Service lamp��";
BA_ "Version" SG_ 101 IEB_DfctvSta "19.05.02";
BA_ "RoutingFactor" SG_ 101 IEB_DfctvSta 5;
BA_ "UserSigValidity" SG_ 101 IEB_DfctvSta 3;
BA_ "Description" SG_ 101 IEB_DfctvSta "Information regarding the AHB 'defective' indication.";
BA_ "Version" SG_ 101 IEB_ActvSta "19.05.02";
BA_ "RoutingFactor" SG_ 101 IEB_ActvSta 5;
BA_ "UserSigValidity" SG_ 101 IEB_ActvSta 3;
BA_ "Description" SG_ 101 IEB_ActvSta "Information regarding AHB ��Control Active�� signal";
BA_ "Version" SG_ 101 IEB_DiagSta "19.05.02";
BA_ "RoutingFactor" SG_ 101 IEB_DiagSta 5;
BA_ "UserSigValidity" SG_ 101 IEB_DiagSta 3;
BA_ "Description" SG_ 101 IEB_DiagSta "Information regarding the AHB ��diagnostic mode�� indication.";
BA_ "Version" SG_ 101 IEB_WrngLmpDis "19.05.02";
BA_ "RoutingFactor" SG_ 101 IEB_WrngLmpDis 5;
BA_ "UserSigValidity" SG_ 101 IEB_WrngLmpDis 3;
BA_ "Description" SG_ 101 IEB_WrngLmpDis "The signal indicates the status of the ��AHB Warning lamp��";
BA_ "Version" SG_ 101 IEB_MILReq "19.05.02";
BA_ "RoutingFactor" SG_ 101 IEB_MILReq 5;
BA_ "UserSigValidity" SG_ 101 IEB_MILReq 3;
BA_ "Description" SG_ 101 IEB_MILReq "IEB sends this signal to turn on the Malfunction Indicator Lamp (MIL).";
BA_ "Version" SG_ 101 IEB_StrkDpthmmVal "19.05.02";
BA_ "RoutingFactor" SG_ 101 IEB_StrkDpthmmVal 5;
BA_ "UserSigValidity" SG_ 101 IEB_StrkDpthmmVal 3;
BA_ "Description" SG_ 101 IEB_StrkDpthmmVal "The signal indicates the depth of brake pedal";
BA_ "Version" SG_ 101 IEB_BrkActvSta "19.05.05";
BA_ "RoutingFactor" SG_ 101 IEB_BrkActvSta 5;
BA_ "UserSigValidity" SG_ 101 IEB_BrkActvSta 3;
BA_ "Description" SG_ 101 IEB_BrkActvSta "This signal indicates that a brake switch is activated or not. When the brake switch is activated(pressed) its value is 02H otherwise its value is 01H.

If the ECU does not support this signal the value is 00H.



�� ��ȣ�� EV, FCEV ������ ���� �� ����";
BA_ "Version" SG_ 101 IEB_PdlTrvlSnsrFailSta "19.05.02";
BA_ "RoutingFactor" SG_ 101 IEB_PdlTrvlSnsrFailSta 5;
BA_ "UserSigValidity" SG_ 101 IEB_PdlTrvlSnsrFailSta 3;
BA_ "Description" SG_ 101 IEB_PdlTrvlSnsrFailSta "Information regarding the pedal travel sensor fail status";
BA_ "Version" SG_ 101 IEB_PdlCalibSta "19.05.02";
BA_ "RoutingFactor" SG_ 101 IEB_PdlCalibSta 5;
BA_ "UserSigValidity" SG_ 101 IEB_PdlCalibSta 3;
BA_ "Description" SG_ 101 IEB_PdlCalibSta "Information regarding the pedal travel sensor��s calibration status";
BA_ "Version" SG_ 101 IEB_BzrSta "19.05.02";
BA_ "RoutingFactor" SG_ 101 IEB_BzrSta 5;
BA_ "UserSigValidity" SG_ 101 IEB_BzrSta 3;
BA_ "Description" SG_ 101 IEB_BzrSta "The signal indicates the status of the ��Buzzer��";
BA_ "Version" SG_ 101 IEB_Sta "19.06.01";
BA_ "RoutingFactor" SG_ 101 IEB_Sta 5;
BA_ "UserSigValidity" SG_ 101 IEB_Sta 3;
BA_ "Description" SG_ 101 IEB_Sta "EBS Ready Status

�� ��/�ķ��� ���� ������ ���� ��쿡�� 0x0 (Not Ready) / 0x1(Ready) �� ����Ѵ�.

     : ���� ���� ȸ������ ������ ���, 0x0 �� Front not Ready / 0x1�� Front only Ready�� �ǹ���.";
BA_ "Version" SG_ 101 IEB_SnsrFailSta "19.05.02";
BA_ "RoutingFactor" SG_ 101 IEB_SnsrFailSta 5;
BA_ "UserSigValidity" SG_ 101 IEB_SnsrFailSta 3;
BA_ "Version" SG_ 101 IEB_RbsWrngLmpSta "19.05.02";
BA_ "RoutingFactor" SG_ 101 IEB_RbsWrngLmpSta 5;
BA_ "UserSigValidity" SG_ 101 IEB_RbsWrngLmpSta 3;
BA_ "Description" SG_ 101 IEB_RbsWrngLmpSta "This signal indicates RBS warning lamp status.";
BA_ "Version" SG_ 101 IEB_VacSysDfctvSta "19.05.02";
BA_ "RoutingFactor" SG_ 101 IEB_VacSysDfctvSta 5;
BA_ "UserSigValidity" SG_ 101 IEB_VacSysDfctvSta 3;
BA_ "Description" SG_ 101 IEB_VacSysDfctvSta "This signal indicates Vacuum pump ��defective��.";
BA_ "Version" SG_ 101 IEB_RegenTqLimitNmVal_Frnt "19.05.03";
BA_ "RoutingFactor" SG_ 101 IEB_RegenTqLimitNmVal_Frnt 5;
BA_ "UserSigValidity" SG_ 101 IEB_RegenTqLimitNmVal_Frnt 3;
BA_ "Description" SG_ 101 IEB_RegenTqLimitNmVal_Frnt "Regen Brake Torque limit at front wheel";
BA_ "Version" SG_ 101 IEB_EstTtlBrkFrcNmVal "19.05.02";
BA_ "RoutingFactor" SG_ 101 IEB_EstTtlBrkFrcNmVal 5;
BA_ "UserSigValidity" SG_ 101 IEB_EstTtlBrkFrcNmVal 3;
BA_ "Description" SG_ 101 IEB_EstTtlBrkFrcNmVal "Estimated Total Brake Force";
BA_ "Version" SG_ 418 CLU_Crc1Val "18.11.08";
BA_ "RoutingFactor" SG_ 418 CLU_Crc1Val 5;
BA_ "UserSigValidity" SG_ 418 CLU_Crc1Val 3;
BA_ "GenSigStartValue" SG_ 418 CLU_Crc1Val 65535;
BA_ "Description" SG_ 418 CLU_Crc1Val "The data area for CRC calculation is based on the data length (DLC) of the message DB.

The CRC shall be calculated over the entire data block (excluding the CRC bytes) including the user data, alive counter and Data ID

 

- CRC Polynomial (0x1021) , In";
BA_ "Version" SG_ 418 CLU_AlvCnt1Val "18.11.08";
BA_ "RoutingFactor" SG_ 418 CLU_AlvCnt1Val 5;
BA_ "UserSigValidity" SG_ 418 CLU_AlvCnt1Val 3;
BA_ "Description" SG_ 418 CLU_AlvCnt1Val "For the first transmission request for a data element the counter shall be initialized with 0 and shall be incremented by 1 for every subsequent send request. 

When the counter reaches the maximum value(0xFF), then it shall restart with 0 for the next s";
BA_ "Version" SG_ 418 CLU_DtntOutSta "17.11.00";
BA_ "RoutingFactor" SG_ 418 CLU_DtntOutSta 5;
BA_ "UserSigValidity" SG_ 418 CLU_DtntOutSta 0;
BA_ "Description" SG_ 418 CLU_DtntOutSta "This signal indicates the status of detent illumination. Cluster sends the detent information for a Unified Illumination system.";
BA_ "Version" SG_ 418 CLU_SpdUnitTyp "17.11.00";
BA_ "RoutingFactor" SG_ 418 CLU_SpdUnitTyp 5;
BA_ "UserSigValidity" SG_ 418 CLU_SpdUnitTyp 3;
BA_ "Description" SG_ 418 CLU_SpdUnitTyp "This signal indicates the unit of the speed displayed in the speedometer.";
BA_ "Version" SG_ 418 CLU_DisSpdDcmlVal "17.11.00";
BA_ "RoutingFactor" SG_ 418 CLU_DisSpdDcmlVal 5;
BA_ "UserSigValidity" SG_ 418 CLU_DisSpdDcmlVal 3;
BA_ "Description" SG_ 418 CLU_DisSpdDcmlVal "The signal 'CF_Clu_VanzDecimal' means the extra value of the signal 'CF_Clu_Vanz' (vehicle speed which is indicated in the speedometer)

Also, This signal should be sent in km/h or MPH according to the 'CF_Clu_SPEED_UNIT' signal.

CF_Clu_SPEED_UNIT = 0 :";
BA_ "Version" SG_ 418 CLU_RhstaLvlSta "17.11.00";
BA_ "RoutingFactor" SG_ 418 CLU_RhstaLvlSta 5;
BA_ "UserSigValidity" SG_ 418 CLU_RhstaLvlSta 0;
BA_ "Description" SG_ 418 CLU_RhstaLvlSta "This signal is used for a rheostat level of CLUSTER from 1 to 21 level (21 level : Detent) for a Unified Illumination system.



�� Start Value : Current value";
BA_ "Version" SG_ 418 CLU_DisSpdVal "17.12.03";
BA_ "RoutingFactor" SG_ 418 CLU_DisSpdVal 5;
BA_ "UserSigValidity" SG_ 418 CLU_DisSpdVal 3;
BA_ "Description" SG_ 418 CLU_DisSpdVal "The vehicle speed which is indicated in the speedmeter has to be sent to SCC. This value is used for evalution of SCC command values instead of the vehicle velocity in order to avoid significant difference between the speedmeter indicator and the set spe";
BA_ "Version" SG_ 418 CLU_DisTyp "18.08.05";
BA_ "RoutingFactor" SG_ 418 CLU_DisTyp 5;
BA_ "UserSigValidity" SG_ 418 CLU_DisTyp 3;
BA_ "Description" SG_ 418 CLU_DisTyp "Cluster Display Type Information for BVM display



<RG3>

Type1 : 8inch LCD

Type2 : 12.3inch LCD";
BA_ "Version" SG_ 418 CLU_DisSpdVal_KPH "17.12.09";
BA_ "RoutingFactor" SG_ 418 CLU_DisSpdVal_KPH 5;
BA_ "UserSigValidity" SG_ 418 CLU_DisSpdVal_KPH 3;
BA_ "Description" SG_ 418 CLU_DisSpdVal_KPH "The vehicle speed which is indicated in the speedmeter.

This signal should be sent in km/h only.";
VAL_ 3221225472 WakeUp_DoorLock_DrvDrUnLkSta 0 "Lock" 1 "Unlock" 2 "Default" 3 "Error Indicator" ;
VAL_ 3221225472 WakeUp_BCM_Ign1InSta 0 "IGN1 Off" 1 "IGN1 On" 2 "Not Used" 3 "Error Indicator" ;
VAL_ 3221225472 WakeUp_RKE_BtnReq 0 "None" 1 "Lock" 2 "Unlock" 3 "Trunk(Or Tail Gate)" 4 "Panic" 5 "Panic Stop" 6 "0x6" 7 "Remote Cranking Stop" 8 "Remote Cranking Start" 9 "Forward(RSPA)" 10 "Backward/Parking(RSPA)" 11 "Pause(RSPA)" 12 "Trunk Hold(or Tailgate Hold)" 13 "Trunk Stop(or Tailgate Stop)" 14 "Not Used" 15 "Error Indicator" ;
VAL_ 3221225472 WakeUp_Lamp_SmrtWlcmLtOnReq 0 "Off" 1 "On" 2 "Not Used" 3 "Error Indicator" ;
VAL_ 3221225472 WakeUp_DoorLock_AsstDrUnLkSta 0 "Lock" 1 "Unlock" 2 "Default" 3 "Error Indicator" ;
VAL_ 3221225472 WakeUp_DoorLock_RrLftDrUnLkSta 0 "Lock" 1 "Unlock" 2 "Default" 3 "Error Indicator" ;
VAL_ 3221225472 WakeUp_DoorLock_RrRtDrUnLkSta 0 "Lock" 1 "Unlock" 2 "Default" 3 "Error Indicator" ;
VAL_ 3221225472 WakeUp_Warn_AsstDrSwSta 0 "Close" 1 "Open" 2 "Default" 3 "Error Indicator" ;
VAL_ 3221225472 WakeUp_Warn_RrLftDrSwSta 0 "Close" 1 "Open" 2 "Default" 3 "Error Indicator" ;
VAL_ 3221225472 WakeUp_Warn_RrRtDrSwSta 0 "Close" 1 "Open" 2 "Default" 3 "Error Indicator" ;
VAL_ 3221225472 WakeUp_Trunk_TrnkTlgtSwSta 0 "Close(Full Lock)" 1 "Open(Not Full Lock)" 2 "Default" 3 "Error Indicator" ;
VAL_ 3221225472 WakeUp_Warn_DrvDrSwSta 0 "Close" 1 "Open" 2 "Default" 3 "Error Indicator" ;
VAL_ 3221225472 ODS_OccClassSta 1 "Class1" 2 "Class2" 4 "Indeterminate" ;
VAL_ 3221225472 ODS_SBRClassSta 0 "Empty / Indeterminate" 1 "Occupied" ;
VAL_ 3221225472 Bat_dischrg 0 "Flag OFF" 1 "Flag ON" ;
VAL_ 3221225472 Batt_SoCWarningValue 0 "0x0x0~0x64:0 ~ 100%" 100 "0x0x0~0x64:0 ~ 100%" 101 "0x65~0xFE:Reserved" 254 "0x65~0xFE:Reserved" 255 "Invalid" ;
VAL_ 3221225472 Batt_SoCAlertValue 0 "0x0x0~0x64:0 ~ 100%" 100 "0x0x0~0x64:0 ~ 100%" 101 "0x65~0xFE:Reserved" 254 "0x65~0xFE:Reserved" 255 "Invaild" ;
VAL_ 3221225472 C_StrgWhlHeatingOpt 0 "Not Applied" 1 "Applied(steering wheel applied)" 2 "Reserved" 3 "Invalid" ;
VAL_ 3221225472 BAlarm_BglrAlrmCurrentSta 0 "Off" 1 "DisArm" 2 "Arm" 3 "PreArm" 4 "ArmWait" 5 "ArmHold(Trunk)" 6 "ReArm" 7 "AutoLockTimer1" 8 "AutoLockTimer2" 9 "Alarm" 10 "Default" 11 "AutoLockTimer3(Tailgate)" 12 "Reserved" 13 "Reserved" 14 "Not Used" 15 "Error Indicator" ;
VAL_ 3221225472 BAlarm_BglrAlrmSta 0 "DIS-,PRE-,AUTOLOCKTIMER1,2,3(TG)" 1 "ARM,-WAIT,RE-,ALARM,-HD(Trunk)" 2 "Not Used" 3 "Error Indicator" ;
VAL_ 3221225472 BAlarm_PncAlrmSta 0 "Off" 1 "On (Panic Alarm ON)" 2 "Not Used" 3 "Error Indicator" ;
VAL_ 3221225472 BAlarm_BrglrHrnRlySta 0 "Off" 1 "On" 2 "Not Used" 3 "Error Indicator" ;
VAL_ 3221225472 BCM_AccInSta 0 "Acc Off" 1 "Acc On" 2 "Not Used" 3 "Error Indicator" ;
VAL_ 3221225472 BCM_Ign1InSta 0 "IGN1 Off" 1 "IGN1 On" 2 "Not Used" 3 "Error Indicator" ;
VAL_ 3221225472 BCM_Ign2InSta 0 "IGN2 Off" 1 "IGN2 On" 2 "Not Used" 3 "Error Indicator" ;
VAL_ 3221225472 BCM_IgnSwSta 0 "KeyOff" 1 "KeyIn" 2 "Acc" 3 "Ign" 4 "St" 5 "Reseved" 6 "Not Used" 7 "Error Indicator" ;
VAL_ 3221225472 CF_AVN_CluWelcomeSnd 0 "Default" 1 "Off" 2 "On" 3 "Invalid" ;
VAL_ 3221225472 CF_AVN_CluTransmissionDisp 0 "Default" 1 "Off" 2 "On" 3 "Invalid" ;
VAL_ 3221225472 CF_AVN_CluWiperLight 0 "Default" 1 "Off" 2 "On" 3 "Invalid" ;
VAL_ 3221225472 CF_AVN_CluRoadInfoGuide 0 "Default" 1 "Off" 2 "On" 3 "Invalid" ;
VAL_ 3221225472 CF_AVN_CluUserSettingPeriod 0 "0~99month" 1 "0~99month" 2 "0~99month" 3 "0~99month" 4 "0~99month" 5 "0~99month" 6 "0~99month" 7 "0~99month" 8 "0~99month" 9 "0~99month" 10 "0~99month" 11 "0~99month" 12 "0~99month" 13 "0~99month" 14 "0~99month" 15 "0~99month" 16 "0~99month" 17 "0~99month" 18 "0~99month" 19 "0~99month" 20 "0~99month" 21 "0~99month" 22 "0~99month" 23 "0~99month" 24 "0~99month" 25 "0~99month" 26 "0~99month" 27 "0~99month" 28 "0~99month" 29 "0~99month" 30 "0~99month" 31 "0~99month" 32 "0~99month" 33 "0~99month" 34 "0~99month" 35 "0~99month" 36 "0~99month" 37 "0~99month" 38 "0~99month" 39 "0~99month" 40 "0~99month" 41 "0~99month" 42 "0~99month" 43 "0~99month" 44 "0~99month" 45 "0~99month" 46 "0~99month" 47 "0~99month" 48 "0~99month" 49 "0~99month" 50 "0~99month" 51 "0~99month" 52 "0~99month" 53 "0~99month" 54 "0~99month" 55 "0~99month" 56 "0~99month" 57 "0~99month" 58 "0~99month" 59 "0~99month" 60 "0~99month" 61 "0~99month" 62 "0~99month" 63 "0~99month" 64 "0~99month" 65 "0~99month" 66 "0~99month" 67 "0~99month" 68 "0~99month" 69 "0~99month" 70 "0~99month" 71 "0~99month" 72 "0~99month" 73 "0~99month" 74 "0~99month" 75 "0~99month" 76 "0~99month" 77 "0~99month" 78 "0~99month" 79 "0~99month" 80 "0~99month" 81 "0~99month" 82 "0~99month" 83 "0~99month" 84 "0~99month" 85 "0~99month" 86 "0~99month" 87 "0~99month" 88 "0~99month" 89 "0~99month" 90 "0~99month" 91 "0~99month" 92 "0~99month" 93 "0~99month" 94 "0~99month" 95 "0~99month" 96 "0~99month" 97 "0~99month" 98 "0~99month" 99 "0~99month" 100 "Reserved" 101 "Reserved" 102 "Reserved" 103 "Reserved" 104 "Reserved" 105 "Reserved" 106 "Reserved" 107 "Reserved" 108 "Reserved" 109 "Reserved" 110 "Reserved" 111 "Reserved" 112 "Reserved" 113 "Reserved" 114 "Reserved" 115 "Reserved" 116 "Reserved" 117 "Reserved" 118 "Reserved" 119 "Reserved" 120 "Reserved" 121 "Reserved" 122 "Reserved" 123 "Reserved" 124 "Reserved" 125 "Reserved" 126 "Reserved" 127 "Invalid" ;
VAL_ 3221225472 CF_AVN_CluAutoInitFuelEconomy 0 "Default" 1 "Off" 2 "Driving" 3 "Refuel" 4 "Reserved" 5 "Reserved" 6 "Reserved" 7 "Invalid" ;
VAL_ 3221225472 CF_AVN_CluSubspeedOdometerDisp 0 "Default" 1 "Off" 2 "On" 3 "Invalid" ;
VAL_ 3221225472 CF_AVN_CluFuelEconUnit_mi 0 "Default" 1 "US gallon" 2 "UK gallon" 3 "Reserved" ;
VAL_ 3221225472 CF_AVN_CluFuelEconUnit_km 0 "Default" 1 "km_L" 2 "L_100km" 3 "Reserved" ;
VAL_ 3221225472 CF_AVN_CluUserSettingDistance 0 "0x0x0~0x1869F:0~9999km_mi" 99999 "0x0x0~0x1869F:0~9999km_mi" 131071 "Invalid" ;
VAL_ 3221225472 CF_AVN_CluVoiceVolume 0 "Default" 1 "Level0" 2 "Level1" 3 "Level2" 4 "Level3" 5 "Reserved" 6 "Reserved" 7 "Invalid" ;
VAL_ 3221225472 CF_AVN_EVReset 0 "Default" 1 "USM Reset" 2 "Reserved" 3 "Invalid" ;
VAL_ 3221225472 CF_AVN_UnitReset 0 "Default" 1 "Unit Reset" 2 "Reserved" 3 "Invalid" ;
VAL_ 3221225472 CF_AVN_IcyRoadWarn 0 "Default" 1 "Off" 2 "On" 3 "Invalid" ;
VAL_ 3221225472 CF_AVN_CluServiceReminderReset 0 "Default" 1 "Service Reminder Reset" 2 "Reserved" 3 "Invalid" ;
VAL_ 3221225472 CF_AVN_CluUSMReset 0 "Default" 1 "USM Reset" 2 "Reserved" 3 "Invalid" ;
VAL_ 3221225472 CF_AVN_CluServiceReminderSet 0 "Default" 1 "Off" 2 "On" 3 "Invalid" ;
VAL_ 3221225472 EPB_LmpStaDis 0 "Release State (EPB AVH)" 1 "Apply State (EPB)" 2 "Dynamic Braking (EPB) or Driver Action Requested" ;
VAL_ 3221225472 EPB_FlrLmpStaDis 0 "No failure" 1 "Failure detected or in diagnosis mode" 2 "EOL configuration not done or Emergency released" 3 "Reserved" 4 "Reserved" 5 "Reserved" 6 "Reserved" 7 "Reserved" 8 "Reserved" 9 "Reserved" 10 "Reserved" 11 "Reserved" 12 "Reserved" 13 "Reserved" 14 "Not used" 15 "Error Indicator" ;
VAL_ 3221225472 EPB_OutDataDis 0 "Off" 1 "EPB is in maintenance mode" 2 "Driver tries to DAR but safety condition is not satisfied" 3 "EPB applies by ESC request" 4 "Driver tries to DAR but safety condition is not satisfied for China" 5 "Driver tries to release EPB by operating the switch without pressing the brake pedal" ;
VAL_ 3221225472 EPB_AlrmReq 0 "Off" 1 "Comfortable tone (Sound once)" 2 "Uncomfortable tone" 3 "Error Indicator" ;
VAL_ 3221225472 EPB_SwPosSta 0 "Neutral position" 1 "Apply position (pull)" 2 "Release position (push)" 3 "Switch failure" ;
VAL_ 3221225472 EPB_RrBrkLtActvReq 0 "No request" 1 "Request to turn on rear brake lights" 2 "Not used" 3 "Error Indicator" ;
VAL_ 3221225472 EPB_FrcErrSta 0 "No failure" 1 "Clamp position not reached" 2 "Emergency release" 3 "Force not measurable (e.g. sensor failure)" ;
VAL_ 3221225472 EPB_DynmBrkFrcReqSigSta 0 "EPB_DynmBrkFrcReqSigSta signal is invalid" 1 "EPB_DynmBrkFrcReqSigSta signal is valid" 2 "Not used" 3 "Error Indicator" ;
VAL_ 3221225472 EPB_FrcSta 0 "See details in EPB_FRC_ERR" 1 "Released" 2 "Clamped" 3 "Clamping in progress" 4 "Releasing in progress" 5 "Dynamic braking via EPB" 6 "Releasing in progress by switch" 7 "Clamping in progress by switch" ;
VAL_ 3221225472 EPB_FlSta 0 "Not valid" 1 "EPB No failure" 2 "EPB Initialization State" 3 "EPB Diagnostic" 4 "EPB Temporarily Not Available" 5 "EPB Permanently Not Available" ;
VAL_ 3221225472 EPB_EscReqAckSta 0 "Idle / No acknowledge" 1 "Acknowledge for external ESC request" 2 "Not used" 3 "Error Indicator" ;
VAL_ 3221225472 EPB_DynmBrkFrcReq 0 "No Request" 1 "Dynamic braking request" 2 "Not used" 3 "Error Indicator" ;
VAL_ 3221225472 EPB_ActlFrcVal 0 "EPB Fully released" ;
VAL_ 3221225472 DoorLock_DrvrDrUnLkPsvAcsReq 0 "Off" 1 "Unlock" 2 "Not Used" 3 "Error Indicator" ;
VAL_ 3221225472 DoorLock_RmtKeyDrvrDrUnLkReq 0 "Off" 1 "Unlock" 2 "Not Used" 3 "Error Indicator" ;
VAL_ 3221225472 SEG_V2_Offset 0 "0x0x0~0x1FFE:Distance" 8190 "0x0x0~0x1FFE:Distance" 8191 "Invalid" ;
VAL_ 3221225472 SEG_V2_PathIndex 0 "Unknown" 1 "Reserved" 2 "Reserved" 3 "Reserved" 4 "Reserved" 5 "Reserved" 6 "Reserved" 7 "Reserved" 8 "General Path Index" 9 "General Path Index" 10 "General Path Index" 11 "General Path Index" 12 "General Path Index" 13 "General Path Index" 14 "General Path Index" 15 "General Path Index" 16 "General Path Index" 17 "General Path Index" 18 "General Path Index" 19 "General Path Index" 20 "General Path Index" 21 "General Path Index" 22 "General Path Index" 23 "General Path Index" 24 "General Path Index" 25 "General Path Index" 26 "General Path Index" 27 "General Path Index" 28 "General Path Index" 29 "General Path Index" 30 "General Path Index" 31 "General Path Index" 32 "General Path Index" 33 "General Path Index" 34 "General Path Index" 35 "General Path Index" 36 "General Path Index" 37 "General Path Index" 38 "General Path Index" 39 "General Path Index" 40 "General Path Index" 41 "General Path Index" 42 "General Path Index" 43 "General Path Index" 44 "General Path Index" 45 "General Path Index" 46 "General Path Index" 47 "General Path Index" 48 "General Path Index" 49 "General Path Index" 50 "General Path Index" 51 "General Path Index" 52 "General Path Index" 53 "General Path Index" 54 "General Path Index" 55 "General Path Index" 56 "General Path Index" 57 "General Path Index" 58 "General Path Index" 59 "General Path Index" 60 "General Path Index" 61 "General Path Index" 62 "General Path Index" 63 "General Path Index" ;
VAL_ 3221225472 SEG_V2_CyclicCounter 0 "Cyclic Counter" 1 "Cyclic Counter" 2 "Cyclic Counter" 3 "Cyclic Counter" ;
VAL_ 3221225472 SEG_V2_Retransmission 0 "False" 1 "True" ;
VAL_ 3221225472 SEG_V2_CalculatedRoute 0 "Not Calculated Route(MPP)" 1 "Part of Calculated Route" 2 "Off Route or Recalculating" 3 "Invalid" ;
VAL_ 3221225472 SEG_V2_FuncRoadClass 0 "Unknown" 1 "Freeway" 2 "Arterial(City freeway)" 3 "County" 4 "Collector" 5 "Local" 6 "Etc(ferry, unpaved)" 7 "Invalid" ;
VAL_ 3221225472 SEG_V2_SpeedLimit 0 "Unknown" 1 "Under 5kph(mph)" 2 "7kph(mph)" 3 "10kph(mph)" 4 "15kph(mph)" 5 "20kph(mph)" 6 "25kph(mph)" 7 "30kph(mph)" 8 "35kph(mph)" 9 "40kph(mph)" 10 "45kph(mph)" 11 "50kph(mph)" 12 "55kph(mph)" 13 "60kph(mph)" 14 "65kph(mph)" 15 "70kph(mph)" 16 "75kph(mph)" 17 "80kph(mph)" 18 "85kph(mph)" 19 "90kph(mph)" 20 "95kph(mph)" 21 "100kph(mph)" 22 "105kph(mph)" 23 "110kph(mph)" 24 "115kph(mph)" 25 "120kph(mph)" 26 "125kph(mph)" 27 "130kph(mph)" 28 "135kph(mph)" 29 "140kph(mph)" 30 "Unlimited" 31 "Invalid" ;
VAL_ 3221225472 SEG_V2_FormOfWay 0 "Unkonwn" 1 "Main road(nondisjunction)" 2 "Main road(disjunction)" 3 "JC" 4 "Plural Junction M" 5 "IC" 6 "Reserved" 7 "Service Area" 8 "Reserved" 9 "Roundabout" 10 "P turn" 11 "U trun" 12 "Pedestrian" 13 "Frontage Road" 14 "Intersection internal(Plural Junction)" 15 "Invalid" ;
VAL_ 3221225472 SEG_V2_DirectionLanes 0 "Unknown" 1 "Lane count" 2 "Lane count" 3 "Lane count" 4 "Lane count" 5 "Lane count" 6 "Lane count" 7 "Lane count" 8 "Lane count" 9 "Lane count" 10 "Lane count" 11 "Lane count" 12 "Lane count" 13 "Lane count" 14 "Lane count" 15 "Invalid" ;
VAL_ 3221225472 SEG_V2_SpeedLimitUnder5 0 "0kph(mph)" 1 "1kph(mph)" 2 "2kph(mph)" 3 "3kph(mph)" 4 "4kph(mph)" 5 "reserved" 6 "reserved" 7 "Invalid" ;
VAL_ 3221225472 FR_C_RDR_RR_C_RDR_FCA_Plus_Sta 0 "Default" 1 "���� �������� ȸ�ǺҰ�" 2 "���� �������� ȸ�ǺҰ�" 3 "���� �������� ����/���� ���� ȸ�� �Ұ�" ;
VAL_ 3221225472 RCCW_Sta 0 "Default" 1 "RCCW is Off" 2 "RCCW Passive" 3 "RCCW Active" 4 "RCCW Failure" 5 "RCCW Blockage" 6 "RCCW Minor Failure" 7 "Reserved" 8 "Reserved" 9 "Reserved" 10 "Reserved" 11 "Reserved" 12 "Reserved" 13 "Reserved" 14 "Reserved" ;
VAL_ 3221225472 RCCW_OnOffEquipSt 0 "Default" 1 "Off" 2 "Warning" 3 "Invalid" ;
VAL_ 3221225472 RCCW_LftIndSta 0 "Indicator output off" 1 "Indicator on (information)" 2 "Reserved" 3 "Indicator output check" ;
VAL_ 3221225472 RCCW_RtIndSta 0 "Indicator output off" 1 "Indicator on (information)" 2 "Reserved" 3 "Indicator output check" ;
VAL_ 3221225472 RCCW_LftSndWrngSta 0 "Speaker is Off" 1 "Speaker On" 2 "Not used" 3 "Error Indicator" ;
VAL_ 3221225472 RCCW_RtSndWrngSta 0 "Speaker is Off" 1 "Speaker On" 2 "Not used" 3 "Error Indicator" ;
VAL_ 3221225472 RCCA_BrkCmdSta 0 "RCCA Brake off" 1 "RCCA Brake on" 2 "Not used" 3 "Error Indicator" ;
VAL_ 3221225472 RCCA_LftWrngSta 0 "RCCA Left Warning is Off" 1 "RCCA Left Warning is On" 2 "RCCA Left Warning is Ended" 3 "Error Indicator" ;
VAL_ 3221225472 RCCA_RtWrngSta 0 "RCCA Right Warning is Off" 1 "RCCA Right Warning is On" 2 "RCCA Right Warning is Ended" 3 "Error Indicator" ;
VAL_ 3221225472 RCCA_FuncStat 0 "ESC Normal" 1 "Not support (ESC failure)" 2 "Not used" 3 "Error Indicator" ;
VAL_ 3221225472 RCCA_Sta 0 "Default" 1 "RCCA is Off" 2 "RCCA Passive" 3 "RCCA Active" 4 "RCCA Failure" 5 "RCCA Blockage" 6 "RCCA Minor Failure" 7 "Reserved" 8 "Reserved" 9 "Reserved" 10 "Reserved" 11 "Reserved" 12 "Reserved" 13 "Reserved" 14 "Reserved" ;
VAL_ 3221225472 RCCA_OnOffEquipSt 0 "Default" 1 "Off" 2 "Assist" 3 "Invalid" ;
VAL_ 3221225472 SEA_Sta 0 "Default" 1 "SEA Function is off" 2 "SEA Function is passive" 3 "SEA Function active" 4 "SEA Function failure" 5 "SEA Function Blockage" 6 "SEA Function minor failure" 7 "Reserved" 8 "Reserved" 9 "Reserved" 10 "Reserved" 11 "Reserved" 12 "Reserved" 13 "Reserved" 14 "Reserved" ;
VAL_ 3221225472 SEA_OnOffEquipSta 0 "Default" 1 "Off" 2 "Warning" 3 "Invalid" ;
VAL_ 3221225472 SEA_LftWrngSta 0 "SEA Left Warning OFF" 1 "SEA Left Warning ON" 2 "Not used" 3 "Error Indicator" ;
VAL_ 3221225472 SEA_RtWrngSta 0 "SEA Right Warning OFF" 1 "SEA Right Warning ON" 2 "Not used" 3 "Error Indicator" ;
VAL_ 3221225472 Wiper_FrWiperSwSta 0 "Wiper Sw Off" 1 "Wiper Int or Auto Sw On(Refer to C_RainSnsOption)" 2 "Wiper Low Sw On" 3 "Wiper High Sw On" 4 "Reserved" 5 "Reserved" 6 "Not Used" 7 "Error Indicator" ;
VAL_ 3221225472 Wiper_IntStepSta 0 "STEP1(SLOW)" 1 "STEP2" 2 "STEP3" 3 "STEP4" 4 "STEP5(FAST)" ;
VAL_ 3221225472 Wiper_MstSwSta 0 "Off" 1 "On" 2 "Not Used" 3 "Error Indicator" ;
VAL_ 3221225472 Wiper_FrWiperWshSwSta 0 "Off" 1 "On" 2 "Not Used" 3 "Error Indicator" ;
VAL_ 3221225472 MFSW_Info 0 "Off" 1 "ON(CAN Type)" 2 "Not Used" 3 "Error Indicator" ;
VAL_ 3221225472 PROLONG_V2_Value 0 "0x0x0~0xFFFFFFFE:Profile value at Offset" 2147483647 "0x0x0~0xFFFFFFFE:Profile value at Offset" 2147483647 "Invalid" ;
VAL_ 3221225472 PROLONG_V2_Offset 0 "0x0x0~0x1FFE:Distance" 8190 "0x0x0~0x1FFE:Distance" 8191 "Invalid" ;
VAL_ 3221225472 PROLONG_V2_CyclicCounter 0 "Cyclic Counter" 1 "Cyclic Counter" 2 "Cyclic Counter" 3 "Cyclic Counter" ;
VAL_ 3221225472 PROLONG_V2_Update 0 "False" 1 "True" ;
VAL_ 3221225472 PROLONG_V2_PathIndex 0 "Unknown" 1 "Reserved" 2 "Reserved" 3 "Reserved" 4 "Reserved" 5 "Reserved" 6 "Reserved" 7 "Reserved" 8 "General Path Index" 9 "General Path Index" 10 "General Path Index" 11 "General Path Index" 12 "General Path Index" 13 "General Path Index" 14 "General Path Index" 15 "General Path Index" 16 "General Path Index" 17 "General Path Index" 18 "General Path Index" 19 "General Path Index" 20 "General Path Index" 21 "General Path Index" 22 "General Path Index" 23 "General Path Index" 24 "General Path Index" 25 "General Path Index" 26 "General Path Index" 27 "General Path Index" 28 "General Path Index" 29 "General Path Index" 30 "General Path Index" 31 "General Path Index" 32 "General Path Index" 33 "General Path Index" 34 "General Path Index" 35 "General Path Index" 36 "General Path Index" 37 "General Path Index" 38 "General Path Index" 39 "General Path Index" 40 "General Path Index" 41 "General Path Index" 42 "General Path Index" 43 "General Path Index" 44 "General Path Index" 45 "General Path Index" 46 "General Path Index" 47 "General Path Index" 48 "General Path Index" 49 "General Path Index" 50 "General Path Index" 51 "General Path Index" 52 "General Path Index" 53 "General Path Index" 54 "General Path Index" 55 "General Path Index" 56 "General Path Index" 57 "General Path Index" 58 "General Path Index" 59 "General Path Index" 60 "General Path Index" 61 "General Path Index" 62 "General Path Index" 63 "General Path Index" ;
VAL_ 3221225472 PROLONG_V2_ProfileType 0 "Invalid" 1 "Longitude" 2 "Latitude" 3 "Altitude" 4 "Control Point Longitude(Bezier)" 5 "Control Point Latitude(Bezier)" 6 "Control Point Altitude(Bezier)" 7 "Link Identifier" 8 "Traffic Sign" 9 "Reserved for standard type" 10 "Reserved for standard type" 11 "Reserved for standard type" 12 "Reserved for standard type" 13 "Reserved for standard type" 14 "Reserved for standard type" 15 "Reserved for standard type" 16 "Alert Information Spot" 17 "Reserved for system specific types" 18 "Reserved for system specific types" 19 "Reserved for system specific types" 20 "Reserved for system specific types" 21 "Reserved for system specific types" 22 "Reserved for system specific types" 23 "Reserved for system specific types" 24 "Reserved for system specific types" 25 "Reserved for system specific types" 26 "Reserved for system specific types" 27 "Reserved for system specific types" 28 "Reserved for system specific types" 29 "Reserved for system specific types" 30 "Reserved for system specific types" 31 "Reserved for system specific types" ;
VAL_ 3221225472 VCU_RspaOpSta 1 "Init" 2 "New Start" 3 "Ready OK" 5 "Assist OK" 6 "Assist Fail" 7 "Abort" 8 "Ready Fail" ;
VAL_ 3221225472 VCU_RspaCanFailSta 0 "RSPA not CAN Fail" 1 "RSPA CAN Fail" ;
VAL_ 3221225472 VCU_BrkLampOnReq 0 "None" 1 "Lamp On Request" 2 "Not used" 3 "Error Indicator" ;
VAL_ 3221225472 VCU_RegenEnaFrntSta 0 "None" 1 "Regen Brake Possible" 2 "Not used" 3 "Error Indicator" ;
VAL_ 3221225472 VCU_RegenEnaRearSta 0 "None" 1 "Regen Brake Possible" 2 "Not used" 3 "Error Indicator" ;
VAL_ 3221225472 VCU_4wdModSta 0 "2WD" 1 "4WD" 2 "Not used" 3 "Error Indicator" ;
VAL_ 3221225472 VCU_EpbEngageReq 0 "Default" 1 "EPB Request" 2 "Not used" 3 "Error Indicator" ;
VAL_ 293 SAS_AnglVal 32767 "Error Indicator" ;
VAL_ 293 SAS_SpdVal 255 "Error Indicator" ;
VAL_ 101 IEB_AbsNGearReq 0 "Inactive" 1 "N Gear position Request Active" 2 "Not used" 3 "Error Indicator" ;
VAL_ 101 IEB_EstBrkPdlValVldSta 0 "Invalid" 1 "Valid" 2 "Not used" 3 "Error Indicator" ;
VAL_ 101 IEB_InhbtTrnstnTo4wd_Req 0 "No Request" 1 "Inhibit Transition To 4WD" 2 "Not used" 3 "Not used" ;
VAL_ 101 IEB_TCS_Req 0 "TCS control is not active" 1 "TCS control is active" 2 "Not used" 3 "Not used" ;
VAL_ 101 IEB_RSC_Req 0 "RSC is not active" 1 "RSC is active" 2 "Not used" 3 "Not used" ;
VAL_ 101 TCS_TqFlag_Frnt 0 "Positive" 1 "Negative" ;
VAL_ 101 TCS_TqFlag_Rear 0 "Positive" 1 "Negative" ;
VAL_ 101 RSC_TqFlag_Frnt 0 "Positive" 1 "Negative" ;
VAL_ 101 RSC_TqFlag_Rear 0 "Positive" 1 "Negative" ;
VAL_ 101 IEB_SrvLmpDis 0 "AHB Service Lamp is Off" 1 "AHB Service Lamp is On" 2 "AHB Service Lamp is BLINKING(2HZ)" 3 "Error Indicator" ;
VAL_ 101 IEB_DfctvSta 0 "AHB is normal mode" 1 "AHB is degraded mode" 2 "AHB is defective mode" 3 "Error Indicator" ;
VAL_ 101 IEB_ActvSta 0 "All Control Inactive" 1 "Charging Active" 2 "AHB Control Active" 3 "Chaging Active + AHB Control Active" ;
VAL_ 101 IEB_DiagSta 0 "AHB is not diagnostic mode" 1 "AHB is diagnostic mode" 2 "Not used" 3 "Error Indicator" ;
VAL_ 101 IEB_WrngLmpDis 0 "AHB Warning Lamp is Off" 1 "AHB Warning Lamp is On" 2 "Not used" 3 "Error Indicator" ;
VAL_ 101 IEB_MILReq 0 "No Request" 1 "MIL On Request" 2 "Reserved" 3 "Reserved" ;
VAL_ 101 IEB_BrkActvSta 0 "ECU does not support this function." 1 "Brake switch is not pressed (OFF)" 2 "Brake switch is pressed (ON)" 3 "Brake switch failure" ;
VAL_ 101 IEB_PdlTrvlSnsrFailSta 0 "Normal" 1 "Fail" 2 "Not used" 3 "Error Indicator" ;
VAL_ 101 IEB_PdlCalibSta 0 "Not complete" 1 "Complete" 2 "Not used" 3 "Error Indicator" ;
VAL_ 101 IEB_BzrSta 0 "Buzzer is Off" 1 "Buzzer is On" 2 "Not used" 3 "Error Indicator" ;
VAL_ 101 IEB_Sta 0 "Not Ready" 1 "Ready" 2 "Ready (Front only) & Not Ready(Rear)" 3 "Ready (Rear only) & Not Ready(Front)" ;
VAL_ 101 IEB_SnsrFailSta 0 "Normal" 1 "Fail" 2 "Not used" 3 "Error Indicator" ;
VAL_ 101 IEB_RbsWrngLmpSta 0 "RBS Warning Lamp OFF" 1 "RBS Warning Lamp ON" 2 "Not used" 3 "Error Indicator" ;
VAL_ 101 IEB_VacSysDfctvSta 0 "Vacuum pump NOT defective" 1 "Vacuum pump defective (failed)" 2 "Not used" 3 "Error Indicator" ;
VAL_ 418 CLU_DtntOutSta 0 "Detent Off" 1 "Detent On" 2 "Not used" 3 "Error Indicator" ;
VAL_ 418 CLU_SpdUnitTyp 0 "km/h" 1 "MPH" 2 "Not used" 3 "Error Indicator" ;
VAL_ 418 CLU_DisSpdDcmlVal 0 "0" 1 "0.125" 2 "0.250" 3 "0.375" ;
VAL_ 418 CLU_RhstaLvlSta 0 "Reserved" 1 "Step 1" 2 "Step 2" 3 "Step 3" 4 "Step 4" 5 "Step 5" 6 "Step 6" 7 "Step 7" 8 "Step 8" 9 "Step 9" 10 "Step 10" 11 "Step 11" 12 "Step 12" 13 "Step 13" 14 "Step 14" 15 "Step 15" 16 "Step 16" 17 "Step 17" 18 "Step 18" 19 "Step 19" 20 "Step 20 (Reset Value)" 21 "Step 21 (Detent)" ;
VAL_ 418 CLU_DisSpdVal 1023 "Error" ;
VAL_ 418 CLU_DisTyp 0 "Default" 1 "Type1" 2 "Type2" 3 "Invalid" ;
VAL_ 418 CLU_DisSpdVal_KPH 511 "Error" ;
